VERSION "HNNBNNNYNNNNNNNNNNNNNNNNNNNNNNNNNNNNNNNNNN/4/%%%/4/'%**4NNN///"

NS_ :

BS_:

BU_: Allrad_Haldex AreaView_MQB BAP_Tester Bremse_ABS_MK100 Bremse_ESP_EPB_EBC460Vi Bremse_ESP_EPB_MK100 Bremse_ESP_MK100 Daempfer Gateway_MQB Lenkhilfe_EPS PDC PDC_PLA

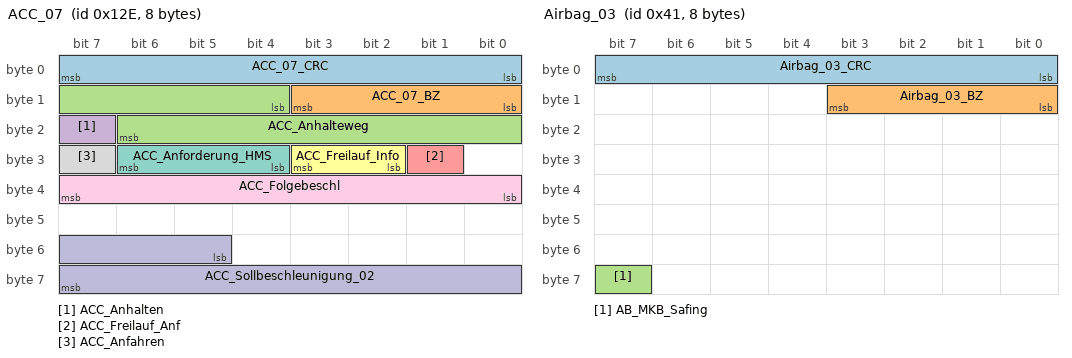
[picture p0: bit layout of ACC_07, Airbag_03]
BO_ 302 ACC_07: 8 Gateway_MQB
 SG_ ACC_07_CRC : 0|8@1+ (1,0) [0|255] ""  Bremse_ESP_EPB_EBC460Vi,Bremse_ESP_EPB_MK100,Bremse_ESP_MK100
 SG_ ACC_07_BZ : 8|4@1+ (1,0) [0|15] ""  Bremse_ESP_EPB_EBC460Vi,Bremse_ESP_EPB_MK100,Bremse_ESP_MK100
 SG_ ACC_Anhalteweg : 12|11@1+ (0.01,0) [0.00|20.45] "Unit_Meter"  Bremse_ESP_EPB_EBC460Vi,Bremse_ESP_EPB_MK100,Bremse_ESP_MK100
 SG_ ACC_Anhalten : 23|1@1+ (1.0,0.0) [0.0|1] ""  Bremse_ESP_EPB_EBC460Vi,Bremse_ESP_EPB_MK100,Bremse_ESP_MK100
 SG_ ACC_Freilauf_Anf : 25|1@1+ (1.0,0.0) [0.0|1] ""  Vector__XXX
 SG_ ACC_Freilauf_Info : 26|2@1+ (1.0,0.0) [0.0|3] ""  Vector__XXX
 SG_ ACC_Anforderung_HMS : 28|3@1+ (1.0,0.0) [0.0|7] ""  Vector__XXX
 SG_ ACC_Anfahren : 31|1@1+ (1.0,0.0) [0.0|1] ""  Bremse_ESP_EPB_EBC460Vi,Bremse_ESP_EPB_MK100,Bremse_ESP_MK100
 SG_ ACC_Folgebeschl : 32|8@1+ (0.03,-4.6) [-4.60|2.99] "Unit_MeterPerSeconSquar"  Vector__XXX
 SG_ ACC_Sollbeschleunigung_02 : 53|11@1+ (0.005,-7.22) [-7.220|3.005] "Unit_MeterPerSeconSquar"  Daempfer

BO_ 279 ACC_10: 8 Gateway_MQB
 SG_ ACC_10_CRC : 0|8@1+ (1,0) [0|255] ""  Bremse_ESP_EPB_EBC460Vi,Bremse_ESP_EPB_MK100,Bremse_ESP_MK100
 SG_ ACC_10_BZ : 8|4@1+ (1,0) [0|15] ""  Bremse_ESP_EPB_EBC460Vi,Bremse_ESP_EPB_MK100,Bremse_ESP_MK100
 SG_ AWV1_Anf_Prefill : 16|1@1+ (1.0,0.0) [0.0|1] ""  Bremse_ESP_EPB_EBC460Vi,Bremse_ESP_EPB_MK100,Bremse_ESP_MK100
 SG_ ANB_CM_Info : 17|1@1+ (1.0,0.0) [0.0|1] ""  Bremse_ESP_EPB_EBC460Vi,Bremse_ESP_EPB_MK100,Bremse_ESP_MK100
 SG_ AWV2_Freigabe : 18|1@1+ (1.0,0.0) [0.0|1] ""  Bremse_ESP_EPB_EBC460Vi,Bremse_ESP_EPB_MK100,Bremse_ESP_MK100
 SG_ AWV1_HBA_Param : 19|2@1+ (1.0,0.0) [0.0|3] ""  Bremse_ESP_EPB_EBC460Vi,Bremse_ESP_EPB_MK100,Bremse_ESP_MK100
 SG_ AWV2_Ruckprofil : 21|3@1+ (1,0) [0|7] ""  Bremse_ESP_EPB_EBC460Vi,Bremse_ESP_EPB_MK100,Bremse_ESP_MK100
 SG_ AWV2_Priowarnung : 24|1@1+ (1.0,0.0) [0.0|1] ""  Vector__XXX
 SG_ ANB_CM_Anforderung : 25|1@1+ (1.0,0.0) [0.0|1] ""  Bremse_ESP_EPB_EBC460Vi,Bremse_ESP_EPB_MK100,Bremse_ESP_MK100
 SG_ ANB_Info_Teilbremsung : 26|1@1+ (1.0,0.0) [0.0|1] ""  Bremse_ESP_EPB_MK100,Bremse_ESP_MK100
 SG_ ANB_Notfallblinken : 27|1@1+ (1.0,0.0) [0.0|1] ""  Vector__XXX
 SG_ ANB_Teilbremsung_Freigabe : 28|1@1+ (1.0,0.0) [0.0|1] ""  Bremse_ESP_EPB_EBC460Vi,Bremse_ESP_EPB_MK100,Bremse_ESP_MK100,Daempfer
 SG_ ANB_Zielbrems_Teilbrems_Verz_Anf : 29|10@1+ (0.024,-20.016) [-20.016|4.536] "Unit_MeterPerSeconSquar"  Bremse_ESP_EPB_EBC460Vi,Bremse_ESP_EPB_MK100,Bremse_ESP_MK100,Daempfer
 SG_ ANB_Zielbremsung_Freigabe : 39|1@1+ (1.0,0.0) [0.0|1] ""  Bremse_ESP_EPB_EBC460Vi,Bremse_ESP_EPB_MK100,Bremse_ESP_MK100,Daempfer
 SG_ AWV_Vorstufe : 40|1@1+ (1.0,0.0) [0.0|1] ""  Bremse_ESP_EPB_EBC460Vi,Bremse_ESP_EPB_MK100,Bremse_ESP_MK100
 SG_ AWV_Halten : 41|1@1+ (1.0,0.0) [0.0|1] ""  Bremse_ESP_EPB_EBC460Vi,Bremse_ESP_EPB_MK100,Bremse_ESP_MK100
 SG_ AWV_CityANB_Auspraegung : 42|1@1+ (1.0,0.0) [0.0|1] ""  Bremse_ESP_EPB_EBC460Vi,Bremse_ESP_EPB_MK100,Bremse_ESP_MK100
 SG_ PCF_Freigabe : 43|1@1+ (1.0,0.0) [0.0|1] ""  Vector__XXX
 SG_ AWV1_ECD_Anlauf : 44|1@1+ (1.0,0.0) [0.0|1] ""  Bremse_ESP_EPB_EBC460Vi,Bremse_ESP_EPB_MK100,Bremse_ESP_MK100
 SG_ PCF_Time_to_collision : 56|8@1+ (0.01,0) [0.00|2.50] "Unit_Secon"  Vector__XXX

BO_ 64 Airbag_01: 8 Gateway_MQB
 SG_ Airbag_01_CRC : 0|8@1+ (1,0) [0|255] ""  Bremse_ABS_MK100,Bremse_ESP_EPB_EBC460Vi,Bremse_ESP_EPB_MK100,Bremse_ESP_MK100
 SG_ Airbag_01_BZ : 8|4@1+ (1,0) [0|15] ""  Bremse_ABS_MK100,Bremse_ESP_EPB_EBC460Vi,Bremse_ESP_EPB_MK100,Bremse_ESP_MK100
 SG_ AB_RGS_Anst : 12|4@1+ (1.0,0.0) [0.0|15] ""  Vector__XXX
 SG_ AB_Front_Crash : 16|1@1+ (1.0,0.0) [0.0|1] ""  Bremse_ESP_EPB_EBC460Vi,Bremse_ESP_EPB_MK100
 SG_ AB_Heck_Crash : 17|1@1+ (1.0,0.0) [0.0|1] ""  Bremse_ESP_EPB_EBC460Vi,Bremse_ESP_EPB_MK100
 SG_ AB_SF_Crash : 18|1@1+ (1.0,0.0) [0.0|1] ""  Bremse_ESP_EPB_EBC460Vi,Bremse_ESP_EPB_MK100
 SG_ AB_SB_Crash : 19|1@1+ (1.0,0.0) [0.0|1] ""  Bremse_ESP_EPB_EBC460Vi,Bremse_ESP_EPB_MK100
 SG_ AB_Rollover_Crash : 20|1@1+ (1.0,0.0) [0.0|1] ""  Bremse_ABS_MK100,Bremse_ESP_EPB_EBC460Vi,Bremse_ESP_EPB_MK100,Bremse_ESP_MK100
 SG_ AB_Crash_Int : 21|3@1+ (1.0,0.0) [0.0|7] ""  Bremse_ABS_MK100,Bremse_ESP_EPB_EBC460Vi,Bremse_ESP_EPB_MK100,Bremse_ESP_MK100
 SG_ AB_Lampe : 24|1@1+ (1.0,0.0) [0.0|1] ""  Vector__XXX
 SG_ AB_Deaktiviert : 25|1@1+ (1.0,0.0) [0.0|1] ""  Vector__XXX
 SG_ AB_VB_deaktiviert : 26|1@1+ (1.0,0.0) [0.0|1] ""  Vector__XXX
 SG_ AB_Systemfehler : 27|1@1+ (1.0,0.0) [0.0|1] ""  Vector__XXX
 SG_ AB_Diagnose : 28|1@1+ (1.0,0.0) [0.0|1] ""  Vector__XXX
 SG_ AB_Stellgliedtest : 29|1@1+ (1.0,0.0) [0.0|1] ""  Vector__XXX
 SG_ AB_Erh_Auf_VB : 30|2@1+ (1.0,0.0) [0.0|3] ""  Vector__XXX
 SG_ AB_Gurtwarn_VF : 32|1@1+ (1.0,0.0) [0.0|1] ""  PDC,PDC_PLA
 SG_ AB_Gurtwarn_VB : 33|1@1+ (1.0,0.0) [0.0|1] ""  PDC,PDC_PLA
 SG_ AB_Anzeige_Fussg : 34|2@1+ (1.0,0.0) [0.0|3] ""  Vector__XXX
 SG_ AB_Texte_AKS : 36|2@1+ (1.0,0.0) [0.0|3] ""  Vector__XXX
 SG_ AB_PAO_Leuchte_Anf : 38|1@1+ (1.0,0.0) [0.0|1] ""  Vector__XXX
 SG_ AB_MKB_gueltig : 39|1@1+ (1.0,0.0) [0.0|1] ""  Bremse_ESP_EPB_EBC460Vi,Bremse_ESP_EPB_MK100,Bremse_ESP_MK100
 SG_ AB_MKB_Anforderung : 40|1@1+ (1.0,0.0) [0.0|1] ""  Bremse_ESP_EPB_EBC460Vi,Bremse_ESP_EPB_MK100,Bremse_ESP_MK100
 SG_ AB_Versorgungsspannung : 41|1@1+ (1.0,0.0) [0.0|1] ""  Vector__XXX
 SG_ AB_Deaktivierung_HV : 42|3@1+ (1.0,0.0) [0.0|7] ""  Vector__XXX
 SG_ AB_EDR_Trigger : 45|2@1+ (1.0,0.0) [0.0|3] ""  Vector__XXX
 SG_ SC_Masterzeit_Offset : 53|2@1+ (5.08,0) [0.00|15.24] "Unit_Secon"  Bremse_ESP_EPB_EBC460Vi,Bremse_ESP_EPB_MK100,Bremse_ESP_MK100,PDC_PLA
 SG_ SC_Masterzeit : 57|7@1+ (0.04,0) [0.00|5.04] "Unit_Secon"  Bremse_ESP_EPB_EBC460Vi,Bremse_ESP_EPB_MK100,Bremse_ESP_MK100,PDC_PLA

BO_ 1312 Airbag_02: 8 Gateway_MQB
 SG_ Airbag_02_CRC : 0|8@1+ (1,0) [0|255] ""  Vector__XXX
 SG_ Airbag_02_BZ : 8|4@1+ (1,0) [0|15] ""  Vector__XXX
 SG_ LoGeWa_Event_Kombiwarnung : 12|4@1+ (1.0,0.0) [0.0|15] ""  Vector__XXX
 SG_ AB_Anforderung_eCall : 16|1@1+ (1.0,0.0) [0.0|1] ""  Vector__XXX
 SG_ AB_Anprall_Seite_Beifahrer : 17|1@1+ (1.0,0.0) [0.0|1] ""  Vector__XXX
 SG_ AB_Anprall_Rollover : 18|1@1+ (1.0,0.0) [0.0|1] ""  Vector__XXX
 SG_ AB_Anprall_FGS : 19|1@1+ (1.0,0.0) [0.0|1] ""  Vector__XXX
 SG_ AB_Anprall_Front_Beifahrer : 20|1@1+ (1.0,0.0) [0.0|1] ""  Vector__XXX
 SG_ AB_Anprall_Front_Fahrer : 21|1@1+ (1.0,0.0) [0.0|1] ""  Vector__XXX
 SG_ AB_Anprall_Heck_Beifahrer : 22|1@1+ (1.0,0.0) [0.0|1] ""  Vector__XXX
 SG_ AB_Anprall_Heck_Fahrer : 23|1@1+ (1.0,0.0) [0.0|1] ""  Vector__XXX
 SG_ AB_Wickelklappung_Reihe2_MI : 24|2@1+ (1.0,0.0) [0.0|3] ""  Vector__XXX
 SG_ AB_Belegung_VB : 26|2@1+ (1.0,0.0) [0.0|3] ""  PDC,PDC_PLA
 SG_ AB_Abschaltanf_SIH_BF : 28|1@1+ (1.0,0.0) [0.0|1] ""  Vector__XXX
 SG_ AB_Anprall_Seite_Fahrer : 29|1@1+ (1.0,0.0) [0.0|1] ""  Vector__XXX
 SG_ SC_PAO_Schriftzug_Anf : 30|2@1+ (1.0,0.0) [0.0|3] ""  Vector__XXX
 SG_ SC_PAO_ON_Anf : 32|2@1+ (1.0,0.0) [0.0|3] ""  Vector__XXX
 SG_ SC_PAO_OFF_Anf : 34|2@1+ (1.0,0.0) [0.0|3] ""  Vector__XXX
 SG_ AB_Crashschwere : 36|3@1+ (1.0,0.0) [0.0|7] ""  Vector__XXX
 SG_ AB_Anforderung_USM : 39|1@1+ (1.0,0.0) [0.0|1] ""  Vector__XXX
 SG_ AB_Gurtschloss_FA : 40|2@1+ (1.0,0.0) [0.0|3] ""  Bremse_ABS_MK100,Bremse_ESP_EPB_EBC460Vi,Bremse_ESP_EPB_MK100,Bremse_ESP_MK100,PDC,PDC_PLA
 SG_ AB_Gurtschloss_BF : 42|2@1+ (1.0,0.0) [0.0|3] ""  PDC,PDC_PLA
 SG_ AB_Gurtschloss_Reihe2_FA : 44|2@1+ (1.0,0.0) [0.0|3] ""  PDC
 SG_ AB_Gurtschloss_Reihe2_MI : 46|2@1+ (1.0,0.0) [0.0|3] ""  PDC
 SG_ AB_Gurtschloss_Reihe2_BF : 48|2@1+ (1.0,0.0) [0.0|3] ""  PDC
 SG_ AB_Gurtschloss_Reihe3_FA : 50|2@1+ (1.0,0.0) [0.0|3] ""  PDC
 SG_ AB_Gurtschloss_Reihe3_MI : 52|2@1+ (1.0,0.0) [0.0|3] ""  PDC
 SG_ AB_Gurtschloss_Reihe3_BF : 54|2@1+ (1.0,0.0) [0.0|3] ""  PDC
 SG_ AB_Sitzpos_Sens_FA : 56|2@1+ (1.0,0.0) [0.0|3] ""  Vector__XXX
 SG_ AB_Sitzpos_Sens_BF : 58|2@1+ (1.0,0.0) [0.0|3] ""  Vector__XXX
 SG_ AB_Wickelklappung_Reihe2_BF : 60|2@1+ (1.0,0.0) [0.0|3] ""  Vector__XXX
 SG_ AB_Wickelklappung_Reihe2_FA : 62|2@1+ (1.0,0.0) [0.0|3] ""  Vector__XXX

BO_ 65 Airbag_03: 8 Gateway_MQB
 SG_ Airbag_03_CRC : 0|8@1+ (1,0) [0|255] ""  Bremse_ESP_EPB_EBC460Vi,Bremse_ESP_EPB_MK100,Bremse_ESP_MK100
 SG_ Airbag_03_BZ : 8|4@1+ (1,0) [0|15] ""  Bremse_ESP_EPB_EBC460Vi,Bremse_ESP_EPB_MK100,Bremse_ESP_MK100
 SG_ AB_MKB_Safing : 63|1@1+ (1.0,0.0) [0.0|1] ""  Bremse_ESP_EPB_EBC460Vi,Bremse_ESP_EPB_MK100,Bremse_ESP_MK100

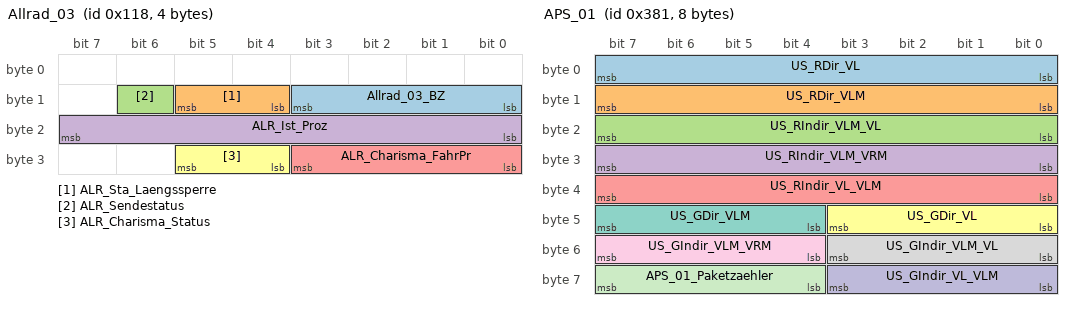
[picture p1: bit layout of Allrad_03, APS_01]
BO_ 280 Allrad_03: 4 Allrad_Haldex
 SG_ Allrad_03_BZ : 8|4@1+ (1,0) [0|15] ""  Bremse_ESP_EPB_EBC460Vi,Bremse_ESP_EPB_MK100,Bremse_ESP_MK100,Gateway_MQB
 SG_ ALR_Sta_Laengssperre : 12|2@1+ (1.0,0.0) [0.0|3] ""  Bremse_ESP_EPB_EBC460Vi,Bremse_ESP_EPB_MK100,Bremse_ESP_MK100,Gateway_MQB
 SG_ ALR_Sendestatus : 14|1@1+ (1.0,0.0) [0.0|1] ""  Gateway_MQB
 SG_ ALR_Ist_Proz : 16|8@1+ (0.4,0) [0.0|100.0] "Unit_PerCent"  Bremse_ESP_EPB_EBC460Vi,Bremse_ESP_EPB_MK100,Bremse_ESP_MK100,Gateway_MQB
 SG_ ALR_Charisma_FahrPr : 24|4@1+ (1.0,0.0) [0.0|15] ""  Gateway_MQB
 SG_ ALR_Charisma_Status : 28|2@1+ (1.0,0.0) [0.0|3] ""  Gateway_MQB

BO_ 897 APS_01: 8 PDC
 SG_ US_RDir_VL : 0|8@1+ (0.02,0) [0.00|5.10] "Unit_Meter"  Gateway_MQB
 SG_ US_RDir_VLM : 8|8@1+ (0.02,0) [0.00|5.10] "Unit_Meter"  Gateway_MQB
 SG_ US_RIndir_VLM_VL : 16|8@1+ (0.02,0) [0.00|5.10] "Unit_Meter"  Gateway_MQB
 SG_ US_RIndir_VLM_VRM : 24|8@1+ (0.02,0) [0.00|5.10] "Unit_Meter"  Gateway_MQB
 SG_ US_RIndir_VL_VLM : 32|8@1+ (0.02,0) [0.00|5.10] "Unit_Meter"  Gateway_MQB
 SG_ US_GDir_VL : 40|4@1+ (0.066,0) [0.000|0.990] ""  Gateway_MQB
 SG_ US_GDir_VLM : 44|4@1+ (0.066,0) [0.000|0.990] ""  Gateway_MQB
 SG_ US_GIndir_VLM_VL : 48|4@1+ (0.066,0) [0.000|0.990] ""  Gateway_MQB
 SG_ US_GIndir_VLM_VRM : 52|4@1+ (0.066,0) [0.000|0.990] ""  Gateway_MQB
 SG_ US_GIndir_VL_VLM : 56|4@1+ (0.066,0) [0.000|0.990] ""  Gateway_MQB
 SG_ APS_01_Paketzaehler : 60|4@1+ (1,0) [0|15] ""  Gateway_MQB

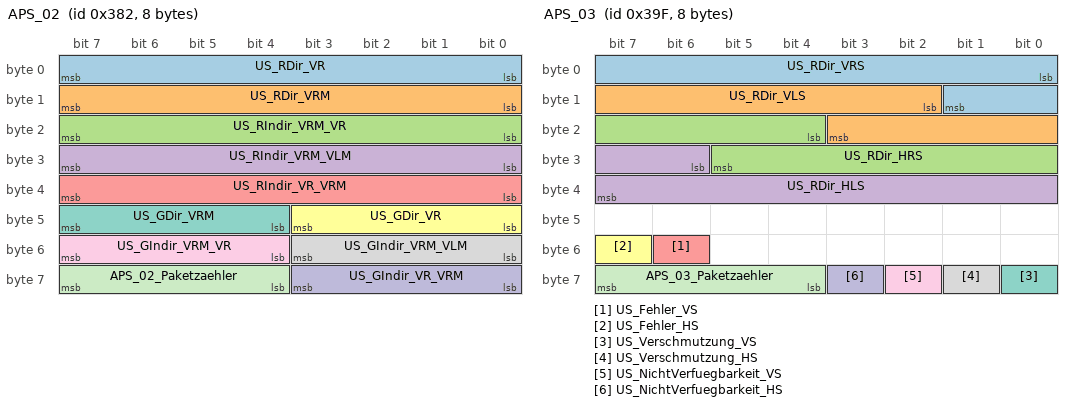
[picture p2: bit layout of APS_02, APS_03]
BO_ 898 APS_02: 8 PDC
 SG_ US_RDir_VR : 0|8@1+ (0.02,0) [0.00|5.10] "Unit_Meter"  Gateway_MQB
 SG_ US_RDir_VRM : 8|8@1+ (0.02,0) [0.00|5.10] "Unit_Meter"  Gateway_MQB
 SG_ US_RIndir_VRM_VR : 16|8@1+ (0.02,0) [0.00|5.10] "Unit_Meter"  Gateway_MQB
 SG_ US_RIndir_VRM_VLM : 24|8@1+ (0.02,0) [0.00|5.10] "Unit_Meter"  Gateway_MQB
 SG_ US_RIndir_VR_VRM : 32|8@1+ (0.02,0) [0.00|5.10] "Unit_Meter"  Gateway_MQB
 SG_ US_GDir_VR : 40|4@1+ (0.066,0) [0.000|0.990] ""  Gateway_MQB
 SG_ US_GDir_VRM : 44|4@1+ (0.066,0) [0.000|0.990] ""  Gateway_MQB
 SG_ US_GIndir_VRM_VLM : 48|4@1+ (0.066,0) [0.000|0.990] ""  Gateway_MQB
 SG_ US_GIndir_VRM_VR : 52|4@1+ (0.066,0) [0.000|0.990] ""  Gateway_MQB
 SG_ US_GIndir_VR_VRM : 56|4@1+ (0.066,0) [0.000|0.990] ""  Gateway_MQB
 SG_ APS_02_Paketzaehler : 60|4@1+ (1,0) [0|15] ""  Gateway_MQB

BO_ 927 APS_03: 8 PDC_PLA
 SG_ US_RDir_VRS : 0|10@1+ (0.015625,0) [0.000000|15.984375] "Unit_Meter"  Gateway_MQB
 SG_ US_RDir_VLS : 10|10@1+ (0.015625,0) [0.000000|15.984375] "Unit_Meter"  Gateway_MQB
 SG_ US_RDir_HRS : 20|10@1+ (0.015625,0) [0.000000|15.984375] "Unit_Meter"  Gateway_MQB
 SG_ US_RDir_HLS : 30|10@1+ (0.015625,0) [0.000000|15.984375] "Unit_Meter"  Gateway_MQB
 SG_ US_Fehler_VS : 54|1@1+ (1.0,0.0) [0.0|1] ""  Gateway_MQB
 SG_ US_Fehler_HS : 55|1@1+ (1.0,0.0) [0.0|1] ""  Gateway_MQB
 SG_ US_Verschmutzung_VS : 56|1@1+ (1.0,0.0) [0.0|1] ""  Gateway_MQB
 SG_ US_Verschmutzung_HS : 57|1@1+ (1.0,0.0) [0.0|1] ""  Gateway_MQB
 SG_ US_NichtVerfuegbarkeit_VS : 58|1@1+ (1.0,0.0) [0.0|1] ""  Gateway_MQB
 SG_ US_NichtVerfuegbarkeit_HS : 59|1@1+ (1.0,0.0) [0.0|1] ""  Gateway_MQB
 SG_ APS_03_Paketzaehler : 60|4@1+ (1,0) [0|15] ""  Gateway_MQB

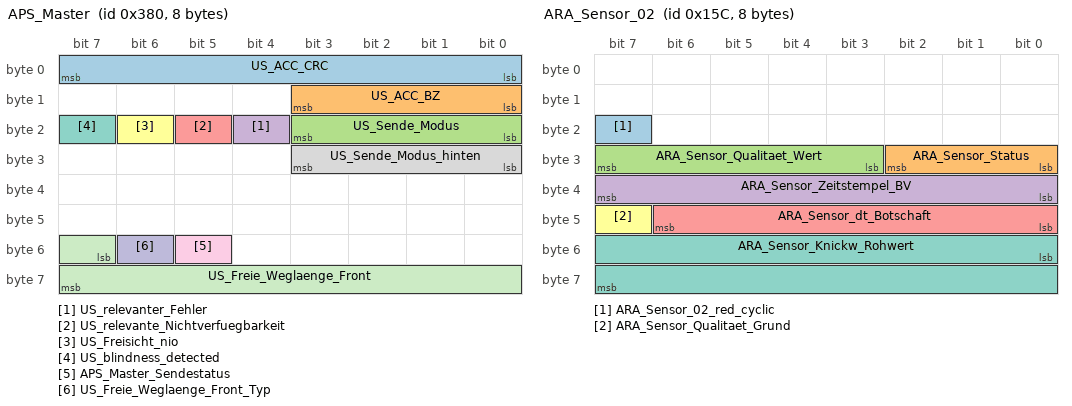
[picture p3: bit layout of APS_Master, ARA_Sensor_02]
BO_ 896 APS_Master: 8 PDC
 SG_ US_ACC_CRC : 0|8@1+ (1,0) [0|255] ""  Gateway_MQB
 SG_ US_ACC_BZ : 8|4@1+ (1,0) [0|15] ""  Gateway_MQB
 SG_ US_Sende_Modus : 16|4@1+ (1.0,0.0) [0.0|15] ""  Gateway_MQB
 SG_ US_relevanter_Fehler : 20|1@1+ (1.0,0.0) [0.0|1] ""  Gateway_MQB
 SG_ US_relevante_Nichtverfuegbarkeit : 21|1@1+ (1.0,0.0) [0.0|1] ""  Gateway_MQB
 SG_ US_Freisicht_nio : 22|1@1+ (1.0,0.0) [0.0|1] ""  Gateway_MQB
 SG_ US_blindness_detected : 23|1@1+ (1.0,0.0) [0.0|1] ""  Gateway_MQB
 SG_ US_Sende_Modus_hinten : 24|4@1+ (1.0,0.0) [0.0|15] ""  Gateway_MQB
 SG_ APS_Master_Sendestatus : 53|1@1+ (1.0,0.0) [0.0|1] ""  Gateway_MQB
 SG_ US_Freie_Weglaenge_Front_Typ : 54|1@1+ (1.0,0.0) [0.0|1] ""  Gateway_MQB
 SG_ US_Freie_Weglaenge_Front : 55|9@1+ (0.01,0) [0.00|5.00] "Unit_Meter"  Gateway_MQB

BO_ 348 ARA_Sensor_02: 8 AreaView_MQB
 SG_ ARA_Sensor_02_red_cyclic : 23|1@1+ (1.0,0.0) [0.0|1] ""  Vector__XXX
 SG_ ARA_Sensor_Status : 24|3@1+ (1.0,0.0) [0.0|7] ""  Vector__XXX
 SG_ ARA_Sensor_Qualitaet_Wert : 27|5@1+ (0.04,0) [0.00|1.24] ""  Vector__XXX
 SG_ ARA_Sensor_Zeitstempel_BV : 32|8@1+ (0.01,0) [0.00|2.55] "Unit_Secon"  Vector__XXX
 SG_ ARA_Sensor_dt_Botschaft : 40|7@1+ (0.01,0) [0.00|1.27] "Unit_Secon"  Vector__XXX
 SG_ ARA_Sensor_Qualitaet_Grund : 47|1@1+ (1.0,0.0) [0.0|1] ""  Vector__XXX
 SG_ ARA_Sensor_Knickw_Rohwert : 48|16@1+ (0.0055,-180) [-180.0000|179.9970] "Unit_DegreOfArc"  Vector__XXX

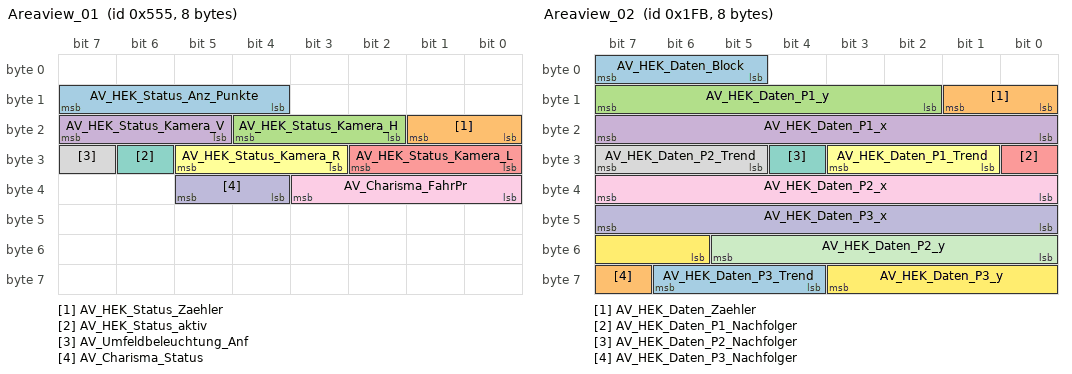
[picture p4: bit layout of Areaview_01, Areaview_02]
BO_ 1365 Areaview_01: 8 AreaView_MQB
 SG_ AV_HEK_Status_Anz_Punkte : 12|4@1+ (1,0) [0|15] ""  PDC,PDC_PLA
 SG_ AV_HEK_Status_Zaehler : 16|2@1+ (1,0) [0|3] ""  PDC,PDC_PLA
 SG_ AV_HEK_Status_Kamera_H : 18|3@1+ (1.0,0.0) [0.0|7] ""  PDC,PDC_PLA
 SG_ AV_HEK_Status_Kamera_V : 21|3@1+ (1.0,0.0) [0.0|7] ""  PDC,PDC_PLA
 SG_ AV_HEK_Status_Kamera_L : 24|3@1+ (1.0,0.0) [0.0|7] ""  PDC,PDC_PLA
 SG_ AV_HEK_Status_Kamera_R : 27|3@1+ (1.0,0.0) [0.0|7] ""  PDC,PDC_PLA
 SG_ AV_HEK_Status_aktiv : 30|1@1+ (1.0,0.0) [0.0|1] ""  PDC,PDC_PLA
 SG_ AV_Umfeldbeleuchtung_Anf : 31|1@1+ (1.0,0.0) [0.0|1] ""  Gateway_MQB
 SG_ AV_Charisma_FahrPr : 32|4@1+ (1.0,0.0) [0.0|15] ""  Gateway_MQB
 SG_ AV_Charisma_Status : 36|2@1+ (1.0,0.0) [0.0|3] ""  Gateway_MQB

BO_ 507 Areaview_02: 8 AreaView_MQB
 SG_ AV_HEK_Daten_Block : 5|3@1+ (1,0) [1|7] ""  PDC,PDC_PLA
 SG_ AV_HEK_Daten_Zaehler : 8|2@1+ (1,0) [0|3] ""  PDC,PDC_PLA
 SG_ AV_HEK_Daten_P1_y : 10|6@1+ (0.1,-3.1) [-3.1|3.1] "Unit_Meter"  PDC,PDC_PLA
 SG_ AV_HEK_Daten_P1_x : 16|8@1+ (0.1,-8.7) [-8.7|16.0] "Unit_Meter"  PDC,PDC_PLA
 SG_ AV_HEK_Daten_P1_Nachfolger : 24|1@1+ (1.0,0.0) [0.0|1] ""  PDC,PDC_PLA
 SG_ AV_HEK_Daten_P1_Trend : 25|3@1+ (1.0,0.0) [0.0|7] ""  PDC,PDC_PLA
 SG_ AV_HEK_Daten_P2_Nachfolger : 28|1@1+ (1.0,0.0) [0.0|1] ""  PDC,PDC_PLA
 SG_ AV_HEK_Daten_P2_Trend : 29|3@1+ (1.0,0.0) [0.0|7] ""  PDC,PDC_PLA
 SG_ AV_HEK_Daten_P2_x : 32|8@1+ (0.1,-8.7) [-8.7|16.0] "Unit_Meter"  PDC,PDC_PLA
 SG_ AV_HEK_Daten_P3_x : 40|8@1+ (0.1,-8.7) [-8.7|16.0] "Unit_Meter"  PDC,PDC_PLA
 SG_ AV_HEK_Daten_P2_y : 48|6@1+ (0.1,-3.1) [-3.1|3.1] "Unit_Meter"  PDC,PDC_PLA
 SG_ AV_HEK_Daten_P3_y : 54|6@1+ (0.1,-3.1) [-3.1|3.1] "Unit_Meter"  PDC,PDC_PLA
 SG_ AV_HEK_Daten_P3_Trend : 60|3@1+ (1.0,0.0) [0.0|7] ""  PDC,PDC_PLA
 SG_ AV_HEK_Daten_P3_Nachfolger : 63|1@1+ (1.0,0.0) [0.0|1] ""  PDC,PDC_PLA

BO_ 2536711680 BAP_Brake_ASG_01: 8 Gateway_MQB
 SG_ BAP_Brake_ASG_01_Header : 0|8@1+ (1.0,0.0) [0.0|255] ""  Bremse_ESP_EPB_EBC460Vi,Bremse_ESP_EPB_MK100,Bremse_ESP_MK100

BO_ 2536711696 BAP_Brake_FSG_01: 8 Bremse_ESP_EPB_EBC460Vi
 SG_ BAP_Brake_FSG_01_Header : 0|8@1+ (1.0,0.0) [0.0|255] ""  Gateway_MQB

BO_ 2536767264 BAP_Debug_Cmd: 8 BAP_Tester
 SG_ BAP_Debug_Cmd : 0|16@1+ (1.0,0.0) [0.0|65535] ""  AreaView_MQB,Bremse_ESP_EPB_EBC460Vi,Bremse_ESP_EPB_MK100,Bremse_ESP_MK100,PDC,PDC_PLA

BO_ 2536767280 BAP_Debug_Data: 8 AreaView_MQB
 SG_ BAP_Debug_Data : 0|64@1+ (1.0,0.0) [0.0|18446744073709551615] ""  BAP_Tester

BO_ 2536704512 BAP_OPS_ASG_01: 8 Gateway_MQB
 SG_ BAP_OPS_ASG_01_Header : 0|8@1+ (1.0,0.0) [0.0|255] ""  PDC,PDC_PLA

BO_ 2536704513 BAP_OPS_ASG_02: 8 AreaView_MQB
 SG_ BAP_OPS_ASG_02_Header : 0|8@1+ (1.0,0.0) [0.0|255] ""  PDC,PDC_PLA

BO_ 2536704528 BAP_OPS_FSG_01: 8 PDC
 SG_ BAP_OPS_FSG_01_Header : 0|8@1+ (1.0,0.0) [0.0|255] ""  AreaView_MQB,Gateway_MQB

BO_ 2536704529 BAP_OPS_FSG_02: 8 PDC
 SG_ BAP_OPS_FSG_02_Header : 0|8@1+ (1.0,0.0) [0.0|255] ""  AreaView_MQB,Gateway_MQB

BO_ 2536703744 BAP_RDK_ASG_01: 8 Gateway_MQB
 SG_ BAP_RDK_ASG_01_Header : 0|8@1+ (1.0,0.0) [0.0|255] ""  Bremse_ESP_EPB_EBC460Vi,Bremse_ESP_EPB_MK100,Bremse_ESP_MK100

BO_ 2536703745 BAP_RDK_ASG_02: 8 Gateway_MQB
 SG_ BAP_RDK_ASG_02_Header : 0|8@1+ (1.0,0.0) [0.0|255] ""  Bremse_ESP_EPB_EBC460Vi,Bremse_ESP_EPB_MK100,Bremse_ESP_MK100

BO_ 2536703760 BAP_RDK_FSG_01: 8 Bremse_ESP_EPB_EBC460Vi
 SG_ BAP_RDK_FSG_01_Header : 0|8@1+ (1.0,0.0) [0.0|255] ""  Gateway_MQB

BO_ 2536704768 BAP_RVC_ASG_01: 8 Gateway_MQB
 SG_ BAP_RVC_ASG_01_Header : 0|8@1+ (1.0,0.0) [0.0|255] ""  AreaView_MQB

BO_ 2536704784 BAP_RVC_FSG_01: 8 AreaView_MQB
 SG_ BAP_RVC_FSG_01_Header : 0|8@1+ (1.0,0.0) [0.0|255] ""  Gateway_MQB

BO_ 869 BEM_05: 8 Gateway_MQB
 SG_ BEM_UBDM : 0|8@1+ (0.05,5) [5.05|17.70] "Unit_Volt"  Vector__XXX
 SG_ NVEM_Ladefreigabe : 8|2@1+ (1.0,0.0) [0.0|3] ""  Vector__XXX
 SG_ NVEM_FMAus_Info : 10|2@1+ (1.0,0.0) [0.0|3] ""  Vector__XXX
 SG_ NVEM_PTC_Sollstufe : 12|2@1+ (1.0,0.0) [0.0|3] ""  Vector__XXX
 SG_ BEM_P_Generator : 16|8@1+ (50,0) [0|12700] "Unit_Watt"  Bremse_ESP_EPB_EBC460Vi,Bremse_ESP_EPB_MK100
 SG_ BEM_n_LLA : 24|2@1+ (1.0,0.0) [0.0|3] ""  Vector__XXX
 SG_ BEM_01_Abschaltstufen : 26|3@1+ (1.0,0.0) [0.0|7] ""  Vector__XXX
 SG_ BEM_Anf_KL : 29|1@1+ (1.0,0.0) [0.0|1] ""  Vector__XXX
 SG_ BEM_StartStopp_Info : 30|2@1+ (1.0,0.0) [0.0|3] ""  Vector__XXX
 SG_ BEM_DFM : 32|5@1+ (3.225,0.025) [0.025|100.000] ""  Vector__XXX
 SG_ BEM_EMLIN_ungueltig : 37|1@1+ (1.0,0.0) [0.0|1] ""  Vector__XXX
 SG_ BEM_Batt_Ab : 38|1@1+ (1.0,0.0) [0.0|1] ""  Lenkhilfe_EPS
 SG_ NVEM_FMAus_I_Verbrauch : 39|5@1+ (5,0) [0|145] "Unit_Amper"  Vector__XXX
 SG_ NVEM_Freilauf_Info : 44|2@1+ (1.0,0.0) [0.0|3] ""  Vector__XXX
 SG_ BEM_NV_NachladAnf : 46|2@1+ (1.0,0.0) [0.0|3] ""  Vector__XXX
 SG_ BEM_Segel_Info : 48|2@1+ (1.0,0.0) [0.0|3] ""  Vector__XXX
 SG_ BEM_HYB_DC_uSollLV : 50|6@1+ (0.1,10.6) [10.6|16.0] "Unit_Volt"  Vector__XXX
 SG_ BEM_HYB_DC_uMinLV : 56|8@1+ (0.1,0) [0.0|25.3] "Unit_Volt"  Vector__XXX

BO_ 870 Blinkmodi_02: 8 Gateway_MQB
 SG_ BM_ZV_auf : 12|1@1+ (1.0,0.0) [0.0|1] ""  Vector__XXX
 SG_ BM_ZV_zu : 13|1@1+ (1.0,0.0) [0.0|1] ""  Vector__XXX
 SG_ BM_DWA_ein : 14|1@1+ (1.0,0.0) [0.0|1] ""  Vector__XXX
 SG_ BM_DWA_Alarm : 15|1@1+ (1.0,0.0) [0.0|1] ""  Vector__XXX
 SG_ BM_Crash : 16|1@1+ (1.0,0.0) [0.0|1] ""  Vector__XXX
 SG_ BM_Panik : 17|1@1+ (1.0,0.0) [0.0|1] ""  Vector__XXX
 SG_ BM_Not_Bremsung : 18|1@1+ (1.0,0.0) [0.0|1] ""  Vector__XXX
 SG_ BM_GDO : 19|1@1+ (1.0,0.0) [0.0|1] ""  Vector__XXX
 SG_ BM_Warnblinken : 20|1@1+ (1.0,0.0) [0.0|1] ""  Bremse_ABS_MK100,Bremse_ESP_EPB_EBC460Vi,Bremse_ESP_EPB_MK100,Bremse_ESP_MK100
 SG_ BM_Taxi_Notalarm : 21|1@1+ (1.0,0.0) [0.0|1] ""  Vector__XXX
 SG_ BM_Telematik : 22|1@1+ (1.0,0.0) [0.0|1] ""  Vector__XXX
 SG_ BM_links : 23|1@1+ (1.0,0.0) [0.0|1] ""  Vector__XXX
 SG_ BM_rechts : 24|1@1+ (1.0,0.0) [0.0|1] ""  Vector__XXX
 SG_ Blinken_li_Fzg_Takt : 25|1@1+ (1.0,0.0) [0.0|1] ""  Vector__XXX
 SG_ Blinken_re_Fzg_Takt : 26|1@1+ (1.0,0.0) [0.0|1] ""  Vector__XXX
 SG_ Blinken_li_Kombi_Takt : 27|1@1+ (1.0,0.0) [0.0|1] ""  Vector__XXX
 SG_ Blinken_re_Kombi_Takt : 28|1@1+ (1.0,0.0) [0.0|1] ""  Vector__XXX
 SG_ BM_NBA_n_codiert_n_aktiv : 29|1@1+ (1.0,0.0) [0.0|1] ""  Vector__XXX
 SG_ BM_NBA_Status : 30|2@1+ (1.0,0.0) [0.0|3] ""  Vector__XXX
 SG_ BM_WBT_Beleuchtung : 32|1@1+ (1.0,0.0) [0.0|1] ""  Vector__XXX
 SG_ BM_HD_Oeffnung_angelernt : 33|1@1+ (1.0,0.0) [0.0|1] ""  Vector__XXX
 SG_ BM_Autobahn : 34|1@1+ (1.0,0.0) [0.0|1] ""  Vector__XXX
 SG_ BM_Rollenmodus_Blinken : 35|1@1+ (1.0,0.0) [0.0|1] ""  Vector__XXX
 SG_ BM_Recas : 36|1@1+ (1.0,0.0) [0.0|1] ""  Vector__XXX
 SG_ BM_Wischblinken : 37|1@1+ (1.0,0.0) [0.0|1] ""  Vector__XXX
 SG_ BM_Telematik_Abbruchgrund : 38|6@1+ (1.0,0.0) [0.0|63] ""  Vector__XXX
 SG_ BM_PiloPa : 44|1@1+ (1.0,0.0) [0.0|1] ""  Vector__XXX

BO_ 2281471488 CCP_Allrad_CRO_01: 8 Vector__XXX
 SG_ CCP_Allrad_CRO_01_Data : 0|64@1+ (1.0,0.0) [0.0|18446744073709551615] ""  Allrad_Haldex

BO_ 2281471489 CCP_Allrad_DTO_01: 8 Allrad_Haldex
 SG_ CCP_Allrad_DTO_01_Data : 0|64@1+ (1.0,0.0) [0.0|18446744073709551615] ""  Vector__XXX

BO_ 2281477632 CCP_Lenkhilfe_CRO_01: 8 Gateway_MQB
 SG_ CCP_Lenkhilfe_CRO_01_Data : 0|64@1+ (1.0,0.0) [0.0|18446744073709551615] ""  Lenkhilfe_EPS

BO_ 2281477634 CCP_Lenkhilfe_CRO_02: 8 Vector__XXX
 SG_ CCP_Lenkhilfe_CRO_02_Data : 0|64@1+ (1.0,0.0) [0.0|18446744073709551615] ""  Lenkhilfe_EPS

BO_ 2281477633 CCP_Lenkhilfe_DTO_01: 8 Lenkhilfe_EPS
 SG_ CCP_Lenkhilfe_DTO_01_Data : 0|64@1+ (1.0,0.0) [0.0|18446744073709551615] ""  Gateway_MQB

BO_ 2281477635 CCP_Lenkhilfe_DTO_02: 8 Lenkhilfe_EPS
 SG_ CCP_Lenkhilfe_DTO_02_Data : 0|64@1+ (1.0,0.0) [0.0|18446744073709551615] ""  Vector__XXX

BO_ 901 Charisma_01: 8 Gateway_MQB
 SG_ CHA_Ziel_FahrPr_AGA : 0|4@1+ (1.0,0.0) [0.0|15] ""  Vector__XXX
 SG_ CHA_Ziel_FahrPr_ESP : 4|4@1+ (1.0,0.0) [0.0|15] ""  Bremse_ESP_EPB_EBC460Vi,Bremse_ESP_EPB_MK100,Bremse_ESP_MK100
 SG_ CHA_Ziel_FahrPr_Freilauf : 8|4@1+ (1.0,0.0) [0.0|15] ""  Vector__XXX
 SG_ CHA_Fahrer_Umschaltung : 14|1@1+ (1.0,0.0) [0.0|1] ""  Bremse_ESP_EPB_EBC460Vi,Bremse_ESP_EPB_MK100,Bremse_ESP_MK100,Daempfer,Lenkhilfe_EPS
 SG_ CHA_Fahrer_Umschaltung_BMA : 15|1@1+ (1.0,0.0) [0.0|1] ""  Vector__XXX
 SG_ CHA_Ziel_FahrPr_MO : 16|4@1+ (1.0,0.0) [0.0|15] ""  Vector__XXX
 SG_ CHA_Ziel_FahrPr_GE : 20|4@1+ (1.0,0.0) [0.0|15] ""  Vector__XXX
 SG_ CHA_Ziel_FahrPr_ALR : 24|4@1+ (1.0,0.0) [0.0|15] ""  Allrad_Haldex
 SG_ CHA_Ziel_FahrPr_MO_BZS : 28|4@1+ (1.0,0.0) [0.0|15] ""  Vector__XXX
 SG_ CHA_Ziel_FahrPr_DR : 32|4@1+ (1.0,0.0) [0.0|15] ""  Daempfer
 SG_ CHA_Ziel_FahrPr_VAQ : 36|4@1+ (1.0,0.0) [0.0|15] ""  Vector__XXX
 SG_ CHA_Ziel_FahrPr_AFS : 40|4@1+ (1.0,0.0) [0.0|15] ""  Vector__XXX
 SG_ CHA_Ziel_FahrPr_RGS : 44|4@1+ (1.0,0.0) [0.0|15] ""  Vector__XXX
 SG_ CHA_Ziel_FahrPr_EPS : 48|4@1+ (1.0,0.0) [0.0|15] ""  Lenkhilfe_EPS
 SG_ CHA_Ziel_FahrPr_ACC : 52|4@1+ (1.0,0.0) [0.0|15] ""  Vector__XXX
 SG_ CHA_Ziel_FahrPr_SAK : 56|4@1+ (1.0,0.0) [0.0|15] ""  Vector__XXX
 SG_ CHA_Ziel_FahrPr_MO_StSt : 60|4@1+ (1.0,0.0) [0.0|15] ""  Vector__XXX

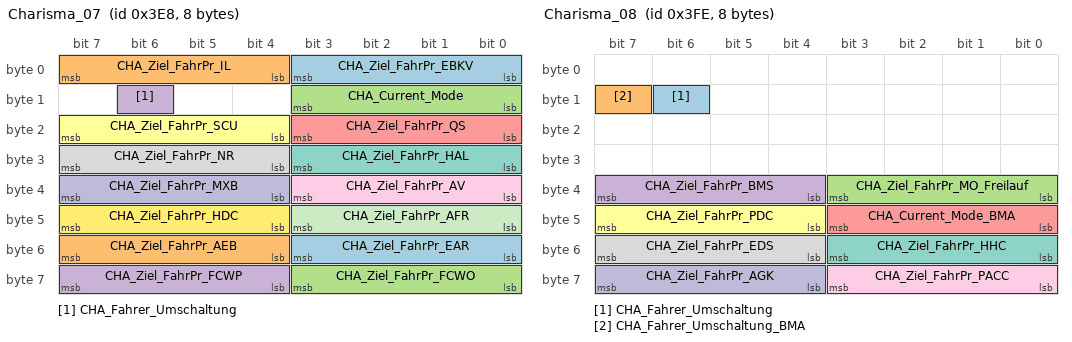
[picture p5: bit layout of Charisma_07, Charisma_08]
BO_ 1000 Charisma_07: 8 Gateway_MQB
 SG_ CHA_Ziel_FahrPr_EBKV : 0|4@1+ (1.0,0.0) [0.0|15] ""  Vector__XXX
 SG_ CHA_Ziel_FahrPr_IL : 4|4@1+ (1.0,0.0) [0.0|15] ""  Vector__XXX
 SG_ CHA_Current_Mode : 8|4@1+ (1.0,0.0) [0.0|15] ""  Vector__XXX
 SG_ CHA_Fahrer_Umschaltung : 14|1@1+ (1.0,0.0) [0.0|1] ""  Bremse_ESP_EPB_EBC460Vi,Bremse_ESP_EPB_MK100,Bremse_ESP_MK100
 SG_ CHA_Ziel_FahrPr_QS : 16|4@1+ (1.0,0.0) [0.0|15] ""  Vector__XXX
 SG_ CHA_Ziel_FahrPr_SCU : 20|4@1+ (1.0,0.0) [0.0|15] ""  Vector__XXX
 SG_ CHA_Ziel_FahrPr_HAL : 24|4@1+ (1.0,0.0) [0.0|15] ""  Vector__XXX
 SG_ CHA_Ziel_FahrPr_NR : 28|4@1+ (1.0,0.0) [0.0|15] ""  Vector__XXX
 SG_ CHA_Ziel_FahrPr_AV : 32|4@1+ (1.0,0.0) [0.0|15] ""  AreaView_MQB,PDC,PDC_PLA
 SG_ CHA_Ziel_FahrPr_MXB : 36|4@1+ (1.0,0.0) [0.0|15] ""  Vector__XXX
 SG_ CHA_Ziel_FahrPr_AFR : 40|4@1+ (1.0,0.0) [0.0|15] ""  Vector__XXX
 SG_ CHA_Ziel_FahrPr_HDC : 44|4@1+ (1.0,0.0) [0.0|15] ""  Bremse_ESP_EPB_EBC460Vi,Bremse_ESP_EPB_MK100,Bremse_ESP_MK100
 SG_ CHA_Ziel_FahrPr_EAR : 48|4@1+ (1.0,0.0) [0.0|15] ""  Vector__XXX
 SG_ CHA_Ziel_FahrPr_AEB : 52|4@1+ (1.0,0.0) [0.0|15] ""  Vector__XXX
 SG_ CHA_Ziel_FahrPr_FCWO : 56|4@1+ (1.0,0.0) [0.0|15] ""  Vector__XXX
 SG_ CHA_Ziel_FahrPr_FCWP : 60|4@1+ (1.0,0.0) [0.0|15] ""  Vector__XXX

BO_ 1022 Charisma_08: 8 Gateway_MQB
 SG_ CHA_Fahrer_Umschaltung : 14|1@1+ (1.0,0.0) [0.0|1] ""  Vector__XXX
 SG_ CHA_Fahrer_Umschaltung_BMA : 15|1@1+ (1.0,0.0) [0.0|1] ""  Vector__XXX
 SG_ CHA_Ziel_FahrPr_MO_Freilauf : 32|4@1+ (1.0,0.0) [0.0|15] ""  Vector__XXX
 SG_ CHA_Ziel_FahrPr_BMS : 36|4@1+ (1.0,0.0) [0.0|15] ""  Vector__XXX
 SG_ CHA_Current_Mode_BMA : 40|4@1+ (1.0,0.0) [0.0|15] ""  Vector__XXX
 SG_ CHA_Ziel_FahrPr_PDC : 44|4@1+ (1.0,0.0) [0.0|15] ""  PDC,PDC_PLA
 SG_ CHA_Ziel_FahrPr_HHC : 48|4@1+ (1.0,0.0) [0.0|15] ""  Bremse_ESP_EPB_MK100,Bremse_ESP_MK100
 SG_ CHA_Ziel_FahrPr_EDS : 52|4@1+ (1.0,0.0) [0.0|15] ""  Bremse_ESP_EPB_MK100,Bremse_ESP_MK100
 SG_ CHA_Ziel_FahrPr_PACC : 56|4@1+ (1.0,0.0) [0.0|15] ""  Vector__XXX
 SG_ CHA_Ziel_FahrPr_AGK : 60|4@1+ (1.0,0.0) [0.0|15] ""  Vector__XXX

BO_ 918 Daempfer_01: 8 Daempfer
 SG_ Daempfer_01_CRC : 0|8@1+ (1,0) [0|255] ""  Gateway_MQB
 SG_ Daempfer_01_BZ : 8|4@1+ (1,0) [0|15] ""  Gateway_MQB
 SG_ DR_Systemstatus : 12|3@1+ (1.0,0.0) [0.0|7] ""  Gateway_MQB
 SG_ LF_Texte : 15|2@1+ (1.0,0.0) [0.0|3] ""  Gateway_MQB
 SG_ DR_Taster : 17|1@1+ (1.0,0.0) [0.0|1] ""  Gateway_MQB
 SG_ DR_Gelbe_Warnlampe : 18|2@1+ (1.0,0.0) [0.0|3] ""  Gateway_MQB
 SG_ DR_Daempferreg_Texte : 20|4@1+ (1.0,0.0) [0.0|15] ""  Gateway_MQB
 SG_ DR_Charisma_FahrPr : 24|4@1+ (1.0,0.0) [0.0|15] ""  Gateway_MQB
 SG_ DR_Charisma_Status : 28|2@1+ (1.0,0.0) [0.0|3] ""  Gateway_MQB
 SG_ DR_Fahrzeugart : 32|4@1+ (1.0,0.0) [0.0|15] ""  Gateway_MQB
 SG_ LF_Warnung_Prio1 : 36|2@1+ (1.0,0.0) [0.0|3] ""  Gateway_MQB
 SG_ LF_Warnung_Prio2 : 38|2@1+ (1.0,0.0) [0.0|3] ""  Gateway_MQB
 SG_ DR_DynAGL_Warnlampe : 40|1@1+ (1.0,0.0) [0.0|1] ""  Gateway_MQB
 SG_ DR_Rote_Warnlampe : 41|2@1+ (1.0,0.0) [0.0|3] ""  Gateway_MQB
 SG_ NI_Status : 43|3@1+ (1.0,0.0) [0.0|7] ""  Gateway_MQB
 SG_ NR_Niveaufunktion_aktiv : 46|2@1+ (1.0,0.0) [0.0|3] ""  Gateway_MQB
 SG_ DR_DynAGL_Anf_im_Leerlauf : 48|1@1+ (1.0,0.0) [0.0|1] ""  Gateway_MQB
 SG_ DR_DynAGL_Anf_Entkopplung : 49|1@1+ (1.0,0.0) [0.0|1] ""  Gateway_MQB

BO_ 2617014784 DEV_Allrad_Resp_00: 8 Allrad_Haldex
 SG_ DEV_Allrad_Resp_00_Data : 0|64@1+ (1.0,0.0) [0.0|18446744073709551615] ""  Vector__XXX

BO_ 2617014785 DEV_Allrad_Resp_01: 8 Allrad_Haldex
 SG_ DEV_Allrad_Resp_01_Data : 0|64@1+ (1.0,0.0) [0.0|18446744073709551615] ""  Vector__XXX

BO_ 2617014786 DEV_Allrad_Resp_02: 8 Allrad_Haldex
 SG_ DEV_Allrad_Resp_02_Data : 0|64@1+ (1.0,0.0) [0.0|18446744073709551615] ""  Vector__XXX

BO_ 2617014787 DEV_Allrad_Resp_03: 8 Allrad_Haldex
 SG_ DEV_Allrad_Resp_03_Data : 0|64@1+ (1.0,0.0) [0.0|18446744073709551615] ""  Vector__XXX

BO_ 2617014788 DEV_Allrad_Resp_04: 8 Allrad_Haldex
 SG_ DEV_Allrad_Resp_04_Data : 0|64@1+ (1.0,0.0) [0.0|18446744073709551615] ""  Vector__XXX

BO_ 2617014789 DEV_Allrad_Resp_05: 8 Allrad_Haldex
 SG_ DEV_Allrad_Resp_05_Data : 0|64@1+ (1.0,0.0) [0.0|18446744073709551615] ""  Vector__XXX

BO_ 2617014790 DEV_Allrad_Resp_06: 8 Allrad_Haldex
 SG_ DEV_Allrad_Resp_06_Data : 0|64@1+ (1.0,0.0) [0.0|18446744073709551615] ""  Vector__XXX

BO_ 2617014791 DEV_Allrad_Resp_07: 8 Allrad_Haldex
 SG_ DEV_Allrad_Resp_07_Data : 0|64@1+ (1.0,0.0) [0.0|18446744073709551615] ""  Vector__XXX

BO_ 2617199107 DEV_AreaViewHEK_00: 8 AreaView_MQB
 SG_ DEV_AreaViewHEK_00_Data : 0|64@1+ (1.0,0.0) [0.0|18446744073709551615] ""  Vector__XXX

BO_ 2617199108 DEV_AreaViewHEK_01: 8 AreaView_MQB
 SG_ DEV_AreaViewHEK_01_Data : 0|64@1+ (1.0,0.0) [0.0|18446744073709551615] ""  Vector__XXX

BO_ 2617199109 DEV_AreaViewHEK_02: 8 AreaView_MQB
 SG_ DEV_AreaViewHEK_02_Data : 0|64@1+ (1.0,0.0) [0.0|18446744073709551615] ""  Vector__XXX

BO_ 2617199110 DEV_AreaViewHEK_03: 8 AreaView_MQB
 SG_ DEV_AreaViewHEK_03_Data : 0|64@1+ (1.0,0.0) [0.0|18446744073709551615] ""  Vector__XXX

BO_ 2617199111 DEV_AreaViewHEK_04: 8 AreaView_MQB
 SG_ DEV_AreaViewHEK_04_Data : 0|64@1+ (1.0,0.0) [0.0|18446744073709551615] ""  Vector__XXX

BO_ 2617199112 DEV_AreaViewHEK_05: 8 AreaView_MQB
 SG_ DEV_AreaViewHEK_05_Data : 0|64@1+ (1.0,0.0) [0.0|18446744073709551615] ""  Vector__XXX

BO_ 2617199113 DEV_AreaViewHEK_06: 8 AreaView_MQB
 SG_ DEV_AreaViewHEK_06_Data : 0|64@1+ (1.0,0.0) [0.0|18446744073709551615] ""  Vector__XXX

BO_ 2617199114 DEV_AreaViewHEK_07: 8 AreaView_MQB
 SG_ DEV_AreaViewHEK_07_Data : 0|64@1+ (1.0,0.0) [0.0|18446744073709551615] ""  Vector__XXX

BO_ 2617199115 DEV_AreaViewHEK_08: 8 AreaView_MQB
 SG_ DEV_AreaViewHEK_08_Data : 0|64@1+ (1.0,0.0) [0.0|18446744073709551615] ""  Vector__XXX

BO_ 2617199116 DEV_AreaViewHEK_09: 8 AreaView_MQB
 SG_ DEV_AreaViewHEK_09_Data : 0|64@1+ (1.0,0.0) [0.0|18446744073709551615] ""  Vector__XXX

BO_ 2617199117 DEV_AreaViewHEK_10: 8 AreaView_MQB
 SG_ DEV_AreaViewHEK_10_Data : 0|64@1+ (1.0,0.0) [0.0|18446744073709551615] ""  Vector__XXX

BO_ 2617199118 DEV_AreaViewHEK_11: 8 AreaView_MQB
 SG_ DEV_AreaViewHEK_11_Data : 0|64@1+ (1.0,0.0) [0.0|18446744073709551615] ""  Vector__XXX

BO_ 2617199119 DEV_AreaViewHEK_12: 8 AreaView_MQB
 SG_ DEV_AreaViewHEK_12_Data : 0|64@1+ (1.0,0.0) [0.0|18446744073709551615] ""  Vector__XXX

BO_ 2617199120 DEV_AreaViewHEK_13: 8 AreaView_MQB
 SG_ DEV_AreaViewHEK_13_Data : 0|64@1+ (1.0,0.0) [0.0|18446744073709551615] ""  Vector__XXX

BO_ 2617199121 DEV_AreaViewHEK_14: 8 AreaView_MQB
 SG_ DEV_AreaViewHEK_14_Data : 0|64@1+ (1.0,0.0) [0.0|18446744073709551615] ""  Vector__XXX

BO_ 2617199122 DEV_AreaViewHEK_15: 8 AreaView_MQB
 SG_ DEV_AreaViewHEK_15_Data : 0|64@1+ (1.0,0.0) [0.0|18446744073709551615] ""  Vector__XXX

BO_ 2617217541 DEV_Daempfer_Req_05: 8 Vector__XXX
 SG_ DEV_Daempfer_Req_05_Data : 0|64@1+ (1.0,0.0) [0.0|18446744073709551615] ""  Daempfer

BO_ 2617217542 DEV_Daempfer_Req_06: 8 Vector__XXX
 SG_ DEV_Daempfer_Req_06_Data : 0|64@1+ (1.0,0.0) [0.0|18446744073709551615] ""  Daempfer

BO_ 2617217536 DEV_Daempfer_Resp_00: 8 Daempfer
 SG_ DEV_Daempfer_Resp_00_Data : 0|64@1+ (1.0,0.0) [0.0|18446744073709551615] ""  Vector__XXX

BO_ 2617217537 DEV_Daempfer_Resp_01: 8 Daempfer
 SG_ DEV_Daempfer_Resp_01_Data : 0|64@1+ (1.0,0.0) [0.0|18446744073709551615] ""  Vector__XXX

BO_ 2617152000 DEV_EPB_Resp_00: 8 Bremse_ESP_EPB_EBC460Vi
 SG_ DEV_EPB_Resp_00_Data : 0|64@1+ (1.0,0.0) [0.0|18446744073709551615] ""  Vector__XXX

BO_ 2617152001 DEV_EPB_Resp_01: 8 Bremse_ESP_EPB_EBC460Vi
 SG_ DEV_EPB_Resp_01_Data : 0|64@1+ (1.0,0.0) [0.0|18446744073709551615] ""  Vector__XXX

BO_ 2617152002 DEV_EPB_Resp_02: 8 Bremse_ESP_EPB_EBC460Vi
 SG_ DEV_EPB_Resp_02_Data : 0|64@1+ (1.0,0.0) [0.0|18446744073709551615] ""  Vector__XXX

BO_ 2617152003 DEV_EPB_Resp_03: 8 Bremse_ESP_EPB_EBC460Vi
 SG_ DEV_EPB_Resp_03_Data : 0|64@1+ (1.0,0.0) [0.0|18446744073709551615] ""  Vector__XXX

BO_ 2617152004 DEV_EPB_Resp_04: 8 Bremse_ESP_EPB_EBC460Vi
 SG_ DEV_EPB_Resp_04_Data : 0|64@1+ (1.0,0.0) [0.0|18446744073709551615] ""  Vector__XXX

BO_ 2617152005 DEV_EPB_Resp_05: 8 Bremse_ESP_EPB_EBC460Vi
 SG_ DEV_EPB_Resp_05_Data : 0|64@1+ (1.0,0.0) [0.0|18446744073709551615] ""  Vector__XXX

BO_ 2617022976 DEV_ESP_Resp_00: 8 Bremse_ABS_MK100
 SG_ DEV_ESP_Resp_00_Data : 0|64@1+ (1.0,0.0) [0.0|18446744073709551615] ""  Vector__XXX

BO_ 2617022977 DEV_ESP_Resp_01: 8 Bremse_ABS_MK100
 SG_ DEV_ESP_Resp_01_Data : 0|64@1+ (1.0,0.0) [0.0|18446744073709551615] ""  Vector__XXX

BO_ 2617022978 DEV_ESP_Resp_02: 8 Bremse_ESP_EPB_EBC460Vi
 SG_ DEV_ESP_Resp_02_Data : 0|64@1+ (1.0,0.0) [0.0|18446744073709551615] ""  Vector__XXX

BO_ 2617022979 DEV_ESP_Resp_03: 8 Bremse_ESP_EPB_EBC460Vi
 SG_ DEV_ESP_Resp_03_Data : 0|64@1+ (1.0,0.0) [0.0|18446744073709551615] ""  Vector__XXX

BO_ 2617022980 DEV_ESP_Resp_04: 8 Bremse_ESP_EPB_EBC460Vi
 SG_ DEV_ESP_Resp_04_Data : 0|64@1+ (1.0,0.0) [0.0|18446744073709551615] ""  Vector__XXX

BO_ 2617022981 DEV_ESP_Resp_05: 8 Bremse_ESP_EPB_EBC460Vi
 SG_ DEV_ESP_Resp_05_Data : 0|64@1+ (1.0,0.0) [0.0|18446744073709551615] ""  Vector__XXX

BO_ 2617020965 DEV_Lenkhilfe_AZG_Req_01: 8 Vector__XXX
 SG_ DEV_Lenkhilfe_AZG_Req_01_Data : 0|64@1+ (1.0,0.0) [0.0|18446744073709551615] ""  Lenkhilfe_EPS

BO_ 2617020962 DEV_Lenkhilfe_AZG_Resp_01: 8 Lenkhilfe_EPS
 SG_ DEV_Lenkhilfe_AZG_Resp_01_Data : 0|64@1+ (1.0,0.0) [0.0|18446744073709551615] ""  Vector__XXX

BO_ 2617020963 DEV_Lenkhilfe_CANTERM_Req_01: 8 Vector__XXX
 SG_ DEV_Lenkhilfe_CANT_Req_01_Data : 0|64@1+ (1.0,0.0) [0.0|18446744073709551615] ""  Lenkhilfe_EPS

BO_ 2617020964 DEV_Lenkhilfe_CANTERM_Resp_01: 8 Lenkhilfe_EPS
 SG_ DEV_Lenkhilfe_CANT_Resp_01_Data : 0|64@1+ (1.0,0.0) [0.0|18446744073709551615] ""  Vector__XXX

BO_ 2617020928 DEV_Lenkhilfe_Resp_00: 8 Lenkhilfe_EPS
 SG_ DEV_Lenkhilfe_Resp_00_Data : 0|64@1+ (1.0,0.0) [0.0|18446744073709551615] ""  Vector__XXX

BO_ 2617020929 DEV_Lenkhilfe_Resp_01: 8 Lenkhilfe_EPS
 SG_ DEV_Lenkhilfe_Resp_01_Data : 0|64@1+ (1.0,0.0) [0.0|18446744073709551615] ""  Vector__XXX

BO_ 2617020930 DEV_Lenkhilfe_Resp_02: 8 Lenkhilfe_EPS
 SG_ DEV_Lenkhilfe_Resp_02_Data : 0|64@1+ (1.0,0.0) [0.0|18446744073709551615] ""  Vector__XXX

BO_ 2617020931 DEV_Lenkhilfe_Resp_03: 8 Lenkhilfe_EPS
 SG_ DEV_Lenkhilfe_Resp_03_Data : 0|64@1+ (1.0,0.0) [0.0|18446744073709551615] ""  Vector__XXX

BO_ 2617020932 DEV_Lenkhilfe_Resp_04: 8 Lenkhilfe_EPS
 SG_ DEV_Lenkhilfe_Resp_04_Data : 0|64@1+ (1.0,0.0) [0.0|18446744073709551615] ""  Vector__XXX

BO_ 2617020933 DEV_Lenkhilfe_Resp_05: 8 Lenkhilfe_EPS
 SG_ DEV_Lenkhilfe_Resp_05_Data : 0|64@1+ (1.0,0.0) [0.0|18446744073709551615] ""  Vector__XXX

BO_TX_BU_ 897 :PDC,PDC_PLA;
BO_TX_BU_ 898 :PDC,PDC_PLA;
BO_TX_BU_ 896 :PDC,PDC_PLA;
BO_TX_BU_ 348 :AreaView_MQB,Gateway_MQB;
BO_TX_BU_ 2536711696 :Bremse_ESP_EPB_EBC460Vi,Bremse_ESP_EPB_MK100,Bremse_ESP_MK100;
BO_TX_BU_ 2536767280 :AreaView_MQB,Bremse_ESP_EPB_EBC460Vi,Bremse_ESP_EPB_MK100,Bremse_ESP_MK100,PDC,PDC_PLA;
BO_TX_BU_ 2536704513 :AreaView_MQB,Gateway_MQB;
BO_TX_BU_ 2536704528 :PDC,PDC_PLA;
BO_TX_BU_ 2536704529 :PDC,PDC_PLA;
BO_TX_BU_ 2536703760 :Bremse_ESP_EPB_EBC460Vi,Bremse_ESP_EPB_MK100,Bremse_ESP_MK100;
BO_TX_BU_ 2617152000 :Bremse_ESP_EPB_EBC460Vi,Bremse_ESP_EPB_MK100;
BO_TX_BU_ 2617152001 :Bremse_ESP_EPB_EBC460Vi,Bremse_ESP_EPB_MK100;
BO_TX_BU_ 2617152002 :Bremse_ESP_EPB_EBC460Vi,Bremse_ESP_EPB_MK100;
BO_TX_BU_ 2617152003 :Bremse_ESP_EPB_EBC460Vi,Bremse_ESP_EPB_MK100;
BO_TX_BU_ 2617152004 :Bremse_ESP_EPB_EBC460Vi,Bremse_ESP_EPB_MK100;
BO_TX_BU_ 2617152005 :Bremse_ESP_EPB_EBC460Vi,Bremse_ESP_EPB_MK100;
BO_TX_BU_ 2617022976 :Bremse_ABS_MK100,Bremse_ESP_EPB_EBC460Vi,Bremse_ESP_EPB_MK100,Bremse_ESP_MK100;
BO_TX_BU_ 2617022977 :Bremse_ABS_MK100,Bremse_ESP_EPB_EBC460Vi,Bremse_ESP_EPB_MK100,Bremse_ESP_MK100;
BO_TX_BU_ 2617022978 :Bremse_ESP_EPB_EBC460Vi,Bremse_ESP_EPB_MK100,Bremse_ESP_MK100;
BO_TX_BU_ 2617022979 :Bremse_ESP_EPB_EBC460Vi,Bremse_ESP_EPB_MK100,Bremse_ESP_MK100;
BO_TX_BU_ 2617022980 :Bremse_ESP_EPB_EBC460Vi,Bremse_ESP_EPB_MK100,Bremse_ESP_MK100;
BO_TX_BU_ 2617022981 :Bremse_ESP_EPB_EBC460Vi,Bremse_ESP_EPB_MK100,Bremse_ESP_MK100;

CM_ "MQB_FCAN_V7.15F Generated by BUSNET NG Produktiv 9.4.2";
CM_ BU_ Allrad_Haldex "Längssperre/Allrad";
CM_ BU_ AreaView_MQB "Areaview MQB";
CM_ BU_ Bremse_ABS_MK100 "Bremse Continental MK100 (ABS)";
CM_ BU_ Bremse_ESP_EPB_EBC460Vi "Bremse TRW EBC460Vi (ESC mit integrierter EPB)";
CM_ BU_ Bremse_ESP_EPB_MK100 "Bremse Continental MK100 (ESC mit integrierter EPB)";
CM_ BU_ Bremse_ESP_MK100 "Bremse Continental MK100 (ESC) ";
CM_ BU_ Daempfer "Geregelter Dämpfer MQB A/B";
CM_ BU_ Gateway_MQB "Separates Gateway MQB A/B/E, MQB A0 Standard+/High";
CM_ BU_ Lenkhilfe_EPS "Elektromechanische Lenkhilfe MQB";
CM_ BU_ PDC "Einparkhilfe MQB/PQ26";
CM_ BU_ PDC_PLA "Einparkhilfe mit integriertem Park-Lenk-Assistenten MQB/PQ26";

CM_ BO_ 302 "ab MQB";
CM_ BO_ 279 "ab MQB";
CM_ BO_ 280 "Allrad im MQB";
CM_ BO_ 869 "ab MQB";
CM_ BO_ 870 "Nur die Kombination des statischen und toggelnden Signals ergibt den Blinktakt für die Hell & Dunkelphase";
CM_ BO_ 901 "ab MQB ohne CHK und mit geänderter Sendeart";

CM_ SG_ 302 ACC_07_CRC "Für MLB:
'Berechnung siehe Lastenheft 'Kommunikationsabsicherung für FlexRay und CAN''

Ab MQB und MLBevo:
'Berechnung siehe Lastenheft 'End-to-End Kommunikationsabsicherung''

Endwerte siehe Begleitdokument 'S-PDU Kennungsfolgen'";
CM_ SG_ 302 ACC_Anfahren "Anforderung Anfahren";
CM_ SG_ 302 ACC_Anforderung_HMS "Bremsanforderung an den Haltemanager";
CM_ SG_ 302 ACC_Anhalten "Im Falle eines gesetzten Bits wird vom ACC ein Anhalten bis in den Stand gewünscht. Das Bit wird von ACC nur unterhalb einer appl. Geschwindigkeitsschwelle gesetzt. Notwendig für die ACCplus-Funktionalität. Nicht für Audi B8 relevant, jedoch im Vorgriff a";
CM_ SG_ 302 ACC_Anhalteweg "Verbleibender Weg bis zum Stillstand";
CM_ SG_ 302 ACC_Folgebeschl "Sollbeschleunigung des ACC-Folgeregler";
CM_ SG_ 302 ACC_Freilauf_Anf "Freilauf-Anforderung durch Energo/ACC";
CM_ SG_ 302 ACC_Freilauf_Info "Freilauf-Freigabe durch Aktiven Teilnehmer Freilauf";
CM_ SG_ 302 ACC_Sollbeschleunigung_02 "Anforderung an den Triebstrangkoordinator , eine 'ACC_Sollbeschleunigung' umzusetzen.";

CM_ SG_ 279 ACC_10_CRC "Für MLB:
'Berechnung siehe Lastenheft 'Kommunikationsabsicherung für FlexRay und CAN''

Ab MQB und MLBevo:
'Berechnung siehe Lastenheft 'End-to-End Kommunikationsabsicherung''

Endwerte siehe Begleitdokument 'S-PDU Kennungsfolgen'";
CM_ SG_ 279 ANB_CM_Anforderung "ANB_CM-Anforderungsbit an das ESP";
CM_ SG_ 279 ANB_CM_Info "Information über die ANB_CM-Ausprägung";
CM_ SG_ 279 ANB_Info_Teilbremsung "Über das Signal s_ANB_Info_Teilbremsung muss das ACC-SG dem ESP-SG dauerhaft beginnend mit einer Teilbremsung-Anforderung mitteilen welche Ausprägung angefordert wird.

Signaldefinition: 
0x0 = Ausprägung 'Standard'
0x1 = Ausprägung 'Erweitert'";
CM_ SG_ 279 ANB_Notfallblinken "Info an das BCM_2 die Warnblinkanlage anzusteuern";
CM_ SG_ 279 ANB_Teilbremsung_Freigabe "Freigabe-Bit der Teilbremsung an das ESP";
CM_ SG_ 279 ANB_Zielbrems_Teilbrems_Verz_Anf "Verzögerungsanforderung der Funktionen Zielbremsung und Teibremsung an das ESP";
CM_ SG_ 279 ANB_Zielbremsung_Freigabe "Freigabe-Bit der Zielbremsung an das ESP";
CM_ SG_ 279 AWV1_Anf_Prefill "Anforderung an ESP, dass die Prefill-Funktion aktiviert werden soll.
Nur Audi B8: Umsetzung der Prefill-Anforderung im ESP nur in Verbindung mit gesetztem Bit 'AWV1_Freigabe'.";
CM_ SG_ 279 AWV1_ECD_Anlauf "Anforderung an ESC, dass die ESP-Pumpe für eine bevorstehende ECD-Regelung aktiviert werden soll.";
CM_ SG_ 279 AWV1_HBA_Param "Anforderung an ESP, welcher HBA-Parametersatz verwendet werden soll. Die Festlegung der Empfindlichkeitsschwellen der verschiedenen Parametersätze erfolgt mit der Applikation des Gesamtsystems ESP/ACC bzw. des HBA.
Nur Audi B8: Umsetzung der Anforderung ";
CM_ SG_ 279 AWV2_Freigabe "Freigabit für die Warnruck-Anforderung an das ESP";
CM_ SG_ 279 AWV2_Priowarnung "Im Falle einer AWV2-Vorwarnung (optisch/akustisch) oder eines AWV2-Bremsruckes soll im LDW eine Fahrerwarnung bzgl. Verlassen der Fahrspur unterdrückt werden. (AWV2 hat Priorität. Eine gleichzeitige LDW-Warnung könnte den Fahrer irritieren.) 
";
CM_ SG_ 279 AWV2_Ruckprofil "Anforderung an ESP, welcher Ruck aus einer Auswahl von max. 7 verschiedenen Ruckprofilen verwendet werden soll. Eine Umsetzung der Ruckanforderung im ESP erfolgt nur mit gesetztem Bit 'AWV2 Freigabe'.";
CM_ SG_ 279 AWV_CityANB_Auspraegung "Plausibilisierung der Codierung der CityANB-Ausprägung im ESP.";
CM_ SG_ 279 AWV_Halten "Anforderung an das ESP, das Fahrzeug nach erfolgter automatischer Bremsung bis in den Stillstand im Stillstand zu halten und eine Fahrer-Überwachung zu aktivieren.";
CM_ SG_ 279 AWV_Vorstufe "Info an das Restfahrzeug, dass in Kürze eine Notbremsung/schnelles Ausweichmanöver erfolgt (Info wird u.a. in Dämpferregelung zur Anpassung der Regelung verwendet)";
CM_ SG_ 279 PCF_Freigabe "Freigabe der Funktion PreCrash-Front";
CM_ SG_ 279 PCF_Time_to_collision "Prädizierter Aufprallzeipunkt des relevanten Objektes";

CM_ SG_ 64 AB_Anzeige_Fussg "Anzeige für ausgelöste Fussgängerschutz-Aktuatorik";
CM_ SG_ 64 AB_Crash_Int "Crash_Intensität_1 = fahrzeugabhängige Reaktionen im Crash
Crash_Intensität_2 = fahrzeugabhängige Reaktionen im Crash
Crash_Intensität_3 = fahrzeugabhängige Reaktionen im Crash

Die jeweiligen fahrzeugabhängigen Reaktionen im Crash sind in einem separ";
CM_ SG_ 64 AB_Deaktiviert "Airbag oder Gurtstraffer wurden per Anpassung deaktiviert: Aktualisierung erst nach Selbsttest";
CM_ SG_ 64 AB_Deaktivierung_HV "Deaktivierung des HV-Systems und der HV-Teilnehmer im Crash (u.a. Hybrid- und Elektrofahrzeuge)";
CM_ SG_ 64 AB_Diagnose "Airbag in Diagnose";
CM_ SG_ 64 AB_EDR_Trigger "Triggerbedingung zur dezentralen Aufzeichnung unfallrelevanter Daten im Event Data Recorder";
CM_ SG_ 64 AB_Erh_Auf_VB "Der Fahrer soll bei einem Statuswechsel des Beifahrerairbags (ausgelöst durch die Beifahrerinsassenerkennung oder den Schlüsselschloßschalter) aufmerksam gemacht werden durch eine Anzeige im Kombi. Nur Audi: gültig für: AB2 (4-Türer AU352), B7, C6, D3";
CM_ SG_ 64 AB_Front_Crash "Bit wird bei Überschreitung der Gurtstraffer-, US- und RdW-Schwelle gesetzt";
CM_ SG_ 64 AB_Gurtwarn_VB "Beifahrer hat Gurt nicht gesteckt, Anzeige im Kombi";
CM_ SG_ 64 AB_Gurtwarn_VF "Fahrer hat Gurt nicht gesteckt, Anzeige im Kombi";
CM_ SG_ 64 AB_Heck_Crash "Wird für alle neu anlaufenden Projekte umgesetzt: AB8.4, Audi8/VW8";
CM_ SG_ 64 AB_Lampe "Sicherheitswarnlampe im Kombi wird vom Airbag-SG angesteuert; Zustand der Lampe wird auf dem CAN-Bus ausgegeben (auch Blinkinformation).";
CM_ SG_ 64 AB_MKB_Anforderung "Anforderung Multi-Kollisions-Bremsung";
CM_ SG_ 64 AB_MKB_gueltig "Multi-Kollisions-Bremsung im Airbag freigeschaltet";
CM_ SG_ 64 AB_PAO_Leuchte_Anf "Anforderung an die Passenger-Airbag-Off Leuchte in der Dachkonsole (ein / aus), Einsatz nur bei PAG";
CM_ SG_ 64 AB_RGS_Anst "PreCrash-Ansteuerung reversibler Gurtstraffer (Aktivierung und Kraftniveau)

10xx = deaktiviert";
CM_ SG_ 64 AB_Rollover_Crash "Wird im B6/B7 Cabrio und New Beetle Cabrio bedient. ";
CM_ SG_ 64 AB_SB_Crash "Z.Zt. nur in Verbindung mit Crash-Intensität >= 100b (Kraftstoffpumpenabschaltung) verwendet.
";
CM_ SG_ 64 AB_SF_Crash "Z.Zt. nur in Verbindung mit Crash-Intensität >= 100b (Kraftstoffpumpenabschaltung) verwendet.";
CM_ SG_ 64 AB_Stellgliedtest "Information, ob Airbag im Stellgliedtest ist, um eine Notrufauflösung beim Stellgliedtest zu verhindern";
CM_ SG_ 64 AB_Systemfehler "Systemfehler Ggf. wird Warnlampe dauernd eingeschaltet.";
CM_ SG_ 64 AB_Texte_AKS "Textanzeige für pyrotechnische Auslösung der aktiven Kopfstütze (AKS)";
CM_ SG_ 64 AB_VB_deaktiviert "Als Option vorgehalten, Beifahrerairbag wurden per Schlüsselschalter oder Insassenerkennung deaktiviert";
CM_ SG_ 64 AB_Versorgungsspannung "Übertragung der Plausibilitätsinformation Kl.15-Last vs. Kl.15-CAN.
Bedienung im Fall Kl.15-Last 'EIN' und Kl.15-CAN 'AUS' mit Ausgabe Warnung/Akustik im Kombi.";
CM_ SG_ 64 Airbag_01_CRC "Für MLB:
'Berechnung siehe Lastenheft 'Kommunikationsabsicherung für FlexRay und CAN''

Ab MQB und MLBevo:
'Berechnung siehe Lastenheft 'End-to-End Kommunikationsabsicherung''

Endwerte siehe Begleitdokument 'S-PDU Kennungsfolgen'";
CM_ SG_ 64 SC_Masterzeit "Masterzeit für alle Objektlisten";
CM_ SG_ 64 SC_Masterzeit_Offset "Erweiterung des Signals SC_Masterzeit um zwei höherwertige Bits, so dass ein Zeitbereich von ~20s (statt 5s) abgedeckt werden kann. Der aus SC_Masterzeit_Offset und SC_Masterzeit zu bildende Zeitstempel wird für die Synchronisation von Ereignissen der Fun";

CM_ SG_ 1312 AB_Abschaltanf_SIH_BF "Die Insassenerkennung auf der Beifahrerseite fordert bei Übertemperatur eine Abschaltung der Sitzheizung an. Die Übertemperatur kann bei niederohmigen Nebenschlüssen der Sitzheizungsmatte als Folge von zu hohem resultierenden Strom auftreten.";
CM_ SG_ 1312 AB_Anforderung_eCall "Trigger für Car2X Steuergerät das ein eCall Ereignis erkannt wurde.";
CM_ SG_ 1312 AB_Anforderung_USM "Trigger für Gateway (OBDC) und MIB/MMI, dass ein USM-Ereignis erkannt wurde.";
CM_ SG_ 1312 AB_Anprall_FGS "Uebermittlung der Lage einer Kollision, Fussgaengerschutz-Aktorik";
CM_ SG_ 1312 AB_Anprall_Front_Beifahrer "Uebermittlung der Lage einer Kollision, Anprallzone Beifahrerseite vorne";
CM_ SG_ 1312 AB_Anprall_Front_Fahrer "Uebermittlung der Lage einer Kollision, Anprallzone Fahrerseite vorne";
CM_ SG_ 1312 AB_Anprall_Heck_Beifahrer "Uebermittlung der Lage einer Kollision, Anprallzone Beifahrerseite hinten";
CM_ SG_ 1312 AB_Anprall_Heck_Fahrer "Uebermittlung der Lage einer Kollision, Anprallzone Fahrerseite hinten";
CM_ SG_ 1312 AB_Anprall_Rollover "Uebermittlung der Lage einer Kollision, Rollover erkannt";
CM_ SG_ 1312 AB_Anprall_Seite_Beifahrer "Uebermittlung der Lage einer Kollision, Anprallzone Beifahrerseite Seite";
CM_ SG_ 1312 AB_Anprall_Seite_Fahrer "Uebermittlung der Lage einer Kollision, Anprallzone Fahrerseite Seite";
CM_ SG_ 1312 AB_Belegung_VB "Belegungserkennung vorne Beifahrer. Wird in US-Steuergeräten über Bladder-Matte bedient, optional bei RdW, falls SBE_EuroNCAP entschieden wird.";
CM_ SG_ 1312 AB_Crashschwere "Übermittlung der Crashschwere an das Gateway (OBDC)";
CM_ SG_ 1312 AB_Gurtschloss_BF "Gurtschlossstatus Beifahrerseite";
CM_ SG_ 1312 AB_Gurtschloss_FA "Gurtschlosstatatus Fahrerseite";
CM_ SG_ 1312 AB_Gurtschloss_Reihe2_BF "Gurtschlossstatus 2. Reihe Beifahrerseite,  Mehrausstattung";
CM_ SG_ 1312 AB_Gurtschloss_Reihe2_FA "Gurtschlossstatus 2. Reihe Fahrerseite, Mehrausstattung";
CM_ SG_ 1312 AB_Gurtschloss_Reihe2_MI "Gurtschlossstatus 2. Reihe Mitte,  Mehrausstattung";
CM_ SG_ 1312 AB_Gurtschloss_Reihe3_BF "Gurtschlossstatus 3. Reihe Beifahrerseite,  Mehrausstattung";
CM_ SG_ 1312 AB_Gurtschloss_Reihe3_FA "Gurtschlossstatus 3. Reihe Fahrerseite,  Mehrausstattung";
CM_ SG_ 1312 AB_Gurtschloss_Reihe3_MI "Gurtschlossstatus 3. Reihe Mitte,  Mehrausstattung";
CM_ SG_ 1312 AB_Sitzpos_Sens_BF "Ausgabe Sitzposition Beifahrer";
CM_ SG_ 1312 AB_Sitzpos_Sens_FA "Ausgabe Sitzposition Fahrer";
CM_ SG_ 1312 AB_Wickelklappung_Reihe2_BF "Status Wickelklappung 2. Reihe Beifahrerseite, Mehrausstattung";
CM_ SG_ 1312 AB_Wickelklappung_Reihe2_FA "Status Wickelklappung 2. Reihe Fahrerseite, Mehrausstattung";
CM_ SG_ 1312 AB_Wickelklappung_Reihe2_MI "Status Wickelklappung 2. Reihe Mitte, Mehrausstattung";
CM_ SG_ 1312 Airbag_02_CRC "Für MLB:
'Berechnung siehe Lastenheft 'Kommunikationsabsicherung für FlexRay und CAN''

Ab MQB und MLBevo:
'Berechnung siehe Lastenheft 'End-to-End Kommunikationsabsicherung''

Endwerte siehe Begleitdokument 'S-PDU Kennungsfolgen'";
CM_ SG_ 1312 LoGeWa_Event_Kombiwarnung "Event für Kombiwarnung";
CM_ SG_ 1312 SC_PAO_OFF_Anf "Sollwert für LED 'OFF' in Anzeige Passenger Airbag On/Off";
CM_ SG_ 1312 SC_PAO_ON_Anf "Sollwert für LED 'ON' in Anzeige Passenger Airbag On/Off";
CM_ SG_ 1312 SC_PAO_Schriftzug_Anf "Sollwert für LED 'PASSENGER AIRBAG' in Anzeige Passenger Airbag On/Off";

CM_ SG_ 65 AB_MKB_Safing "Safing für Multi-Kollisions-Bremsung";
CM_ SG_ 65 Airbag_03_CRC "Für MLB:
'Berechnung siehe Lastenheft 'Kommunikationsabsicherung für FlexRay und CAN''

Ab MQB und MLBevo:
'Berechnung siehe Lastenheft 'End-to-End Kommunikationsabsicherung''

Endwerte siehe Begleitdokument 'S-PDU Kennungsfolgen'";

CM_ SG_ 280 ALR_Charisma_FahrPr "MLB: Aktuelles Fahrprogramm des Charisma-Teilnehmers (siehe Systemlastenheft Drive Select)
MQB: Istwert der Kennlinie (siehe Systemlastenheft MQB Charisma)";
CM_ SG_ 280 ALR_Charisma_Status "Systemstatus des Charismateilnehmers

Wert 0x3 ist nur für Fahrzeuge ab MQB relevant
";
CM_ SG_ 280 ALR_Ist_Proz "Istsperrgrad der Längssperre
MQB Haldex: 100% Moment entsprechen 2000 Nm";
CM_ SG_ 280 ALR_Sendestatus "Gibt den Sendestatus der Längssperre an (notwendig für IL-Unterstützung)";
CM_ SG_ 280 ALR_Sta_Laengssperre "Gibt den Status der Längssperre für andere Systeme an";

CM_ SG_ 897 APS_01_Paketzaehler "Wird verwendet zur Verifizierung der Botschafsreihenfolge
APS_Master
APS_01
APS_02

";
CM_ SG_ 897 US_GDir_VL "Güte der direkten Messung des US-Sensors vorne links";
CM_ SG_ 897 US_GDir_VLM "Güte der direkten Messung des US-Sensors vorne links Mitte";
CM_ SG_ 897 US_GIndir_VL_VLM "Güte der indirekten Messung der US-Sensoren vorne links (Sender) und vorne links Mitte (Empfänger)";
CM_ SG_ 897 US_GIndir_VLM_VL "Güte der indirekten Messung der US-Sensoren vorne links Mitte (Sender) und vorne links (Empfänger)";
CM_ SG_ 897 US_GIndir_VLM_VRM "Güte der indirekten Messung der US-Sensoren vorne links Mitte (Sender) und vorne rechts Mitte (Empfänger)";
CM_ SG_ 897 US_RDir_VL "direkte Messung des US-Sensors vorne links";
CM_ SG_ 897 US_RDir_VLM "direkte Messung des US-Sensors vorne links Mitte";
CM_ SG_ 897 US_RIndir_VL_VLM "indirekte Messung der US-Sensoren vorne links (Sender) und vorne links Mitte (Empfänger)";
CM_ SG_ 897 US_RIndir_VLM_VL "indirekte Messung der US-Sensoren vorne links Mitte (Sender) und vorne links (Empfänger)";
CM_ SG_ 897 US_RIndir_VLM_VRM "indirekte Messung der US-Sensoren vorne links Mitte (Sender) und vorne rechts Mitte (Empfänger)";

CM_ SG_ 898 APS_02_Paketzaehler "Wird verwendet zur Verifizierung der Botschafsreihenfolge
APS_Master
APS_01
APS_02

";
CM_ SG_ 898 US_GDir_VR "Güte der direkten Messung des US-Sensors vorne rechts";
CM_ SG_ 898 US_GDir_VRM "Güte der direkten Messung des US-Sensors vorne rechts Mitte";
CM_ SG_ 898 US_GIndir_VR_VRM "Güte der indirekten Messung der US-Sensoren vorne rechts (Sender) und vorne rechts Mitte (Empfänger)";
CM_ SG_ 898 US_GIndir_VRM_VLM "Güte der indirekten Messung der US-Sensoren vorne rechts Mitte (Sender) und vorne links Mitte (Empfänger)";
CM_ SG_ 898 US_GIndir_VRM_VR "Güte der indirekten Messung der US-Sensoren vorne rechts Mitte (Sender) und vorne rechts (Empfänger)";
CM_ SG_ 898 US_RDir_VR "direkte Messung des US-Sensors vorne rechts";
CM_ SG_ 898 US_RDir_VRM "direkte Messung des US-Sensors vorne rechts Mitte";
CM_ SG_ 898 US_RIndir_VR_VRM "indirekte Messung der US-Sensoren vorne rechts (Sender) und vorne rechts Mitte (Empfänger)";
CM_ SG_ 898 US_RIndir_VRM_VLM "indirekte Messung der US-Sensoren vorne rechts Mitte (Sender) und vorne links Mitte (Empfänger)";
CM_ SG_ 898 US_RIndir_VRM_VR "indirekte Messung der US-Sensoren vorne rechts  Mitte (Sender) und vorne rechts (Empfänger)";

CM_ SG_ 927 APS_03_Paketzaehler "Wird verwendet zur Verifizierung der Botschafsreihenfolge";
CM_ SG_ 927 US_Fehler_HS "Fehler US-Sensor hinten seitlich";
CM_ SG_ 927 US_Fehler_VS "Fehler US-Sensoren vorne seitlich";
CM_ SG_ 927 US_NichtVerfuegbarkeit_HS "Nichtverfuegbarkeit US-Sensoren hinten seitlich";
CM_ SG_ 927 US_NichtVerfuegbarkeit_VS "Nichtverfuegbarkeit US-Sensoren vorne seitlich";
CM_ SG_ 927 US_RDir_HLS "direkte Messung des US-Sensors hinten links seitlich";
CM_ SG_ 927 US_RDir_HRS "direkte Messung des US-Sensors hinten rechts seitlich";
CM_ SG_ 927 US_RDir_VLS "direkte Messung des US-Sensors vorne links seitlich";
CM_ SG_ 927 US_RDir_VRS "direkte Messung des US-Sensors vorne rechts seitlich";
CM_ SG_ 927 US_Verschmutzung_HS "Verschmutzung US-Sensoren hinten seitlich";
CM_ SG_ 927 US_Verschmutzung_VS "Verschmutzung US-Sensoren vorne seitlich";

CM_ SG_ 896 APS_Master_Sendestatus "Gibt den Sendestatus der Botschaft APS_Master an (notwendig für IL-Unterstützung)";
CM_ SG_ 896 US_ACC_CRC "Ab MQB und MLBevo:
'Berechnung siehe Lastenheft 'End-to-End Kommunikationsabsicherung''

Endwerte siehe Begleitdokument 'S-PDU Kennungsfolgen'";
CM_ SG_ 896 US_blindness_detected "US erkennt selbständig eigene Blindheit durch äußere Einflüsse.";
CM_ SG_ 896 US_Freie_Weglaenge_Front "US_Freie Weglaenge vor dem Fahrzeug - lenkwinkelabhängig. Die freie Weglänge kann dabei durch Hindernisse oder den maximalen Sichtbereich beschränkt sein. Siehe Signal US_Freie_Weglaenge_Front_Typ";
CM_ SG_ 896 US_Freie_Weglaenge_Front_Typ "Beschreibt die Begrenzung der freien Weglänge vor dem Fahrzeug. Gehört somit zum Signal US_Freie_Weglaenge_Front. Die freie Weglänge kann bei einem gemessenen Objekt enden oder bei der maximalen Sensorreichweite.";
CM_ SG_ 896 US_Freisicht_nio "Blindheitserkennung
Nach KL15-Ein konnte Freisichtprüfung noch nicht erfüllt werden";
CM_ SG_ 896 US_relevante_Nichtverfuegbarkeit "US erkennt eine Nichtverfuegbarkeit, die Objektdetektion im Frontbereich betreffend, ohne FSP-Eintrag";
CM_ SG_ 896 US_relevanter_Fehler "US erkennt einen Fehler, die Objektdetektion im Frontbereich betreffend, mit FSP-Eintrag.";
CM_ SG_ 896 US_Sende_Modus "US=Ultraschall
US_SendeModus:
0x0: keine für das ACC-SG relevanten Abstandswerte werden gesendet
0x1: 4K ext. range, 10 Signalwege verfügbar ('4m')
0x2: 4K norm. range, 10 Signalwege verfügbar ('2m')
0x3: 6K ext. range, 16 Signalwege verfügbar ('4m')";
CM_ SG_ 896 US_Sende_Modus_hinten "US=Ultraschall
US_Sende_Modus_hinten:
0x0: keine für das ACC-SG relevanten Abstandswerte werden gesendet
0x1....0x4: frei
0x5: 2-K. ext. range (PLA), 2 Signalwege verfügbar ('4m')
0x6: Modeumschaltung (ext -> norm oder norm -> ext)
0x7: Blindheitspr";

CM_ SG_ 348 ARA_Sensor_02_red_cyclic "Zeigt die reduzierte Zykluszeit der CAN-Botschaft 'ARA_Sensor_02' von 100ms gegenüber 20ms an.";
CM_ SG_ 348 ARA_Sensor_dt_Botschaft "Zeitspanne zwischen dem aktuellen Bild und dem Sendezeitpunkt der Nachricht (Berechnungszeit)";
CM_ SG_ 348 ARA_Sensor_Knickw_Rohwert "Rohwert Anhängerknickwinkel am Kugelkopf";
CM_ SG_ 348 ARA_Sensor_Qualitaet_Grund "Grund für einen schlechten Qualitätswert (ARA_Sensor_Qualitaet_Wert)";
CM_ SG_ 348 ARA_Sensor_Qualitaet_Wert "relatives Qualitätsmaß für Bild- und Wikeldetektion
0 - unbrauchbar
1 - optimal ";
CM_ SG_ 348 ARA_Sensor_Status "Status des ARA-Sensors";
CM_ SG_ 348 ARA_Sensor_Zeitstempel_BV "Zeitstempel des von der BV verarbeiteten Bildes";

CM_ SG_ 1365 AV_Charisma_FahrPr "Istwert der Kennlinie (siehe Systemlastenheft MQB FPA)";
CM_ SG_ 1365 AV_Charisma_Status "Charisma Systemstatus des Charisma-Teilnehmers";
CM_ SG_ 1365 AV_HEK_Status_aktiv "Status der Funktion Hinderniserkennung durch Areaview";
CM_ SG_ 1365 AV_HEK_Status_Anz_Punkte "Anzahl der Punkte des Polygons in den folgenden Botschaften AV_HEK_02";
CM_ SG_ 1365 AV_HEK_Status_Kamera_H "Status der Heckkamera";
CM_ SG_ 1365 AV_HEK_Status_Kamera_L "Status der Spiegelkamera links";
CM_ SG_ 1365 AV_HEK_Status_Kamera_R "Status der Spiegelkamera rechts";
CM_ SG_ 1365 AV_HEK_Status_Kamera_V "Status der Frontkamera";
CM_ SG_ 1365 AV_HEK_Status_Zaehler "Zykluszähler der Botschaft AV_HEK_01";
CM_ SG_ 1365 AV_Umfeldbeleuchtung_Anf "Anforderung für die Aktivierung einer Umfeldbeleuchtung zur Unterstützung des Umfeldkamerasystems bei Dunkelheit";

CM_ SG_ 507 AV_HEK_Daten_Block "Blockzähler für Hindernis";
CM_ SG_ 507 AV_HEK_Daten_P1_Nachfolger "0, dann ist Punkt 1 der letzte Punkt des Polygons
1, dann folgt ein weiterer Punkt für das Polygon";
CM_ SG_ 507 AV_HEK_Daten_P1_Trend "Erkannter Bewegungstrend Punkt 1";
CM_ SG_ 507 AV_HEK_Daten_P1_x "X-Koordinate Punkt 1 für das Polygon des erkannten Hindernisses";
CM_ SG_ 507 AV_HEK_Daten_P1_y "Y-Koordinate Punkt 1 für das Polygon des erkannten Hindernisses";
CM_ SG_ 507 AV_HEK_Daten_P2_Nachfolger "0, dann ist Punkt 2 der letzte Punkt des Polygons
1, dann folgt ein weiterer Punkt für das Polygon";
CM_ SG_ 507 AV_HEK_Daten_P2_Trend "Erkannter Bewegungstrend Punkt 2";
CM_ SG_ 507 AV_HEK_Daten_P2_x "X-Koordinate Punkt 2 für das Polygon des erkannten Hindernisses";
CM_ SG_ 507 AV_HEK_Daten_P2_y "Y-Koordinate Punkt 2 für das Polygon des erkannten Hindernisses";
CM_ SG_ 507 AV_HEK_Daten_P3_Nachfolger "0, dann ist Punkt 3 der letzte Punkt des Polygons
1, dann folgt ein weiterer Punkt für das Polygon";
CM_ SG_ 507 AV_HEK_Daten_P3_Trend "Erkannter Bewegungstrend Punkt 3";
CM_ SG_ 507 AV_HEK_Daten_P3_x "X-Koordinate Punkt 3 für das Polygon des erkannten Hindernisses";
CM_ SG_ 507 AV_HEK_Daten_P3_y "Y-Koordinate Punkt 3 für das Polygon des erkannten Hindernisses";
CM_ SG_ 507 AV_HEK_Daten_Zaehler "Zykluszähler der Botschaft AV_HEK_02";

CM_ SG_ 869 BEM_01_Abschaltstufen "Signal inhaltlich identisch mit BEM_02_Abschaltstufen. Namentliche Umbenennung wegen Standard-SW im Gateway-BEM im MLB (Handling gleicher Signalnamen im Source-Code).
Abschaltstufen des Ruhestrommanagements 
(Initialisierungswert aus EEPROM)";
CM_ SG_ 869 BEM_Anf_KL "Es gilt: Signalspec BEM_Anf_KL v1.1
Das BEM fordert über das MSG den Kühlerlüfter-Betrieb an; hierzu wird ein minimaler Leistungswert im MSG appliziert. 
Szenario: bei erkannter abgetrennten Batterie soll durch Ansteuerung des Kühlerlüfters das Energien";
CM_ SG_ 869 BEM_Batt_Ab "Batterieverbindungskontrolle:
0x0: Batterie am Bordnetz
0x1: Batterie ab erkannt";
CM_ SG_ 869 BEM_DFM "Generatorauslastungsgrad, vom Generator über LIN an das Gateway gesandt. Das Motorsteuergerät regelt auf dieses Signal die PTC, das Energiemanagement im BSG/BCM kalkuliert die Bordnetzauslastung";
CM_ SG_ 869 BEM_EMLIN_ungueltig "Energie-Lin - Signale sind ungültig vom Slave Batteriedatenmodul oder Generator
0 = Signale gültig
1 = Signale ungültig";
CM_ SG_ 869 BEM_HYB_DC_uMinLV "Abregelgrenze: minimal erlaubte Bordnetzspannung im Hochsetzbetrieb (Hybrid)";
CM_ SG_ 869 BEM_HYB_DC_uSollLV "Sollwert für die Bordnetzspannung im Tiefsetzbetrieb vom Traktionsnetz ins Bordnetz (Hybrid)";
CM_ SG_ 869 BEM_n_LLA "Es gilt: Signalspec BEM_n_LLA v1.0

Anforderung einer Leerlaufdrehzahlanhebung in drei Stufen. Die Höhe der jeweiligen LL-Drehzahlstufe ist im Motorsteuergerät appliziert.



";
CM_ SG_ 869 BEM_NV_NachladAnf "Bei Energiedefizit auf der Niedervoltseite wird der Lademanager aufgefordert, die Niedervoltseite nachzuladen.";
CM_ SG_ 869 BEM_P_Generator "Es gilt: Signalspec BEM_P_Generator v1.0

Mechanische Generatorleistung dient dem Motorsteuergerät zur Berechnung der Motorlast; Genauigkeit ca. +/- (500W + 20% vom Messwert)";
CM_ SG_ 869 BEM_Segel_Info "0: keine Anforderung 
(Segeln ist ohne Einschänkung erlaubt)
1: Mindestdrehzahl 1 
(Segeln ist mit Einschänkung erlaubt)
2: Mindestdrehzahl 2
(Segeln ist mit Einschänkung erlaubt)
3: Segelveto
(Segeln ist nicht  erlaubt)";
CM_ SG_ 869 BEM_StartStopp_Info "Stopp-Freigabe und Start-Anforderung an den Start-Stopp-Koordinator";
CM_ SG_ 869 BEM_UBDM "Batteriespannung, gemessen vom Batteriedatenmodul";
CM_ SG_ 869 NVEM_FMAus_I_Verbrauch "Predezierter Bordneztstromverbrauch während der Freilauf Motor Aus Phase.";
CM_ SG_ 869 NVEM_FMAus_Info "Freilauf Informationssignal zum Freilaufkoordinator. 
Gilt nur für die Freilauf Phase. Verwendung im MicroHybrid.";
CM_ SG_ 869 NVEM_Freilauf_Info "Freilauf Informationssignal vom NVEM zum Freilaufkoordinator. Das NVEM kann über dieses Signal den Freilauf freigeben, verhindern bzw. explizit anfordern.";
CM_ SG_ 869 NVEM_Ladefreigabe "Freigabeemfehlung zur Ladung des FMA-Zusatzspeichers";
CM_ SG_ 869 NVEM_PTC_Sollstufe "Vorgabe des BEM an das BCM zur Aktivierung der geforderten PTC - Stufe.
Das MSG kopiert dies auf das Signal MO_PTC_Status";

CM_ SG_ 870 Blinken_li_Fzg_Takt "Fzg-Takt Blinker links

";
CM_ SG_ 870 Blinken_li_Kombi_Takt "Kombi-Takt Blinker links

";
CM_ SG_ 870 Blinken_re_Fzg_Takt "Fzg-Takt Blinker rechts

";
CM_ SG_ 870 Blinken_re_Kombi_Takt "Kombi-Takt Blinker rechts

";
CM_ SG_ 870 BM_Autobahn "Status Autobahnblinken
";
CM_ SG_ 870 BM_Crash "Status Crashblinken
";
CM_ SG_ 870 BM_DWA_Alarm "Status DWA-Alarmblinken
";
CM_ SG_ 870 BM_DWA_ein "Status Quittierungsblinken DWA";
CM_ SG_ 870 BM_GDO "Blinken bei UGDO anlernen

";
CM_ SG_ 870 BM_HD_Oeffnung_angelernt "Das HDSG fordert über das CAN Signal HDSG_01.HD_Rueckmeld_prog eine Blinkerquittierung beim BCM2 an.
Wenn die Geschwindigkeit kleiner einer vorgegebenen Schwelle (default 2km/h) ist wird das Signal BM_HD_Öffnung_angelernt versendet und die Blinkerquittie";
CM_ SG_ 870 BM_links "Richtungsblinken links

";
CM_ SG_ 870 BM_NBA_n_codiert_n_aktiv "Notbremsanzeige nicht codiert/nicht aktiv (Fehler)";
CM_ SG_ 870 BM_NBA_Status "Notbremsanzeige Status nicht aktiv / BRL Dunkelphase / BRL Hellphase";
CM_ SG_ 870 BM_Not_Bremsung "Notbremsblinken

";
CM_ SG_ 870 BM_Panik "Panikblinken
";
CM_ SG_ 870 BM_PiloPa "Quittierungsblinken bei pilotierten Parkvorgängen";
CM_ SG_ 870 BM_Recas "Blinkermodus RECAS  (RearEndCollisionAlertSignal)";
CM_ SG_ 870 BM_rechts "Richtungsblinken rechts

";
CM_ SG_ 870 BM_Rollenmodus_Blinken "Das Signal wird statisch gesetzt, wenn die Blinkerart Rollenmodus_Blinken aktiv ist.";
CM_ SG_ 870 BM_Taxi_Notalarm "Blinken bei Taxi-Not-Alarm

";
CM_ SG_ 870 BM_Telematik "Telematikblinken
";
CM_ SG_ 870 BM_Telematik_Abbruchgrund "Gibt bei erwaretem aber ausbleibendem Flankenanstieg der BM_Telematik an wieso die Ausführung verhindert wurde. Bei Flankenabfall der BM_Telematik wird angegeben wieso die Ausführung beendet wurde.

Bei nicht bereitem Sender soll 'init' gesendet werden,";
CM_ SG_ 870 BM_Warnblinken "Warnblinken

";
CM_ SG_ 870 BM_WBT_Beleuchtung "Aktivierung Warnblinktasterfunktionsbeleuchtung
Warnblinktasterfunktionsbeleuchtung soll aktiviert werden (statisch auf 1)";
CM_ SG_ 870 BM_Wischblinken "Blinkermodus Wisch_Blinken";
CM_ SG_ 870 BM_ZV_auf "Blinken bei ZV auf

";
CM_ SG_ 870 BM_ZV_zu "Blinken bei ZV zu

";

CM_ SG_ 901 CHA_Fahrer_Umschaltung "Die manuelle Umschaltung durch den Fahrer soll signalisiert werden, um zu automatischen Umschaltungen (z.B. Retries) differenzieren zu können.";
CM_ SG_ 901 CHA_Fahrer_Umschaltung_BMA "Die manuelle Umschaltung der Betriebsmodusauswahl durch den Fahrer soll signalisiert werden, um zu automatischen Umschaltungen (z.B. Retries) differenzieren zu können.";
CM_ SG_ 901 CHA_Ziel_FahrPr_ACC "MQB
Anforderung Ziel-Fahrprogramm ACC";
CM_ SG_ 901 CHA_Ziel_FahrPr_AFS "Anforderung Ziel-Fahrprogramm AFS";
CM_ SG_ 901 CHA_Ziel_FahrPr_AGA "Anforderung Ziel-Fahrprogramm AGA/SAK2 (Aussensound)";
CM_ SG_ 901 CHA_Ziel_FahrPr_ALR "Anforderung Ziel-Fahrprogramm Allrad";
CM_ SG_ 901 CHA_Ziel_FahrPr_DR "Anforderung Ziel-Fahrprogramm Dämpfer";
CM_ SG_ 901 CHA_Ziel_FahrPr_EPS "Anforderung Ziel-Fahrprogramm Elektrische Lenkhilfe";
CM_ SG_ 901 CHA_Ziel_FahrPr_ESP "Anforderung Ziel-Fahrprogramm ESP";
CM_ SG_ 901 CHA_Ziel_FahrPr_Freilauf "Anforderung Ziel-Fahrprogramm Funktion Freilauf";
CM_ SG_ 901 CHA_Ziel_FahrPr_GE "Anforderung Ziel-Fahrprogramm Getriebe";
CM_ SG_ 901 CHA_Ziel_FahrPr_MO "Anforderung Ziel-Fahrprogramm Motor";
CM_ SG_ 901 CHA_Ziel_FahrPr_MO_BZS "Anforderung Zielfahrprogramm Motor-Betriebszusände";
CM_ SG_ 901 CHA_Ziel_FahrPr_MO_StSt "Anforderung Ziel-Fahrprogramm Funktion Motor Start-Stopp";
CM_ SG_ 901 CHA_Ziel_FahrPr_RGS "Anforderung Ziel-Fahrprogramm Funktion Reversibler Gurtstraffer";
CM_ SG_ 901 CHA_Ziel_FahrPr_SAK "Anforderung Ziel-Fahrprogramm Soundaktuator";
CM_ SG_ 901 CHA_Ziel_FahrPr_VAQ "Anforderung Ziel-Fahrprogramm VAQ";

CM_ SG_ 1000 CHA_Current_Mode "Aktuell eingestelltes Charisma Fahrprogramm";
CM_ SG_ 1000 CHA_Fahrer_Umschaltung "Die manuelle Umschaltung durch den Fahrer soll signalisiert werden, um zu automatischen Umschaltungen (z.B. Retries) differenzieren zu können.";
CM_ SG_ 1000 CHA_Ziel_FahrPr_AEB "Anforderung Ziel-Fahrprogramm AEB (Autonomous Emergency Braking)";
CM_ SG_ 1000 CHA_Ziel_FahrPr_AFR "Anforderung Ziel-Fahrprogramm Aktive Fahrwerk Regelung (eAWS und eABC)";
CM_ SG_ 1000 CHA_Ziel_FahrPr_AV "Anforderung Ziel-Fahrprogramm AreaView2";
CM_ SG_ 1000 CHA_Ziel_FahrPr_EAR "Anforderung Zielfahrprogramm EAR (EFP Allrad Regelsysteme)";
CM_ SG_ 1000 CHA_Ziel_FahrPr_EBKV "Signal zur Ansteuerung des EBKV durch den Charisma-Koordinator";
CM_ SG_ 1000 CHA_Ziel_FahrPr_FCWO "Anforderung Ziel-Fahrprogramm FCWO (Objektwarnung)";
CM_ SG_ 1000 CHA_Ziel_FahrPr_FCWP "Anforderung Ziel-Fahrprogramm FCWP (Personenwarnung)";
CM_ SG_ 1000 CHA_Ziel_FahrPr_HAL "Anforderung Zielfahrprogramm Hinterachslenkung (HAL)";
CM_ SG_ 1000 CHA_Ziel_FahrPr_HDC "Anforderung Ziel-Fahrprogramm Hill Descent Control";
CM_ SG_ 1000 CHA_Ziel_FahrPr_IL "Anforderung Ziel-Fahrprogramm Integrallenkung";
CM_ SG_ 1000 CHA_Ziel_FahrPr_MXB "Anforderung Ziel-Fahrprogramm MXB";
CM_ SG_ 1000 CHA_Ziel_FahrPr_NR "Anforderung Ziel-Fahrprogramm Niveaureglierung";
CM_ SG_ 1000 CHA_Ziel_FahrPr_QS "Anforderung Ziel-Fahrprogramm geregelte Hinterachsquersperre";
CM_ SG_ 1000 CHA_Ziel_FahrPr_SCU "Anforderung Ziel-Fahrprogramm SCU";

CM_ SG_ 1022 CHA_Current_Mode_BMA "Aktuell eingestellter Charisma Betriebsmodus";
CM_ SG_ 1022 CHA_Fahrer_Umschaltung "Die manuelle Umschaltung durch den Fahrer soll signalisiert werden, um zu automatischen Umschaltungen (z.B. Retries) differenzieren zu können.";
CM_ SG_ 1022 CHA_Fahrer_Umschaltung_BMA "Die manuelle Umschaltung der Betriebsmodusauswahl durch den Fahrer soll signalisiert werden, um zu automatischen Umschaltungen (z.B. Retries) differenzieren zu können.";
CM_ SG_ 1022 CHA_Ziel_FahrPr_AGK "Signal zur Ansteuerung des Teilnehmers Abgasklappen durch den Charisma-Koordinator über das Motor-SG";
CM_ SG_ 1022 CHA_Ziel_FahrPr_BMS "Anforderung Ziel-Fahrprogramm BMS (nähere Spezifikation siehe Charisma-LH PAG)";
CM_ SG_ 1022 CHA_Ziel_FahrPr_EDS "Anforderung Ziel-Fahrprogramm Elektronische Differentialsperre";
CM_ SG_ 1022 CHA_Ziel_FahrPr_HHC "Anforderung Ziel-Fahrprogramm Hill Hold Control";
CM_ SG_ 1022 CHA_Ziel_FahrPr_MO_Freilauf "Anforderung Ziel-Fahrprogramm Funktion Freilauf Motor aus";
CM_ SG_ 1022 CHA_Ziel_FahrPr_PACC "Anforderung Ziel-Fahrprogramm InnoDrive (PACCh)";
CM_ SG_ 1022 CHA_Ziel_FahrPr_PDC "Signal zur Ansteuerung des PDC/PLA durch den Charisma-Koordinator";

CM_ SG_ 918 Daempfer_01_CRC "Für MLB:
'Berechnung siehe Lastenheft 'Kommunikationsabsicherung für FlexRay und CAN''

Ab MQB und MLBevo:
'Berechnung siehe Lastenheft 'End-to-End Kommunikationsabsicherung''

Endwerte siehe Begleitdokument 'S-PDU Kennungsfolgen'";
CM_ SG_ 918 DR_Charisma_FahrPr "MLBevo: Aktuelles Fahrprogramm des Charisma-Teilnehmers (siehe Systemlastenheft Drive Select)
MQB: Istwert der Kennlinie (siehe Systemlastenheft MQB FPA)";
CM_ SG_ 918 DR_Charisma_Status "Charisma Systemstatus des Charisma-Teilnehmers

Wert 0x3 ist nur für Fahrzeuge ab MQB relevant";
CM_ SG_ 918 DR_Daempferreg_Texte "Die Textbits werden verwendet, um im Kombi Texte oder Bilder für die Dämpferregelung darzustellen

0x4 - 0xE tbd.

";
CM_ SG_ 918 DR_DynAGL_Anf_Entkopplung "Nur PO44x
Dynamische Aggregatelagerung
Anforderung zusätzliche Entkopplung für Getriebelager";
CM_ SG_ 918 DR_DynAGL_Anf_im_Leerlauf "Nur PO44x
Anforderung zusätzliche Entkopplung des Motorlagers im Leerlauf";
CM_ SG_ 918 DR_DynAGL_Warnlampe "Warnlampe für dynamische Aggregate-Lagerung
Darf im VW526 und PAG E2 nicht verwendet werden";
CM_ SG_ 918 DR_Fahrzeugart "Für automatische Fahrzeugerkennung zur Absicherung der Einschränkungen

Wird im D4 nicht bedient
Darf im VW526 nicht verwendet werden";
CM_ SG_ 918 DR_Gelbe_Warnlampe "Bit wird gesetzt, wenn während des Betriebes ein Fehler erkannt wird.";
CM_ SG_ 918 DR_Rote_Warnlampe "Bit wird gesetzt, wenn während des Betriebes ein schwerwiegender Fehler erkannt wird.
Darf im VW526 nicht verwendet werden";
CM_ SG_ 918 DR_Systemstatus "Bei Statusänderung wird der Soll-Zustand ausgegeben. Der Status beschreibt einen Parametersatz: Temporäre Änderung der Dämpfereinstellungen werden hier nicht abgebildet. 
";
CM_ SG_ 918 DR_Taster "Ausgabe der Position des Tasters der Dämpferregelung";
CM_ SG_ 918 LF_Texte "Signal zur Ansteuerung von Fahrerhinweisen im Kombi";
CM_ SG_ 918 LF_Warnung_Prio1 "Signal zur Ansteuerung von Prio1-Warnungen im Kombi";
CM_ SG_ 918 LF_Warnung_Prio2 "Signal zur Ansteuerung von Prio2-Warnungen im Kombi";
CM_ SG_ 918 NI_Status "Status des Niveau Systems LB83x";
CM_ SG_ 918 NR_Niveaufunktion_aktiv "AU57x:
Signal meldet DriveSelect, wann die lift-Funktion aktiv ist damit das Fahrprogramm auf allroad gewechselt werden kann.

MLBevo:
Das Signal wird benötigt um eine gezielte Sonderreaktion bei Verlassen des Liftmodus einzuleiten.";

BA_DEF_  "DBName" STRING;
BA_DEF_  "GenNWMApBusSleep" STRING;
BA_DEF_  "GenNWMApCanNormal" STRING;
BA_DEF_  "GenNWMApCanOff" STRING;
BA_DEF_  "GenNWMApCanOn" STRING;
BA_DEF_  "GenNWMApCanSleep" STRING;
BA_DEF_  "GenNWMApCanWakeUp" STRING;
BA_DEF_  "GenNWMGotoMode_Awake" STRING;
BA_DEF_  "GenNWMGotoMode_BusSleep" STRING;
BA_DEF_  "GenNWMSleepTime" INT 0 1000000;
BA_DEF_  "GenNWMTalkNM" STRING;
BA_DEF_  "Manufacturer" STRING;
BA_DEF_  "NmhBaseAddress" HEX 0 536870911;
BA_DEF_  "NmhMessageCount" INT 0 256;
BA_DEF_  "NmType" STRING;
BA_DEF_  "VAGTP20_SetupMessageCount" INT 0 255;
BA_DEF_  "VAGTP20_SetupStartAddress" HEX 0 2047;
BA_DEF_  "VersionDay" INT 1 31;
BA_DEF_  "VersionMonth" INT 1 12;
BA_DEF_  "VersionWeek" INT 1 52;
BA_DEF_  "VersionYear" INT 0 99;
BA_DEF_  "VersionNumber" INT 0 65535;
BA_DEF_  "Baudrate" INT 0 1000000;
BA_DEF_  "SamplePointMin" INT 1 100;
BA_DEF_  "SamplePointMax" INT 1 100;
BA_DEF_  "SyncJumpWidthMin" INT 1 4;
BA_DEF_  "SyncJumpWidthMax" INT 1 4;
BA_DEF_  "NmhTimeoutTimer" INT 0 65535;
BA_DEF_  "NmhWaitBusSleepTimer" INT 0 65535;
BA_DEF_  "NmhPrepareBusSleepTimer" INT 0 65535;
BA_DEF_  "NmhLongTimer" INT 0 65535;
BA_DEF_  "NmhNStart" INT 0 255;
BA_DEF_ BU_  "GenNodAutoGenDsp" ENUM "No", "Yes";
BA_DEF_ BU_  "GenNodAutoGenSnd" ENUM "No", "Yes";
BA_DEF_ BU_  "GenNodSleepTime" INT 0 1000000;
BA_DEF_ BU_  "ILUsed" ENUM "No", "Yes";
BA_DEF_ BU_  "ECUVariantDefault" ENUM "No", "Yes";
BA_DEF_ BU_  "ECUVariantGroup" STRING;
BA_DEF_ BU_  "NodeLayerModules" STRING;
BA_DEF_ BU_  "NmhNode" ENUM "No", "Yes";
BA_DEF_ BU_  "NmNode" ENUM "No", "Yes";
BA_DEF_REL_ BU_SG_REL_  "GenSigTimeoutTime" INT 0 65535;
BA_DEF_ BO_  "DiagRequest" ENUM "No", "Yes";
BA_DEF_ BO_  "DiagResponse" ENUM "No", "Yes";
BA_DEF_ BO_  "DiagState" ENUM "No", "Yes";
BA_DEF_ BO_  "GenMsgChkConstant" HEX 0 4095;
BA_DEF_ BO_  "GenMsgCycleTime" INT 0 65535;
BA_DEF_ BO_  "GenMsgCycleTimeFast" INT 0 65535;
BA_DEF_ BO_  "GenMsgDelayTime" INT 0 100000;
BA_DEF_ BO_  "GenMsgILSupport" ENUM "No", "Yes";
BA_DEF_ BO_  "GenMsgNrOfRepetition" INT 0 100;
BA_DEF_ BO_  "GenMsgPDUConstants" STRING;
BA_DEF_ BO_  "GenMsgSendType" ENUM "Cyclic", "not_used", "not_used", "not_used", "not_used", "not_used", "not_used", "IfActive", "NoMsgSendType";
BA_DEF_ BO_  "GenMsgStartDelayTime" INT 0 100000;
BA_DEF_ BO_  "NmMessage" ENUM "No", "Yes";
BA_DEF_ BO_  "NmhMessage" ENUM "No", "Yes";
BA_DEF_ BO_  "MsgType" ENUM "Application", "NM ", "NMH", "TP2.0", "ISO-TP ", "BAP", "EID", "KS";
BA_DEF_ BO_  "VAGTP20_API" HEX 0 255;
BA_DEF_ BO_  "VAGTP20_DynConnection" ENUM "No", "Yes";
BA_DEF_ BO_  "VAGTP20_DynSetup" ENUM "No", "Yes";
BA_DEF_ BO_  "VAGTP20_StatConnection" ENUM "No", "Yes";
BA_DEF_ SG_  "GenSigActiveRepetitions" INT -2147483648 2147483647;
BA_DEF_ SG_  "GenSigInactiveValue" INT -2147483648 2147483647;
BA_DEF_ SG_  "GenSigSendType" ENUM "Cyclic", "OnWrite", "OnWriteWithRepetition", "OnChange", "OnChangeWithRepetition", "IfActive", "IfActiveWithRepetition", "NoSigSendType", "OnChangeAndIfActive", "OnChangeAndIfActiveWithRepetition";
BA_DEF_ SG_  "GenSigStartValue" INT -2147483648 2147483647;
BA_DEF_ SG_  "NWM-WakeupAllowed" ENUM "No", "Yes";
BA_DEF_ SG_  "GenSigFuncType" ENUM "NoFunction", "MsgCounter", "CRC-8", "XOR", "XOR-2", "DatedBit", "SW-Kl15", "CHK", "Constant", "Protocol", "CRC-8-SAE_J1850";
BA_DEF_ SG_  "GenSigSwitchedByIgnition" ENUM "No", "Yes";
BA_DEF_ SG_  "Fehlerwert" HEX 0 2147483647;
BA_DEF_ SG_  "GenSigMissingSourceValue" HEX 0 2147483647;
BA_DEF_DEF_  "DBName" "";
BA_DEF_DEF_  "GenNWMApBusSleep" "";
BA_DEF_DEF_  "GenNWMApCanNormal" "";
BA_DEF_DEF_  "GenNWMApCanOff" "";
BA_DEF_DEF_  "GenNWMApCanOn" "";
BA_DEF_DEF_  "GenNWMApCanSleep" "";
BA_DEF_DEF_  "GenNWMApCanWakeUp" "";
BA_DEF_DEF_  "GenNWMGotoMode_Awake" "";
BA_DEF_DEF_  "GenNWMGotoMode_BusSleep" "";
BA_DEF_DEF_  "GenNWMSleepTime" 0;
BA_DEF_DEF_  "GenNWMTalkNM" "";
BA_DEF_DEF_  "Manufacturer" "";
BA_DEF_DEF_  "NmhBaseAddress" 0;
BA_DEF_DEF_  "NmhMessageCount" 1;
BA_DEF_DEF_  "NmType" "None";
BA_DEF_DEF_  "VAGTP20_SetupMessageCount" 0;
BA_DEF_DEF_  "VAGTP20_SetupStartAddress" 0;
BA_DEF_DEF_  "VersionDay" 16;
BA_DEF_DEF_  "VersionMonth" 6;
BA_DEF_DEF_  "VersionWeek" 25;
BA_DEF_DEF_  "VersionYear" 15;
BA_DEF_DEF_  "VersionNumber" 0;
BA_DEF_DEF_  "Baudrate" 0;
BA_DEF_DEF_  "SamplePointMin" 1;
BA_DEF_DEF_  "SamplePointMax" 1;
BA_DEF_DEF_  "SyncJumpWidthMin" 1;
BA_DEF_DEF_  "SyncJumpWidthMax" 1;
BA_DEF_DEF_  "NmhTimeoutTimer" 0;
BA_DEF_DEF_  "NmhWaitBusSleepTimer" 0;
BA_DEF_DEF_  "NmhPrepareBusSleepTimer" 0;
BA_DEF_DEF_  "NmhLongTimer" 0;
BA_DEF_DEF_  "NmhNStart" 0;
BA_DEF_DEF_  "GenNodAutoGenDsp" "Yes";
BA_DEF_DEF_  "GenNodAutoGenSnd" "Yes";
BA_DEF_DEF_  "GenNodSleepTime" 0;
BA_DEF_DEF_  "ILUsed" "Yes";
BA_DEF_DEF_  "ECUVariantDefault" "Yes";
BA_DEF_DEF_  "ECUVariantGroup" "";
BA_DEF_DEF_  "NodeLayerModules" "";
BA_DEF_DEF_  "NmhNode" "Yes";
BA_DEF_DEF_  "NmNode" "No";
BA_DEF_DEF_REL_  "GenSigTimeoutTime" 0;
BA_DEF_DEF_  "DiagRequest" "No";
BA_DEF_DEF_  "DiagResponse" "No";
BA_DEF_DEF_  "DiagState" "No";
BA_DEF_DEF_  "GenMsgChkConstant" 0;
BA_DEF_DEF_  "GenMsgCycleTime" 0;
BA_DEF_DEF_  "GenMsgCycleTimeFast" 0;
BA_DEF_DEF_  "GenMsgDelayTime" 0;
BA_DEF_DEF_  "GenMsgILSupport" "No";
BA_DEF_DEF_  "GenMsgNrOfRepetition" 0;
BA_DEF_DEF_  "GenMsgPDUConstants" "";
BA_DEF_DEF_  "GenMsgSendType" "NoMsgSendType";
BA_DEF_DEF_  "GenMsgStartDelayTime" 0;
BA_DEF_DEF_  "NmMessage" "No";
BA_DEF_DEF_  "NmhMessage" "No";
BA_DEF_DEF_  "MsgType" "Application";
BA_DEF_DEF_  "VAGTP20_API" 0;
BA_DEF_DEF_  "VAGTP20_DynConnection" "No";
BA_DEF_DEF_  "VAGTP20_DynSetup" "No";
BA_DEF_DEF_  "VAGTP20_StatConnection" "No";
BA_DEF_DEF_  "GenSigActiveRepetitions" 0;
BA_DEF_DEF_  "GenSigInactiveValue" 0;
BA_DEF_DEF_  "GenSigSendType" "NoSigSendType";
BA_DEF_DEF_  "GenSigStartValue" 0;
BA_DEF_DEF_  "NWM-WakeupAllowed" "No";
BA_DEF_DEF_  "GenSigFuncType" "NoFunction";
BA_DEF_DEF_  "GenSigSwitchedByIgnition" "Yes";
BA_DEF_DEF_  "Fehlerwert" 0;
BA_DEF_DEF_  "GenSigMissingSourceValue" 0;
BA_  "DBName" "MQB_FCAN";
BA_  "GenNWMApBusSleep" "NMIndNetSDN()";
BA_  "GenNWMApCanNormal" "apCanNormal()";
BA_  "GenNWMApCanOff" "NMIndnetOff()";
BA_  "GenNWMApCanOn" "NMIndnetOn()";
BA_  "GenNWMApCanSleep" "apCanSleep()";
BA_  "GenNWMApCanWakeUp" "apCanWakeUp()";
BA_  "GenNWMGotoMode_Awake" "Nmh_ReqNetOn()";
BA_  "GenNWMGotoMode_BusSleep" "Nmh_ReqNetOff()";
BA_  "GenNWMSleepTime" 4000;
BA_  "GenNWMTalkNM" "Nmh_ReqNetOn()";
BA_  "Manufacturer" "VAG";
BA_  "NmhBaseAddress" 452984832;
BA_  "NmhMessageCount" 256;
BA_  "NmType" "NM-High";
BA_  "VAGTP20_SetupMessageCount" 128;
BA_  "VAGTP20_SetupStartAddress" 512;
BA_  "VersionNumber" 15;
BA_  "Baudrate" 500000;
BA_  "SamplePointMin" 80;
BA_  "SamplePointMax" 84;
BA_  "SyncJumpWidthMin" 2;
BA_  "SyncJumpWidthMax" 4;
BA_  "NmhTimeoutTimer" 1000;
BA_  "NmhWaitBusSleepTimer" 750;
BA_  "NmhPrepareBusSleepTimer" 500;
BA_  "NmhLongTimer" 200;
BA_  "NmhNStart" 20;
BA_ "GenNodSleepTime" BU_ Allrad_Haldex 4000;
BA_ "ECUVariantGroup" BU_ Allrad_Haldex "Allrad";
BA_ "NmhNode" BU_ Allrad_Haldex 0;
BA_ "GenNodSleepTime" BU_ AreaView_MQB 4000;
BA_ "ECUVariantGroup" BU_ AreaView_MQB "Rearview";
BA_ "NodeLayerModules" BU_ AreaView_MQB "NMHigh.DLL";
BA_ "GenNodSleepTime" BU_ BAP_Tester 4000;
BA_ "ECUVariantGroup" BU_ BAP_Tester "BAP";
BA_ "NmhNode" BU_ BAP_Tester 0;
BA_ "GenNodSleepTime" BU_ Bremse_ABS_MK100 4000;
BA_ "ECUVariantDefault" BU_ Bremse_ABS_MK100 0;
BA_ "ECUVariantGroup" BU_ Bremse_ABS_MK100 "Bremse";
BA_ "NodeLayerModules" BU_ Bremse_ABS_MK100 "NMHigh.DLL";
BA_ "GenNodSleepTime" BU_ Bremse_ESP_EPB_EBC460Vi 4000;
BA_ "ECUVariantDefault" BU_ Bremse_ESP_EPB_EBC460Vi 0;
BA_ "ECUVariantGroup" BU_ Bremse_ESP_EPB_EBC460Vi "Bremse";
BA_ "NodeLayerModules" BU_ Bremse_ESP_EPB_EBC460Vi "NMHigh.DLL";
BA_ "GenNodSleepTime" BU_ Bremse_ESP_EPB_MK100 4000;
BA_ "ECUVariantGroup" BU_ Bremse_ESP_EPB_MK100 "Bremse";
BA_ "NodeLayerModules" BU_ Bremse_ESP_EPB_MK100 "NMHigh.DLL";
BA_ "GenNodSleepTime" BU_ Bremse_ESP_MK100 4000;
BA_ "ECUVariantDefault" BU_ Bremse_ESP_MK100 0;
BA_ "ECUVariantGroup" BU_ Bremse_ESP_MK100 "Bremse";
BA_ "NodeLayerModules" BU_ Bremse_ESP_MK100 "NMHigh.DLL";
BA_ "GenNodSleepTime" BU_ Daempfer 4000;
BA_ "ECUVariantGroup" BU_ Daempfer "Daempfer";
BA_ "NmhNode" BU_ Daempfer 0;
BA_ "GenNodSleepTime" BU_ Gateway_MQB 4000;
BA_ "ECUVariantGroup" BU_ Gateway_MQB "Gateway";
BA_ "NodeLayerModules" BU_ Gateway_MQB "NMHigh.DLL";
BA_ "GenNodSleepTime" BU_ Lenkhilfe_EPS 4000;
BA_ "ECUVariantGroup" BU_ Lenkhilfe_EPS "Lenkhilfe";
BA_ "NodeLayerModules" BU_ Lenkhilfe_EPS "NMHigh.DLL";
BA_ "GenNodSleepTime" BU_ PDC 4000;
BA_ "ECUVariantGroup" BU_ PDC "PDCPLA";
BA_ "NmhNode" BU_ PDC 0;
BA_ "GenNodSleepTime" BU_ PDC_PLA 4000;
BA_ "ECUVariantGroup" BU_ PDC_PLA "PDCPLA";
BA_ "NmhNode" BU_ PDC_PLA 0;
BA_ "GenMsgCycleTime" BO_ 302 20;
BA_ "GenMsgILSupport" BO_ 302 1;
BA_ "GenMsgPDUConstants" BO_ 302 "0xf8,0xe5,0x97,0xc9,0xd6,0x07,0x47,0x21,0x66,0xdd,0xcf,0x6f,0xa1,0x94,0x74,0x63";
BA_ "GenMsgSendType" BO_ 302 0;
BA_ "GenMsgChkConstant" BO_ 279 22;
BA_ "GenMsgCycleTime" BO_ 279 20;
BA_ "GenMsgILSupport" BO_ 279 1;
BA_ "GenMsgPDUConstants" BO_ 279 "0x16,0x16,0x16,0x16,0x16,0x16,0x16,0x16,0x16,0x16,0x16,0x16,0x16,0x16,0x16,0x16";
BA_ "GenMsgSendType" BO_ 279 0;
BA_ "GenMsgChkConstant" BO_ 64 64;
BA_ "GenMsgCycleTime" BO_ 64 50;
BA_ "GenMsgCycleTimeFast" BO_ 64 10;
BA_ "GenMsgDelayTime" BO_ 64 10;
BA_ "GenMsgILSupport" BO_ 64 1;
BA_ "GenMsgNrOfRepetition" BO_ 64 5;
BA_ "GenMsgPDUConstants" BO_ 64 "0x40,0x40,0x40,0x40,0x40,0x40,0x40,0x40,0x40,0x40,0x40,0x40,0x40,0x40,0x40,0x40";
BA_ "GenMsgSendType" BO_ 64 0;
BA_ "GenMsgChkConstant" BO_ 1312 68;
BA_ "GenMsgCycleTime" BO_ 1312 200;
BA_ "GenMsgDelayTime" BO_ 1312 20;
BA_ "GenMsgILSupport" BO_ 1312 1;
BA_ "GenMsgPDUConstants" BO_ 1312 "0x44,0x44,0x44,0x44,0x44,0x44,0x44,0x44,0x44,0x44,0x44,0x44,0x44,0x44,0x44,0x44";
BA_ "GenMsgSendType" BO_ 1312 0;
BA_ "GenMsgCycleTime" BO_ 65 1000;
BA_ "GenMsgCycleTimeFast" BO_ 65 10;
BA_ "GenMsgDelayTime" BO_ 65 10;
BA_ "GenMsgILSupport" BO_ 65 1;
BA_ "GenMsgNrOfRepetition" BO_ 65 5;
BA_ "GenMsgPDUConstants" BO_ 65 "0x93,0xb0,0x9d,0xf1,0x09,0xe8,0x88,0x5e,0x36,0xfa,0xa8,0xa1,0x67,0x84,0xca,0x4f";
BA_ "GenMsgSendType" BO_ 65 0;
BA_ "GenMsgCycleTime" BO_ 280 100;
BA_ "GenMsgCycleTimeFast" BO_ 280 10;
BA_ "GenMsgDelayTime" BO_ 280 10;
BA_ "GenMsgILSupport" BO_ 280 1;
BA_ "GenMsgNrOfRepetition" BO_ 280 5;
BA_ "GenMsgSendType" BO_ 280 0;
BA_ "GenMsgCycleTime" BO_ 897 80;
BA_ "GenMsgILSupport" BO_ 897 1;
BA_ "GenMsgSendType" BO_ 897 0;
BA_ "GenMsgCycleTime" BO_ 898 80;
BA_ "GenMsgILSupport" BO_ 898 1;
BA_ "GenMsgSendType" BO_ 898 0;
BA_ "GenMsgCycleTime" BO_ 927 80;
BA_ "GenMsgILSupport" BO_ 927 1;
BA_ "GenMsgSendType" BO_ 927 0;
BA_ "GenMsgChkConstant" BO_ 896 19;
BA_ "GenMsgCycleTime" BO_ 896 80;
BA_ "GenMsgCycleTimeFast" BO_ 896 20;
BA_ "GenMsgILSupport" BO_ 896 1;
BA_ "GenMsgPDUConstants" BO_ 896 "0x13,0x13,0x13,0x13,0x13,0x13,0x13,0x13,0x13,0x13,0x13,0x13,0x13,0x13,0x13,0x13";
BA_ "GenMsgSendType" BO_ 896 0;
BA_ "GenMsgCycleTime" BO_ 348 100;
BA_ "GenMsgCycleTimeFast" BO_ 348 20;
BA_ "GenMsgILSupport" BO_ 348 1;
BA_ "GenMsgNrOfRepetition" BO_ 348 5;
BA_ "GenMsgSendType" BO_ 348 0;
BA_ "GenMsgCycleTime" BO_ 1365 1000;
BA_ "GenMsgCycleTimeFast" BO_ 1365 60;
BA_ "GenMsgDelayTime" BO_ 1365 60;
BA_ "GenMsgILSupport" BO_ 1365 1;
BA_ "GenMsgSendType" BO_ 1365 0;
BA_ "GenMsgCycleTimeFast" BO_ 507 10;
BA_ "GenMsgILSupport" BO_ 507 1;
BA_ "GenMsgCycleTimeFast" BO_ 2536711680 80;
BA_ "GenMsgSendType" BO_ 2536711680 7;
BA_ "MsgType" BO_ 2536711680 5;
BA_ "GenMsgCycleTime" BO_ 2536711696 1000;
BA_ "GenMsgCycleTimeFast" BO_ 2536711696 50;
BA_ "GenMsgSendType" BO_ 2536711696 7;
BA_ "MsgType" BO_ 2536711696 5;
BA_ "MsgType" BO_ 2536767264 5;
BA_ "MsgType" BO_ 2536767280 5;
BA_ "GenMsgCycleTimeFast" BO_ 2536704512 80;
BA_ "GenMsgSendType" BO_ 2536704512 7;
BA_ "MsgType" BO_ 2536704512 5;
BA_ "GenMsgCycleTimeFast" BO_ 2536704513 80;
BA_ "GenMsgSendType" BO_ 2536704513 7;
BA_ "MsgType" BO_ 2536704513 5;
BA_ "GenMsgCycleTime" BO_ 2536704528 1000;
BA_ "GenMsgCycleTimeFast" BO_ 2536704528 50;
BA_ "GenMsgSendType" BO_ 2536704528 7;
BA_ "MsgType" BO_ 2536704528 5;
BA_ "GenMsgCycleTime" BO_ 2536704529 1000;
BA_ "GenMsgCycleTimeFast" BO_ 2536704529 50;
BA_ "GenMsgSendType" BO_ 2536704529 7;
BA_ "MsgType" BO_ 2536704529 5;
BA_ "GenMsgCycleTimeFast" BO_ 2536703744 80;
BA_ "GenMsgSendType" BO_ 2536703744 7;
BA_ "MsgType" BO_ 2536703744 5;
BA_ "GenMsgCycleTimeFast" BO_ 2536703745 80;
BA_ "GenMsgSendType" BO_ 2536703745 7;
BA_ "MsgType" BO_ 2536703745 5;
BA_ "GenMsgCycleTime" BO_ 2536703760 1000;
BA_ "GenMsgCycleTimeFast" BO_ 2536703760 50;
BA_ "GenMsgSendType" BO_ 2536703760 7;
BA_ "MsgType" BO_ 2536703760 5;
BA_ "GenMsgCycleTimeFast" BO_ 2536704768 80;
BA_ "GenMsgSendType" BO_ 2536704768 7;
BA_ "MsgType" BO_ 2536704768 5;
BA_ "GenMsgCycleTime" BO_ 2536704784 1000;
BA_ "GenMsgCycleTimeFast" BO_ 2536704784 50;
BA_ "GenMsgSendType" BO_ 2536704784 7;
BA_ "MsgType" BO_ 2536704784 5;
BA_ "GenMsgCycleTime" BO_ 869 50;
BA_ "GenMsgILSupport" BO_ 869 1;
BA_ "GenMsgSendType" BO_ 869 0;
BA_ "GenMsgCycleTime" BO_ 870 1000;
BA_ "GenMsgCycleTimeFast" BO_ 870 50;
BA_ "GenMsgDelayTime" BO_ 870 10;
BA_ "GenMsgILSupport" BO_ 870 1;
BA_ "GenMsgNrOfRepetition" BO_ 870 5;
BA_ "GenMsgSendType" BO_ 870 0;
BA_ "MsgType" BO_ 2281471488 6;
BA_ "MsgType" BO_ 2281471489 6;
BA_ "MsgType" BO_ 2281477632 6;
BA_ "MsgType" BO_ 2281477634 6;
BA_ "MsgType" BO_ 2281477633 6;
BA_ "MsgType" BO_ 2281477635 6;
BA_ "GenMsgCycleTime" BO_ 901 1000;
BA_ "GenMsgDelayTime" BO_ 901 50;
BA_ "GenMsgILSupport" BO_ 901 1;
BA_ "GenMsgSendType" BO_ 901 0;
BA_ "GenMsgCycleTime" BO_ 1000 1000;
BA_ "GenMsgDelayTime" BO_ 1000 50;
BA_ "GenMsgILSupport" BO_ 1000 1;
BA_ "GenMsgSendType" BO_ 1000 0;
BA_ "GenMsgCycleTime" BO_ 1022 1000;
BA_ "GenMsgDelayTime" BO_ 1022 50;
BA_ "GenMsgILSupport" BO_ 1022 1;
BA_ "GenMsgSendType" BO_ 1022 0;
BA_ "GenMsgChkConstant" BO_ 918 149;
BA_ "GenMsgCycleTime" BO_ 918 100;
BA_ "GenMsgILSupport" BO_ 918 1;
BA_ "GenMsgPDUConstants" BO_ 918 "0x95,0x95,0x95,0x95,0x95,0x95,0x95,0x95,0x95,0x95,0x95,0x95,0x95,0x95,0x95,0x95";
BA_ "GenMsgSendType" BO_ 918 0;
BA_ "MsgType" BO_ 2617014784 6;
BA_ "MsgType" BO_ 2617014785 6;
BA_ "MsgType" BO_ 2617014786 6;
BA_ "MsgType" BO_ 2617014787 6;
BA_ "MsgType" BO_ 2617014788 6;
BA_ "MsgType" BO_ 2617014789 6;
BA_ "MsgType" BO_ 2617014790 6;
BA_ "MsgType" BO_ 2617014791 6;
BA_ "MsgType" BO_ 2617199107 6;
BA_ "MsgType" BO_ 2617199108 6;
BA_ "MsgType" BO_ 2617199109 6;
BA_ "MsgType" BO_ 2617199110 6;
BA_ "MsgType" BO_ 2617199111 6;
BA_ "MsgType" BO_ 2617199112 6;
BA_ "MsgType" BO_ 2617199113 6;
BA_ "MsgType" BO_ 2617199114 6;
BA_ "MsgType" BO_ 2617199115 6;
BA_ "MsgType" BO_ 2617199116 6;
BA_ "MsgType" BO_ 2617199117 6;
BA_ "MsgType" BO_ 2617199118 6;
BA_ "MsgType" BO_ 2617199119 6;
BA_ "MsgType" BO_ 2617199120 6;
BA_ "MsgType" BO_ 2617199121 6;
BA_ "MsgType" BO_ 2617199122 6;
BA_ "MsgType" BO_ 2617217541 6;
BA_ "MsgType" BO_ 2617217542 6;
BA_ "MsgType" BO_ 2617217536 6;
BA_ "MsgType" BO_ 2617217537 6;
BA_ "MsgType" BO_ 2617152000 6;
BA_ "MsgType" BO_ 2617152001 6;
BA_ "MsgType" BO_ 2617152002 6;
BA_ "MsgType" BO_ 2617152003 6;
BA_ "MsgType" BO_ 2617152004 6;
BA_ "MsgType" BO_ 2617152005 6;
BA_ "MsgType" BO_ 2617022976 6;
BA_ "MsgType" BO_ 2617022977 6;
BA_ "MsgType" BO_ 2617022978 6;
BA_ "MsgType" BO_ 2617022979 6;
BA_ "MsgType" BO_ 2617022980 6;
BA_ "MsgType" BO_ 2617022981 6;
BA_ "MsgType" BO_ 2617020965 6;
BA_ "MsgType" BO_ 2617020962 6;
BA_ "MsgType" BO_ 2617020963 6;
BA_ "MsgType" BO_ 2617020964 6;
BA_ "MsgType" BO_ 2617020928 6;
BA_ "MsgType" BO_ 2617020929 6;
BA_ "MsgType" BO_ 2617020930 6;
BA_ "MsgType" BO_ 2617020931 6;
BA_ "MsgType" BO_ 2617020932 6;
BA_ "MsgType" BO_ 2617020933 6;
BA_ "GenSigSendType" SG_ 302 ACC_07_BZ 0;
BA_ "GenSigFuncType" SG_ 302 ACC_07_BZ 1;
BA_ "GenSigSendType" SG_ 302 ACC_07_CRC 0;
BA_ "GenSigFuncType" SG_ 302 ACC_07_CRC 2;
BA_ "GenSigSendType" SG_ 302 ACC_Anfahren 0;
BA_ "GenSigSendType" SG_ 302 ACC_Anforderung_HMS 0;
BA_ "GenSigSendType" SG_ 302 ACC_Anhalten 0;
BA_ "GenSigSendType" SG_ 302 ACC_Anhalteweg 0;
BA_ "GenSigStartValue" SG_ 302 ACC_Anhalteweg 2046;
BA_ "Fehlerwert" SG_ 302 ACC_Anhalteweg 2047;
BA_ "GenSigSendType" SG_ 302 ACC_Folgebeschl 0;
BA_ "GenSigStartValue" SG_ 302 ACC_Folgebeschl 254;
BA_ "GenSigSendType" SG_ 302 ACC_Freilauf_Anf 0;
BA_ "GenSigSendType" SG_ 302 ACC_Freilauf_Info 0;
BA_ "GenSigSendType" SG_ 302 ACC_Sollbeschleunigung_02 0;
BA_ "GenSigStartValue" SG_ 302 ACC_Sollbeschleunigung_02 2046;
BA_ "Fehlerwert" SG_ 302 ACC_Sollbeschleunigung_02 2047;
BA_ "GenSigSendType" SG_ 279 ACC_10_BZ 0;
BA_ "GenSigFuncType" SG_ 279 ACC_10_BZ 1;
BA_ "GenSigSendType" SG_ 279 ACC_10_CRC 0;
BA_ "GenSigFuncType" SG_ 279 ACC_10_CRC 2;
BA_ "GenSigSendType" SG_ 279 ANB_CM_Anforderung 0;
BA_ "GenSigSendType" SG_ 279 ANB_CM_Info 0;
BA_ "GenSigSendType" SG_ 279 ANB_Info_Teilbremsung 0;
BA_ "GenSigSendType" SG_ 279 ANB_Notfallblinken 0;
BA_ "GenSigSendType" SG_ 279 ANB_Teilbremsung_Freigabe 0;
BA_ "GenSigSendType" SG_ 279 ANB_Zielbrems_Teilbrems_Verz_Anf 0;
BA_ "GenSigStartValue" SG_ 279 ANB_Zielbrems_Teilbrems_Verz_Anf 834;
BA_ "GenSigSendType" SG_ 279 ANB_Zielbremsung_Freigabe 0;
BA_ "GenSigSendType" SG_ 279 AWV1_Anf_Prefill 0;
BA_ "GenSigSendType" SG_ 279 AWV1_ECD_Anlauf 0;
BA_ "GenSigSendType" SG_ 279 AWV1_HBA_Param 0;
BA_ "GenSigSendType" SG_ 279 AWV2_Freigabe 0;
BA_ "GenSigSendType" SG_ 279 AWV2_Priowarnung 0;
BA_ "GenSigSendType" SG_ 279 AWV2_Ruckprofil 0;
BA_ "GenSigSendType" SG_ 279 AWV_CityANB_Auspraegung 0;
BA_ "GenSigFuncType" SG_ 279 AWV_CityANB_Auspraegung 8;
BA_ "GenSigSendType" SG_ 279 AWV_Halten 0;
BA_ "GenSigSendType" SG_ 279 AWV_Vorstufe 0;
BA_ "GenSigSendType" SG_ 279 PCF_Freigabe 0;
BA_ "GenSigSendType" SG_ 279 PCF_Time_to_collision 0;
BA_ "GenSigStartValue" SG_ 279 PCF_Time_to_collision 255;
BA_ "GenSigSendType" SG_ 64 AB_Anzeige_Fussg 0;
BA_ "GenSigSendType" SG_ 64 AB_Crash_Int 4;
BA_ "GenSigSendType" SG_ 64 AB_Deaktiviert 0;
BA_ "GenSigSendType" SG_ 64 AB_Deaktivierung_HV 4;
BA_ "Fehlerwert" SG_ 64 AB_Deaktivierung_HV 7;
BA_ "GenSigSendType" SG_ 64 AB_Diagnose 0;
BA_ "GenSigSendType" SG_ 64 AB_EDR_Trigger 3;
BA_ "GenSigSendType" SG_ 64 AB_Erh_Auf_VB 0;
BA_ "GenSigSendType" SG_ 64 AB_Front_Crash 4;
BA_ "GenSigSendType" SG_ 64 AB_Gurtwarn_VB 0;
BA_ "GenSigSendType" SG_ 64 AB_Gurtwarn_VF 0;
BA_ "GenSigSendType" SG_ 64 AB_Heck_Crash 4;
BA_ "GenSigSendType" SG_ 64 AB_Lampe 0;
BA_ "GenSigStartValue" SG_ 64 AB_Lampe 1;
BA_ "GenSigSendType" SG_ 64 AB_MKB_Anforderung 4;
BA_ "GenSigSendType" SG_ 64 AB_MKB_gueltig 0;
BA_ "GenSigFuncType" SG_ 64 AB_MKB_gueltig 8;
BA_ "GenSigSendType" SG_ 64 AB_PAO_Leuchte_Anf 0;
BA_ "GenSigStartValue" SG_ 64 AB_PAO_Leuchte_Anf 1;
BA_ "GenSigSendType" SG_ 64 AB_RGS_Anst 3;
BA_ "GenSigStartValue" SG_ 64 AB_RGS_Anst 8;
BA_ "GenSigSendType" SG_ 64 AB_Rollover_Crash 4;
BA_ "GenSigSendType" SG_ 64 AB_SB_Crash 4;
BA_ "GenSigSendType" SG_ 64 AB_SF_Crash 4;
BA_ "GenSigSendType" SG_ 64 AB_Stellgliedtest 0;
BA_ "GenSigSendType" SG_ 64 AB_Systemfehler 0;
BA_ "GenSigSendType" SG_ 64 AB_Texte_AKS 0;
BA_ "GenSigSendType" SG_ 64 AB_VB_deaktiviert 0;
BA_ "GenSigStartValue" SG_ 64 AB_VB_deaktiviert 1;
BA_ "GenSigSendType" SG_ 64 AB_Versorgungsspannung 0;
BA_ "GenSigSendType" SG_ 64 Airbag_01_BZ 0;
BA_ "GenSigFuncType" SG_ 64 Airbag_01_BZ 1;
BA_ "GenSigSendType" SG_ 64 Airbag_01_CRC 0;
BA_ "GenSigFuncType" SG_ 64 Airbag_01_CRC 2;
BA_ "GenSigSendType" SG_ 64 SC_Masterzeit 0;
BA_ "GenSigStartValue" SG_ 64 SC_Masterzeit 127;
BA_ "GenSigSendType" SG_ 64 SC_Masterzeit_Offset 0;
BA_ "GenSigSendType" SG_ 1312 AB_Abschaltanf_SIH_BF 3;
BA_ "GenSigSendType" SG_ 1312 AB_Anforderung_eCall 0;
BA_ "GenSigSendType" SG_ 1312 AB_Anforderung_USM 0;
BA_ "GenSigSendType" SG_ 1312 AB_Anprall_FGS 3;
BA_ "GenSigSendType" SG_ 1312 AB_Anprall_Front_Beifahrer 3;
BA_ "GenSigSendType" SG_ 1312 AB_Anprall_Front_Fahrer 3;
BA_ "GenSigSendType" SG_ 1312 AB_Anprall_Heck_Beifahrer 3;
BA_ "GenSigSendType" SG_ 1312 AB_Anprall_Heck_Fahrer 3;
BA_ "GenSigSendType" SG_ 1312 AB_Anprall_Rollover 3;
BA_ "GenSigSendType" SG_ 1312 AB_Anprall_Seite_Beifahrer 3;
BA_ "GenSigSendType" SG_ 1312 AB_Anprall_Seite_Fahrer 3;
BA_ "GenSigSendType" SG_ 1312 AB_Belegung_VB 0;
BA_ "Fehlerwert" SG_ 1312 AB_Belegung_VB 1;
BA_ "GenSigSendType" SG_ 1312 AB_Crashschwere 3;
BA_ "Fehlerwert" SG_ 1312 AB_Crashschwere 7;
BA_ "GenSigSendType" SG_ 1312 AB_Gurtschloss_BF 3;
BA_ "GenSigStartValue" SG_ 1312 AB_Gurtschloss_BF 1;
BA_ "GenSigSendType" SG_ 1312 AB_Gurtschloss_FA 3;
BA_ "GenSigStartValue" SG_ 1312 AB_Gurtschloss_FA 1;
BA_ "GenSigSendType" SG_ 1312 AB_Gurtschloss_Reihe2_BF 3;
BA_ "GenSigStartValue" SG_ 1312 AB_Gurtschloss_Reihe2_BF 1;
BA_ "GenSigSendType" SG_ 1312 AB_Gurtschloss_Reihe2_FA 3;
BA_ "GenSigStartValue" SG_ 1312 AB_Gurtschloss_Reihe2_FA 1;
BA_ "GenSigSendType" SG_ 1312 AB_Gurtschloss_Reihe2_MI 3;
BA_ "GenSigStartValue" SG_ 1312 AB_Gurtschloss_Reihe2_MI 1;
BA_ "GenSigSendType" SG_ 1312 AB_Gurtschloss_Reihe3_BF 3;
BA_ "GenSigStartValue" SG_ 1312 AB_Gurtschloss_Reihe3_BF 1;
BA_ "GenSigSendType" SG_ 1312 AB_Gurtschloss_Reihe3_FA 3;
BA_ "GenSigStartValue" SG_ 1312 AB_Gurtschloss_Reihe3_FA 1;
BA_ "GenSigSendType" SG_ 1312 AB_Gurtschloss_Reihe3_MI 3;
BA_ "GenSigStartValue" SG_ 1312 AB_Gurtschloss_Reihe3_MI 1;
BA_ "GenSigSendType" SG_ 1312 AB_Sitzpos_Sens_BF 0;
BA_ "Fehlerwert" SG_ 1312 AB_Sitzpos_Sens_BF 1;
BA_ "GenSigSendType" SG_ 1312 AB_Sitzpos_Sens_FA 0;
BA_ "Fehlerwert" SG_ 1312 AB_Sitzpos_Sens_FA 1;
BA_ "GenSigSendType" SG_ 1312 AB_Wickelklappung_Reihe2_BF 3;
BA_ "GenSigStartValue" SG_ 1312 AB_Wickelklappung_Reihe2_BF 1;
BA_ "GenSigSendType" SG_ 1312 AB_Wickelklappung_Reihe2_FA 3;
BA_ "GenSigStartValue" SG_ 1312 AB_Wickelklappung_Reihe2_FA 1;
BA_ "GenSigSendType" SG_ 1312 AB_Wickelklappung_Reihe2_MI 3;
BA_ "GenSigStartValue" SG_ 1312 AB_Wickelklappung_Reihe2_MI 1;
BA_ "GenSigSendType" SG_ 1312 Airbag_02_BZ 0;
BA_ "GenSigFuncType" SG_ 1312 Airbag_02_BZ 1;
BA_ "GenSigSendType" SG_ 1312 Airbag_02_CRC 0;
BA_ "GenSigFuncType" SG_ 1312 Airbag_02_CRC 2;
BA_ "GenSigSendType" SG_ 1312 LoGeWa_Event_Kombiwarnung 3;
BA_ "GenSigSendType" SG_ 1312 SC_PAO_OFF_Anf 0;
BA_ "GenSigSendType" SG_ 1312 SC_PAO_ON_Anf 0;
BA_ "GenSigSendType" SG_ 1312 SC_PAO_Schriftzug_Anf 0;
BA_ "GenSigSendType" SG_ 65 AB_MKB_Safing 4;
BA_ "GenSigSendType" SG_ 65 Airbag_03_BZ 0;
BA_ "GenSigFuncType" SG_ 65 Airbag_03_BZ 1;
BA_ "GenSigSendType" SG_ 65 Airbag_03_CRC 0;
BA_ "GenSigFuncType" SG_ 65 Airbag_03_CRC 2;
BA_ "GenSigSendType" SG_ 280 Allrad_03_BZ 0;
BA_ "GenSigFuncType" SG_ 280 Allrad_03_BZ 1;
BA_ "GenSigSendType" SG_ 280 ALR_Charisma_FahrPr 0;
BA_ "GenSigSendType" SG_ 280 ALR_Charisma_Status 0;
BA_ "GenSigSendType" SG_ 280 ALR_Ist_Proz 0;
BA_ "GenSigStartValue" SG_ 280 ALR_Ist_Proz 254;
BA_ "Fehlerwert" SG_ 280 ALR_Ist_Proz 255;
BA_ "GenSigSendType" SG_ 280 ALR_Sendestatus 6;
BA_ "GenSigSendType" SG_ 280 ALR_Sta_Laengssperre 0;
BA_ "GenSigSendType" SG_ 897 APS_01_Paketzaehler 0;
BA_ "GenSigSendType" SG_ 897 US_GDir_VL 0;
BA_ "GenSigStartValue" SG_ 897 US_GDir_VL 15;
BA_ "GenSigSendType" SG_ 897 US_GDir_VLM 0;
BA_ "GenSigStartValue" SG_ 897 US_GDir_VLM 15;
BA_ "GenSigSendType" SG_ 897 US_GIndir_VL_VLM 0;
BA_ "GenSigStartValue" SG_ 897 US_GIndir_VL_VLM 15;
BA_ "GenSigSendType" SG_ 897 US_GIndir_VLM_VL 0;
BA_ "GenSigStartValue" SG_ 897 US_GIndir_VLM_VL 15;
BA_ "GenSigSendType" SG_ 897 US_GIndir_VLM_VRM 0;
BA_ "GenSigStartValue" SG_ 897 US_GIndir_VLM_VRM 15;
BA_ "GenSigSendType" SG_ 897 US_RDir_VL 0;
BA_ "GenSigStartValue" SG_ 897 US_RDir_VL 255;
BA_ "GenSigSendType" SG_ 897 US_RDir_VLM 0;
BA_ "GenSigStartValue" SG_ 897 US_RDir_VLM 255;
BA_ "GenSigSendType" SG_ 897 US_RIndir_VL_VLM 0;
BA_ "GenSigStartValue" SG_ 897 US_RIndir_VL_VLM 255;
BA_ "GenSigSendType" SG_ 897 US_RIndir_VLM_VL 0;
BA_ "GenSigStartValue" SG_ 897 US_RIndir_VLM_VL 255;
BA_ "GenSigSendType" SG_ 897 US_RIndir_VLM_VRM 0;
BA_ "GenSigStartValue" SG_ 897 US_RIndir_VLM_VRM 255;
BA_ "GenSigSendType" SG_ 898 APS_02_Paketzaehler 0;
BA_ "GenSigSendType" SG_ 898 US_GDir_VR 0;
BA_ "GenSigStartValue" SG_ 898 US_GDir_VR 15;
BA_ "GenSigSendType" SG_ 898 US_GDir_VRM 0;
BA_ "GenSigStartValue" SG_ 898 US_GDir_VRM 15;
BA_ "GenSigSendType" SG_ 898 US_GIndir_VR_VRM 0;
BA_ "GenSigStartValue" SG_ 898 US_GIndir_VR_VRM 15;
BA_ "GenSigSendType" SG_ 898 US_GIndir_VRM_VLM 0;
BA_ "GenSigStartValue" SG_ 898 US_GIndir_VRM_VLM 15;
BA_ "GenSigSendType" SG_ 898 US_GIndir_VRM_VR 0;
BA_ "GenSigStartValue" SG_ 898 US_GIndir_VRM_VR 15;
BA_ "GenSigSendType" SG_ 898 US_RDir_VR 0;
BA_ "GenSigStartValue" SG_ 898 US_RDir_VR 255;
BA_ "GenSigSendType" SG_ 898 US_RDir_VRM 0;
BA_ "GenSigStartValue" SG_ 898 US_RDir_VRM 255;
BA_ "GenSigSendType" SG_ 898 US_RIndir_VR_VRM 0;
BA_ "GenSigStartValue" SG_ 898 US_RIndir_VR_VRM 255;
BA_ "GenSigSendType" SG_ 898 US_RIndir_VRM_VLM 0;
BA_ "GenSigStartValue" SG_ 898 US_RIndir_VRM_VLM 255;
BA_ "GenSigSendType" SG_ 898 US_RIndir_VRM_VR 0;
BA_ "GenSigStartValue" SG_ 898 US_RIndir_VRM_VR 255;
BA_ "GenSigSendType" SG_ 927 APS_03_Paketzaehler 0;
BA_ "GenSigSendType" SG_ 927 US_Fehler_HS 0;
BA_ "Fehlerwert" SG_ 927 US_Fehler_HS 1;
BA_ "GenSigSendType" SG_ 927 US_Fehler_VS 0;
BA_ "Fehlerwert" SG_ 927 US_Fehler_VS 1;
BA_ "GenSigSendType" SG_ 927 US_NichtVerfuegbarkeit_HS 0;
BA_ "GenSigSendType" SG_ 927 US_NichtVerfuegbarkeit_VS 0;
BA_ "GenSigSendType" SG_ 927 US_RDir_HLS 0;
BA_ "GenSigStartValue" SG_ 927 US_RDir_HLS 1023;
BA_ "GenSigSendType" SG_ 927 US_RDir_HRS 0;
BA_ "GenSigStartValue" SG_ 927 US_RDir_HRS 1023;
BA_ "GenSigSendType" SG_ 927 US_RDir_VLS 0;
BA_ "GenSigStartValue" SG_ 927 US_RDir_VLS 1023;
BA_ "GenSigSendType" SG_ 927 US_RDir_VRS 0;
BA_ "GenSigStartValue" SG_ 927 US_RDir_VRS 1023;
BA_ "GenSigSendType" SG_ 927 US_Verschmutzung_HS 0;
BA_ "GenSigSendType" SG_ 927 US_Verschmutzung_VS 0;
BA_ "GenSigSendType" SG_ 896 APS_Master_Sendestatus 5;
BA_ "GenSigSendType" SG_ 896 US_ACC_BZ 0;
BA_ "GenSigFuncType" SG_ 896 US_ACC_BZ 1;
BA_ "GenSigSendType" SG_ 896 US_ACC_CRC 0;
BA_ "GenSigFuncType" SG_ 896 US_ACC_CRC 2;
BA_ "GenSigSendType" SG_ 896 US_blindness_detected 0;
BA_ "GenSigSendType" SG_ 896 US_Freie_Weglaenge_Front 0;
BA_ "GenSigStartValue" SG_ 896 US_Freie_Weglaenge_Front 510;
BA_ "Fehlerwert" SG_ 896 US_Freie_Weglaenge_Front 511;
BA_ "GenSigSendType" SG_ 896 US_Freie_Weglaenge_Front_Typ 0;
BA_ "GenSigSendType" SG_ 896 US_Freisicht_nio 0;
BA_ "GenSigSendType" SG_ 896 US_relevante_Nichtverfuegbarkeit 0;
BA_ "GenSigSendType" SG_ 896 US_relevanter_Fehler 0;
BA_ "GenSigSendType" SG_ 896 US_Sende_Modus 0;
BA_ "Fehlerwert" SG_ 896 US_Sende_Modus 15;
BA_ "GenSigSendType" SG_ 896 US_Sende_Modus_hinten 0;
BA_ "Fehlerwert" SG_ 896 US_Sende_Modus_hinten 15;
BA_ "GenSigSendType" SG_ 348 ARA_Sensor_02_red_cyclic 6;
BA_ "GenSigSendType" SG_ 348 ARA_Sensor_dt_Botschaft 0;
BA_ "GenSigSendType" SG_ 348 ARA_Sensor_Knickw_Rohwert 0;
BA_ "GenSigStartValue" SG_ 348 ARA_Sensor_Knickw_Rohwert 65534;
BA_ "Fehlerwert" SG_ 348 ARA_Sensor_Knickw_Rohwert 65535;
BA_ "GenSigSendType" SG_ 348 ARA_Sensor_Qualitaet_Grund 0;
BA_ "GenSigSendType" SG_ 348 ARA_Sensor_Qualitaet_Wert 0;
BA_ "GenSigSendType" SG_ 348 ARA_Sensor_Status 0;
BA_ "GenSigSendType" SG_ 348 ARA_Sensor_Zeitstempel_BV 0;
BA_ "GenSigSendType" SG_ 1365 AV_Charisma_FahrPr 3;
BA_ "GenSigSwitchedByIgnition" SG_ 1365 AV_Charisma_FahrPr 0;
BA_ "GenSigSendType" SG_ 1365 AV_Charisma_Status 3;
BA_ "GenSigSwitchedByIgnition" SG_ 1365 AV_Charisma_Status 0;
BA_ "GenSigSendType" SG_ 1365 AV_HEK_Status_aktiv 5;
BA_ "GenSigSwitchedByIgnition" SG_ 1365 AV_HEK_Status_aktiv 0;
BA_ "GenSigSendType" SG_ 1365 AV_HEK_Status_Anz_Punkte 0;
BA_ "GenSigSwitchedByIgnition" SG_ 1365 AV_HEK_Status_Anz_Punkte 0;
BA_ "GenSigSendType" SG_ 1365 AV_HEK_Status_Kamera_H 0;
BA_ "GenSigStartValue" SG_ 1365 AV_HEK_Status_Kamera_H 1;
BA_ "GenSigSwitchedByIgnition" SG_ 1365 AV_HEK_Status_Kamera_H 0;
BA_ "Fehlerwert" SG_ 1365 AV_HEK_Status_Kamera_H 7;
BA_ "GenSigSendType" SG_ 1365 AV_HEK_Status_Kamera_L 0;
BA_ "GenSigStartValue" SG_ 1365 AV_HEK_Status_Kamera_L 1;
BA_ "GenSigSwitchedByIgnition" SG_ 1365 AV_HEK_Status_Kamera_L 0;
BA_ "Fehlerwert" SG_ 1365 AV_HEK_Status_Kamera_L 7;
BA_ "GenSigSendType" SG_ 1365 AV_HEK_Status_Kamera_R 0;
BA_ "GenSigStartValue" SG_ 1365 AV_HEK_Status_Kamera_R 1;
BA_ "GenSigSwitchedByIgnition" SG_ 1365 AV_HEK_Status_Kamera_R 0;
BA_ "Fehlerwert" SG_ 1365 AV_HEK_Status_Kamera_R 7;
BA_ "GenSigSendType" SG_ 1365 AV_HEK_Status_Kamera_V 0;
BA_ "GenSigStartValue" SG_ 1365 AV_HEK_Status_Kamera_V 1;
BA_ "GenSigSwitchedByIgnition" SG_ 1365 AV_HEK_Status_Kamera_V 0;
BA_ "Fehlerwert" SG_ 1365 AV_HEK_Status_Kamera_V 7;
BA_ "GenSigSendType" SG_ 1365 AV_HEK_Status_Zaehler 0;
BA_ "GenSigSwitchedByIgnition" SG_ 1365 AV_HEK_Status_Zaehler 0;
BA_ "GenSigSendType" SG_ 1365 AV_Umfeldbeleuchtung_Anf 0;
BA_ "GenSigSwitchedByIgnition" SG_ 1365 AV_Umfeldbeleuchtung_Anf 0;
BA_ "GenSigSendType" SG_ 507 AV_HEK_Daten_Block 5;
BA_ "GenSigSwitchedByIgnition" SG_ 507 AV_HEK_Daten_Block 0;
BA_ "GenSigSwitchedByIgnition" SG_ 507 AV_HEK_Daten_P1_Nachfolger 0;
BA_ "GenSigSwitchedByIgnition" SG_ 507 AV_HEK_Daten_P1_Trend 0;
BA_ "GenSigStartValue" SG_ 507 AV_HEK_Daten_P1_x 255;
BA_ "GenSigSwitchedByIgnition" SG_ 507 AV_HEK_Daten_P1_x 0;
BA_ "GenSigStartValue" SG_ 507 AV_HEK_Daten_P1_y 63;
BA_ "GenSigSwitchedByIgnition" SG_ 507 AV_HEK_Daten_P1_y 0;
BA_ "GenSigSwitchedByIgnition" SG_ 507 AV_HEK_Daten_P2_Nachfolger 0;
BA_ "GenSigSwitchedByIgnition" SG_ 507 AV_HEK_Daten_P2_Trend 0;
BA_ "GenSigStartValue" SG_ 507 AV_HEK_Daten_P2_x 255;
BA_ "GenSigSwitchedByIgnition" SG_ 507 AV_HEK_Daten_P2_x 0;
BA_ "GenSigStartValue" SG_ 507 AV_HEK_Daten_P2_y 63;
BA_ "GenSigSwitchedByIgnition" SG_ 507 AV_HEK_Daten_P2_y 0;
BA_ "GenSigSwitchedByIgnition" SG_ 507 AV_HEK_Daten_P3_Nachfolger 0;
BA_ "GenSigSwitchedByIgnition" SG_ 507 AV_HEK_Daten_P3_Trend 0;
BA_ "GenSigStartValue" SG_ 507 AV_HEK_Daten_P3_x 255;
BA_ "GenSigSwitchedByIgnition" SG_ 507 AV_HEK_Daten_P3_x 0;
BA_ "GenSigStartValue" SG_ 507 AV_HEK_Daten_P3_y 63;
BA_ "GenSigSwitchedByIgnition" SG_ 507 AV_HEK_Daten_P3_y 0;
BA_ "GenSigSwitchedByIgnition" SG_ 507 AV_HEK_Daten_Zaehler 0;
BA_ "GenSigSendType" SG_ 2536711680 BAP_Brake_ASG_01_Header 3;
BA_ "GenSigSwitchedByIgnition" SG_ 2536711680 BAP_Brake_ASG_01_Header 0;
BA_ "GenSigSendType" SG_ 2536711696 BAP_Brake_FSG_01_Header 3;
BA_ "GenSigSwitchedByIgnition" SG_ 2536711696 BAP_Brake_FSG_01_Header 0;
BA_ "GenSigSendType" SG_ 2536767264 BAP_Debug_Cmd 3;
BA_ "GenSigSwitchedByIgnition" SG_ 2536767264 BAP_Debug_Cmd 0;
BA_ "GenSigSendType" SG_ 2536767280 BAP_Debug_Data 3;
BA_ "GenSigSendType" SG_ 2536704512 BAP_OPS_ASG_01_Header 3;
BA_ "GenSigSwitchedByIgnition" SG_ 2536704512 BAP_OPS_ASG_01_Header 0;
BA_ "GenSigSendType" SG_ 2536704513 BAP_OPS_ASG_02_Header 3;
BA_ "GenSigSwitchedByIgnition" SG_ 2536704513 BAP_OPS_ASG_02_Header 0;
BA_ "GenSigSendType" SG_ 2536704528 BAP_OPS_FSG_01_Header 3;
BA_ "GenSigSendType" SG_ 2536704529 BAP_OPS_FSG_02_Header 3;
BA_ "GenSigSendType" SG_ 2536703744 BAP_RDK_ASG_01_Header 3;
BA_ "GenSigSwitchedByIgnition" SG_ 2536703744 BAP_RDK_ASG_01_Header 0;
BA_ "GenSigSendType" SG_ 2536703745 BAP_RDK_ASG_02_Header 3;
BA_ "GenSigSwitchedByIgnition" SG_ 2536703745 BAP_RDK_ASG_02_Header 0;
BA_ "GenSigSendType" SG_ 2536703760 BAP_RDK_FSG_01_Header 3;
BA_ "GenSigSwitchedByIgnition" SG_ 2536703760 BAP_RDK_FSG_01_Header 0;
BA_ "GenSigSendType" SG_ 2536704768 BAP_RVC_ASG_01_Header 3;
BA_ "GenSigSwitchedByIgnition" SG_ 2536704768 BAP_RVC_ASG_01_Header 0;
BA_ "GenSigSendType" SG_ 2536704784 BAP_RVC_FSG_01_Header 3;
BA_ "GenSigSwitchedByIgnition" SG_ 2536704784 BAP_RVC_FSG_01_Header 0;
BA_ "GenSigSendType" SG_ 869 BEM_01_Abschaltstufen 0;
BA_ "GenSigSwitchedByIgnition" SG_ 869 BEM_01_Abschaltstufen 0;
BA_ "GenSigSendType" SG_ 869 BEM_Anf_KL 0;
BA_ "GenSigSwitchedByIgnition" SG_ 869 BEM_Anf_KL 0;
BA_ "GenSigSendType" SG_ 869 BEM_Batt_Ab 0;
BA_ "GenSigSwitchedByIgnition" SG_ 869 BEM_Batt_Ab 0;
BA_ "GenSigSendType" SG_ 869 BEM_DFM 0;
BA_ "GenSigSwitchedByIgnition" SG_ 869 BEM_DFM 0;
BA_ "GenSigSendType" SG_ 869 BEM_EMLIN_ungueltig 0;
BA_ "GenSigSwitchedByIgnition" SG_ 869 BEM_EMLIN_ungueltig 0;
BA_ "GenSigSendType" SG_ 869 BEM_HYB_DC_uMinLV 0;
BA_ "GenSigStartValue" SG_ 869 BEM_HYB_DC_uMinLV 254;
BA_ "GenSigSwitchedByIgnition" SG_ 869 BEM_HYB_DC_uMinLV 0;
BA_ "Fehlerwert" SG_ 869 BEM_HYB_DC_uMinLV 255;
BA_ "GenSigSendType" SG_ 869 BEM_HYB_DC_uSollLV 0;
BA_ "GenSigStartValue" SG_ 869 BEM_HYB_DC_uSollLV 37;
BA_ "GenSigSwitchedByIgnition" SG_ 869 BEM_HYB_DC_uSollLV 0;
BA_ "GenSigSendType" SG_ 869 BEM_n_LLA 0;
BA_ "GenSigSwitchedByIgnition" SG_ 869 BEM_n_LLA 0;
BA_ "GenSigSendType" SG_ 869 BEM_NV_NachladAnf 0;
BA_ "GenSigSwitchedByIgnition" SG_ 869 BEM_NV_NachladAnf 0;
BA_ "Fehlerwert" SG_ 869 BEM_NV_NachladAnf 3;
BA_ "GenSigSendType" SG_ 869 BEM_P_Generator 0;
BA_ "GenSigSwitchedByIgnition" SG_ 869 BEM_P_Generator 0;
BA_ "Fehlerwert" SG_ 869 BEM_P_Generator 255;
BA_ "GenSigSendType" SG_ 869 BEM_Segel_Info 0;
BA_ "GenSigSwitchedByIgnition" SG_ 869 BEM_Segel_Info 0;
BA_ "GenSigSendType" SG_ 869 BEM_StartStopp_Info 0;
BA_ "GenSigSwitchedByIgnition" SG_ 869 BEM_StartStopp_Info 0;
BA_ "GenSigSendType" SG_ 869 BEM_UBDM 0;
BA_ "GenSigSwitchedByIgnition" SG_ 869 BEM_UBDM 0;
BA_ "Fehlerwert" SG_ 869 BEM_UBDM 255;
BA_ "GenSigSendType" SG_ 869 NVEM_FMAus_I_Verbrauch 0;
BA_ "GenSigStartValue" SG_ 869 NVEM_FMAus_I_Verbrauch 30;
BA_ "GenSigSwitchedByIgnition" SG_ 869 NVEM_FMAus_I_Verbrauch 0;
BA_ "Fehlerwert" SG_ 869 NVEM_FMAus_I_Verbrauch 31;
BA_ "GenSigSendType" SG_ 869 NVEM_FMAus_Info 0;
BA_ "GenSigStartValue" SG_ 869 NVEM_FMAus_Info 1;
BA_ "GenSigSwitchedByIgnition" SG_ 869 NVEM_FMAus_Info 0;
BA_ "GenSigSendType" SG_ 869 NVEM_Freilauf_Info 0;
BA_ "GenSigSwitchedByIgnition" SG_ 869 NVEM_Freilauf_Info 0;
BA_ "GenSigSendType" SG_ 869 NVEM_Ladefreigabe 0;
BA_ "GenSigSwitchedByIgnition" SG_ 869 NVEM_Ladefreigabe 0;
BA_ "GenSigSendType" SG_ 869 NVEM_PTC_Sollstufe 0;
BA_ "GenSigSwitchedByIgnition" SG_ 869 NVEM_PTC_Sollstufe 0;
BA_ "GenSigSendType" SG_ 870 Blinken_li_Fzg_Takt 4;
BA_ "GenSigSwitchedByIgnition" SG_ 870 Blinken_li_Fzg_Takt 0;
BA_ "GenSigSendType" SG_ 870 Blinken_li_Kombi_Takt 4;
BA_ "GenSigSwitchedByIgnition" SG_ 870 Blinken_li_Kombi_Takt 0;
BA_ "GenSigSendType" SG_ 870 Blinken_re_Fzg_Takt 4;
BA_ "GenSigSwitchedByIgnition" SG_ 870 Blinken_re_Fzg_Takt 0;
BA_ "GenSigSendType" SG_ 870 Blinken_re_Kombi_Takt 4;
BA_ "GenSigSwitchedByIgnition" SG_ 870 Blinken_re_Kombi_Takt 0;
BA_ "GenSigSendType" SG_ 870 BM_Autobahn 4;
BA_ "GenSigSwitchedByIgnition" SG_ 870 BM_Autobahn 0;
BA_ "GenSigSendType" SG_ 870 BM_Crash 4;
BA_ "GenSigSwitchedByIgnition" SG_ 870 BM_Crash 0;
BA_ "GenSigSendType" SG_ 870 BM_DWA_Alarm 4;
BA_ "GenSigSwitchedByIgnition" SG_ 870 BM_DWA_Alarm 0;
BA_ "GenSigSendType" SG_ 870 BM_DWA_ein 4;
BA_ "GenSigSwitchedByIgnition" SG_ 870 BM_DWA_ein 0;
BA_ "GenSigSendType" SG_ 870 BM_GDO 4;
BA_ "GenSigSwitchedByIgnition" SG_ 870 BM_GDO 0;
BA_ "GenSigSendType" SG_ 870 BM_HD_Oeffnung_angelernt 3;
BA_ "GenSigSwitchedByIgnition" SG_ 870 BM_HD_Oeffnung_angelernt 0;
BA_ "GenSigSendType" SG_ 870 BM_links 4;
BA_ "GenSigSwitchedByIgnition" SG_ 870 BM_links 0;
BA_ "GenSigSendType" SG_ 870 BM_NBA_n_codiert_n_aktiv 3;
BA_ "GenSigStartValue" SG_ 870 BM_NBA_n_codiert_n_aktiv 1;
BA_ "GenSigSwitchedByIgnition" SG_ 870 BM_NBA_n_codiert_n_aktiv 0;
BA_ "GenSigSendType" SG_ 870 BM_NBA_Status 4;
BA_ "GenSigSwitchedByIgnition" SG_ 870 BM_NBA_Status 0;
BA_ "GenSigSendType" SG_ 870 BM_Not_Bremsung 4;
BA_ "GenSigSwitchedByIgnition" SG_ 870 BM_Not_Bremsung 0;
BA_ "GenSigSendType" SG_ 870 BM_Panik 4;
BA_ "GenSigSwitchedByIgnition" SG_ 870 BM_Panik 0;
BA_ "GenSigSendType" SG_ 870 BM_PiloPa 4;
BA_ "GenSigSwitchedByIgnition" SG_ 870 BM_PiloPa 0;
BA_ "GenSigSendType" SG_ 870 BM_Recas 5;
BA_ "GenSigSwitchedByIgnition" SG_ 870 BM_Recas 0;
BA_ "GenSigSendType" SG_ 870 BM_rechts 4;
BA_ "GenSigSwitchedByIgnition" SG_ 870 BM_rechts 0;
BA_ "GenSigSendType" SG_ 870 BM_Rollenmodus_Blinken 5;
BA_ "GenSigSwitchedByIgnition" SG_ 870 BM_Rollenmodus_Blinken 0;
BA_ "GenSigSendType" SG_ 870 BM_Taxi_Notalarm 4;
BA_ "GenSigSwitchedByIgnition" SG_ 870 BM_Taxi_Notalarm 0;
BA_ "GenSigSendType" SG_ 870 BM_Telematik 4;
BA_ "GenSigSwitchedByIgnition" SG_ 870 BM_Telematik 0;
BA_ "GenSigSendType" SG_ 870 BM_Telematik_Abbruchgrund 4;
BA_ "GenSigSwitchedByIgnition" SG_ 870 BM_Telematik_Abbruchgrund 0;
BA_ "GenSigSendType" SG_ 870 BM_Warnblinken 4;
BA_ "GenSigSwitchedByIgnition" SG_ 870 BM_Warnblinken 0;
BA_ "GenSigSendType" SG_ 870 BM_WBT_Beleuchtung 3;
BA_ "GenSigSwitchedByIgnition" SG_ 870 BM_WBT_Beleuchtung 0;
BA_ "GenSigSendType" SG_ 870 BM_Wischblinken 4;
BA_ "GenSigSwitchedByIgnition" SG_ 870 BM_Wischblinken 0;
BA_ "GenSigSendType" SG_ 870 BM_ZV_auf 4;
BA_ "GenSigSwitchedByIgnition" SG_ 870 BM_ZV_auf 0;
BA_ "GenSigSendType" SG_ 870 BM_ZV_zu 4;
BA_ "GenSigSwitchedByIgnition" SG_ 870 BM_ZV_zu 0;
BA_ "GenSigFuncType" SG_ 2281471488 CCP_Allrad_CRO_01_Data 9;
BA_ "GenSigSwitchedByIgnition" SG_ 2281471488 CCP_Allrad_CRO_01_Data 0;
BA_ "GenSigFuncType" SG_ 2281471489 CCP_Allrad_DTO_01_Data 9;
BA_ "GenSigFuncType" SG_ 2281477632 CCP_Lenkhilfe_CRO_01_Data 9;
BA_ "GenSigSwitchedByIgnition" SG_ 2281477632 CCP_Lenkhilfe_CRO_01_Data 0;
BA_ "GenSigFuncType" SG_ 2281477634 CCP_Lenkhilfe_CRO_02_Data 9;
BA_ "GenSigSwitchedByIgnition" SG_ 2281477634 CCP_Lenkhilfe_CRO_02_Data 0;
BA_ "GenSigFuncType" SG_ 2281477633 CCP_Lenkhilfe_DTO_01_Data 9;
BA_ "GenSigSwitchedByIgnition" SG_ 2281477633 CCP_Lenkhilfe_DTO_01_Data 0;
BA_ "GenSigFuncType" SG_ 2281477635 CCP_Lenkhilfe_DTO_02_Data 9;
BA_ "GenSigSwitchedByIgnition" SG_ 2281477635 CCP_Lenkhilfe_DTO_02_Data 0;
BA_ "GenSigSendType" SG_ 901 CHA_Fahrer_Umschaltung 3;
BA_ "GenSigSwitchedByIgnition" SG_ 901 CHA_Fahrer_Umschaltung 0;
BA_ "GenSigSendType" SG_ 901 CHA_Fahrer_Umschaltung_BMA 3;
BA_ "GenSigSwitchedByIgnition" SG_ 901 CHA_Fahrer_Umschaltung_BMA 0;
BA_ "GenSigSendType" SG_ 901 CHA_Ziel_FahrPr_ACC 3;
BA_ "GenSigSwitchedByIgnition" SG_ 901 CHA_Ziel_FahrPr_ACC 0;
BA_ "GenSigSendType" SG_ 901 CHA_Ziel_FahrPr_AFS 3;
BA_ "GenSigSwitchedByIgnition" SG_ 901 CHA_Ziel_FahrPr_AFS 0;
BA_ "GenSigSendType" SG_ 901 CHA_Ziel_FahrPr_AGA 3;
BA_ "GenSigSwitchedByIgnition" SG_ 901 CHA_Ziel_FahrPr_AGA 0;
BA_ "GenSigSendType" SG_ 901 CHA_Ziel_FahrPr_ALR 3;
BA_ "GenSigSwitchedByIgnition" SG_ 901 CHA_Ziel_FahrPr_ALR 0;
BA_ "GenSigSendType" SG_ 901 CHA_Ziel_FahrPr_DR 3;
BA_ "GenSigSwitchedByIgnition" SG_ 901 CHA_Ziel_FahrPr_DR 0;
BA_ "GenSigSendType" SG_ 901 CHA_Ziel_FahrPr_EPS 3;
BA_ "GenSigSwitchedByIgnition" SG_ 901 CHA_Ziel_FahrPr_EPS 0;
BA_ "GenSigSendType" SG_ 901 CHA_Ziel_FahrPr_ESP 3;
BA_ "GenSigSwitchedByIgnition" SG_ 901 CHA_Ziel_FahrPr_ESP 0;
BA_ "GenSigSendType" SG_ 901 CHA_Ziel_FahrPr_Freilauf 3;
BA_ "GenSigSwitchedByIgnition" SG_ 901 CHA_Ziel_FahrPr_Freilauf 0;
BA_ "GenSigSendType" SG_ 901 CHA_Ziel_FahrPr_GE 3;
BA_ "GenSigSwitchedByIgnition" SG_ 901 CHA_Ziel_FahrPr_GE 0;
BA_ "GenSigSendType" SG_ 901 CHA_Ziel_FahrPr_MO 3;
BA_ "GenSigSwitchedByIgnition" SG_ 901 CHA_Ziel_FahrPr_MO 0;
BA_ "GenSigSendType" SG_ 901 CHA_Ziel_FahrPr_MO_BZS 3;
BA_ "GenSigSwitchedByIgnition" SG_ 901 CHA_Ziel_FahrPr_MO_BZS 0;
BA_ "GenSigSendType" SG_ 901 CHA_Ziel_FahrPr_MO_StSt 3;
BA_ "GenSigSwitchedByIgnition" SG_ 901 CHA_Ziel_FahrPr_MO_StSt 0;
BA_ "GenSigSendType" SG_ 901 CHA_Ziel_FahrPr_RGS 3;
BA_ "GenSigSwitchedByIgnition" SG_ 901 CHA_Ziel_FahrPr_RGS 0;
BA_ "GenSigSendType" SG_ 901 CHA_Ziel_FahrPr_SAK 3;
BA_ "GenSigSwitchedByIgnition" SG_ 901 CHA_Ziel_FahrPr_SAK 0;
BA_ "GenSigSendType" SG_ 901 CHA_Ziel_FahrPr_VAQ 3;
BA_ "GenSigSwitchedByIgnition" SG_ 901 CHA_Ziel_FahrPr_VAQ 0;
BA_ "GenSigSendType" SG_ 1000 CHA_Current_Mode 3;
BA_ "GenSigSwitchedByIgnition" SG_ 1000 CHA_Current_Mode 0;
BA_ "GenSigSendType" SG_ 1000 CHA_Fahrer_Umschaltung 3;
BA_ "GenSigSwitchedByIgnition" SG_ 1000 CHA_Fahrer_Umschaltung 0;
BA_ "GenSigSendType" SG_ 1000 CHA_Ziel_FahrPr_AEB 3;
BA_ "GenSigSwitchedByIgnition" SG_ 1000 CHA_Ziel_FahrPr_AEB 0;
BA_ "GenSigSendType" SG_ 1000 CHA_Ziel_FahrPr_AFR 3;
BA_ "GenSigSwitchedByIgnition" SG_ 1000 CHA_Ziel_FahrPr_AFR 0;
BA_ "GenSigSendType" SG_ 1000 CHA_Ziel_FahrPr_AV 3;
BA_ "GenSigSwitchedByIgnition" SG_ 1000 CHA_Ziel_FahrPr_AV 0;
BA_ "GenSigSendType" SG_ 1000 CHA_Ziel_FahrPr_EAR 3;
BA_ "GenSigSwitchedByIgnition" SG_ 1000 CHA_Ziel_FahrPr_EAR 0;
BA_ "GenSigSendType" SG_ 1000 CHA_Ziel_FahrPr_EBKV 3;
BA_ "GenSigSwitchedByIgnition" SG_ 1000 CHA_Ziel_FahrPr_EBKV 0;
BA_ "GenSigSendType" SG_ 1000 CHA_Ziel_FahrPr_FCWO 3;
BA_ "GenSigSwitchedByIgnition" SG_ 1000 CHA_Ziel_FahrPr_FCWO 0;
BA_ "GenSigSendType" SG_ 1000 CHA_Ziel_FahrPr_FCWP 3;
BA_ "GenSigSwitchedByIgnition" SG_ 1000 CHA_Ziel_FahrPr_FCWP 0;
BA_ "GenSigSendType" SG_ 1000 CHA_Ziel_FahrPr_HAL 3;
BA_ "GenSigSwitchedByIgnition" SG_ 1000 CHA_Ziel_FahrPr_HAL 0;
BA_ "GenSigSendType" SG_ 1000 CHA_Ziel_FahrPr_HDC 3;
BA_ "GenSigSwitchedByIgnition" SG_ 1000 CHA_Ziel_FahrPr_HDC 0;
BA_ "GenSigSendType" SG_ 1000 CHA_Ziel_FahrPr_IL 3;
BA_ "GenSigSwitchedByIgnition" SG_ 1000 CHA_Ziel_FahrPr_IL 0;
BA_ "GenSigSendType" SG_ 1000 CHA_Ziel_FahrPr_MXB 3;
BA_ "GenSigSwitchedByIgnition" SG_ 1000 CHA_Ziel_FahrPr_MXB 0;
BA_ "GenSigSendType" SG_ 1000 CHA_Ziel_FahrPr_NR 3;
BA_ "GenSigSwitchedByIgnition" SG_ 1000 CHA_Ziel_FahrPr_NR 0;
BA_ "GenSigSendType" SG_ 1000 CHA_Ziel_FahrPr_QS 3;
BA_ "GenSigSwitchedByIgnition" SG_ 1000 CHA_Ziel_FahrPr_QS 0;
BA_ "GenSigSendType" SG_ 1000 CHA_Ziel_FahrPr_SCU 3;
BA_ "GenSigSwitchedByIgnition" SG_ 1000 CHA_Ziel_FahrPr_SCU 0;
BA_ "GenSigSendType" SG_ 1022 CHA_Current_Mode_BMA 3;
BA_ "GenSigSwitchedByIgnition" SG_ 1022 CHA_Current_Mode_BMA 0;
BA_ "GenSigSendType" SG_ 1022 CHA_Fahrer_Umschaltung 3;
BA_ "GenSigSwitchedByIgnition" SG_ 1022 CHA_Fahrer_Umschaltung 0;
BA_ "GenSigSendType" SG_ 1022 CHA_Fahrer_Umschaltung_BMA 3;
BA_ "GenSigSwitchedByIgnition" SG_ 1022 CHA_Fahrer_Umschaltung_BMA 0;
BA_ "GenSigSendType" SG_ 1022 CHA_Ziel_FahrPr_AGK 3;
BA_ "GenSigSwitchedByIgnition" SG_ 1022 CHA_Ziel_FahrPr_AGK 0;
BA_ "GenSigSendType" SG_ 1022 CHA_Ziel_FahrPr_BMS 3;
BA_ "GenSigSwitchedByIgnition" SG_ 1022 CHA_Ziel_FahrPr_BMS 0;
BA_ "GenSigSendType" SG_ 1022 CHA_Ziel_FahrPr_EDS 3;
BA_ "GenSigSwitchedByIgnition" SG_ 1022 CHA_Ziel_FahrPr_EDS 0;
BA_ "GenSigSendType" SG_ 1022 CHA_Ziel_FahrPr_HHC 3;
BA_ "GenSigSwitchedByIgnition" SG_ 1022 CHA_Ziel_FahrPr_HHC 0;
BA_ "GenSigSendType" SG_ 1022 CHA_Ziel_FahrPr_MO_Freilauf 3;
BA_ "GenSigSwitchedByIgnition" SG_ 1022 CHA_Ziel_FahrPr_MO_Freilauf 0;
BA_ "GenSigSendType" SG_ 1022 CHA_Ziel_FahrPr_PACC 3;
BA_ "GenSigSwitchedByIgnition" SG_ 1022 CHA_Ziel_FahrPr_PACC 0;
BA_ "GenSigSendType" SG_ 1022 CHA_Ziel_FahrPr_PDC 3;
BA_ "GenSigSwitchedByIgnition" SG_ 1022 CHA_Ziel_FahrPr_PDC 0;
BA_ "GenSigSendType" SG_ 918 Daempfer_01_BZ 0;
BA_ "GenSigFuncType" SG_ 918 Daempfer_01_BZ 1;
BA_ "GenSigSendType" SG_ 918 Daempfer_01_CRC 0;
BA_ "GenSigFuncType" SG_ 918 Daempfer_01_CRC 2;
BA_ "GenSigSendType" SG_ 918 DR_Charisma_FahrPr 0;
BA_ "GenSigSendType" SG_ 918 DR_Charisma_Status 0;
BA_ "GenSigSendType" SG_ 918 DR_Daempferreg_Texte 0;
BA_ "GenSigSendType" SG_ 918 DR_DynAGL_Anf_Entkopplung 0;
BA_ "GenSigSendType" SG_ 918 DR_DynAGL_Anf_im_Leerlauf 0;
BA_ "GenSigSendType" SG_ 918 DR_DynAGL_Warnlampe 0;
BA_ "GenSigSendType" SG_ 918 DR_Fahrzeugart 0;
BA_ "GenSigFuncType" SG_ 918 DR_Fahrzeugart 8;
BA_ "GenSigSendType" SG_ 918 DR_Gelbe_Warnlampe 0;
BA_ "GenSigSendType" SG_ 918 DR_Rote_Warnlampe 0;
BA_ "GenSigSendType" SG_ 918 DR_Systemstatus 0;
BA_ "GenSigSendType" SG_ 918 DR_Taster 0;
BA_ "GenSigSendType" SG_ 918 LF_Texte 0;
BA_ "GenSigSendType" SG_ 918 LF_Warnung_Prio1 0;
BA_ "GenSigSendType" SG_ 918 LF_Warnung_Prio2 0;
BA_ "GenSigSendType" SG_ 918 NI_Status 0;
BA_ "Fehlerwert" SG_ 918 NI_Status 7;
BA_ "GenSigSendType" SG_ 918 NR_Niveaufunktion_aktiv 0;
BA_ "GenSigSwitchedByIgnition" SG_ 2617199107 DEV_AreaViewHEK_00_Data 0;
BA_ "GenSigSwitchedByIgnition" SG_ 2617199108 DEV_AreaViewHEK_01_Data 0;
BA_ "GenSigSwitchedByIgnition" SG_ 2617199109 DEV_AreaViewHEK_02_Data 0;
BA_ "GenSigSwitchedByIgnition" SG_ 2617199110 DEV_AreaViewHEK_03_Data 0;
BA_ "GenSigSwitchedByIgnition" SG_ 2617199111 DEV_AreaViewHEK_04_Data 0;
BA_ "GenSigSwitchedByIgnition" SG_ 2617199112 DEV_AreaViewHEK_05_Data 0;
BA_ "GenSigSwitchedByIgnition" SG_ 2617199113 DEV_AreaViewHEK_06_Data 0;
BA_ "GenSigSwitchedByIgnition" SG_ 2617199114 DEV_AreaViewHEK_07_Data 0;
BA_ "GenSigSwitchedByIgnition" SG_ 2617199115 DEV_AreaViewHEK_08_Data 0;
BA_ "GenSigSwitchedByIgnition" SG_ 2617199116 DEV_AreaViewHEK_09_Data 0;
BA_ "GenSigSwitchedByIgnition" SG_ 2617199117 DEV_AreaViewHEK_10_Data 0;
BA_ "GenSigSwitchedByIgnition" SG_ 2617199118 DEV_AreaViewHEK_11_Data 0;
BA_ "GenSigSwitchedByIgnition" SG_ 2617199119 DEV_AreaViewHEK_12_Data 0;
BA_ "GenSigSwitchedByIgnition" SG_ 2617199120 DEV_AreaViewHEK_13_Data 0;
BA_ "GenSigSwitchedByIgnition" SG_ 2617199121 DEV_AreaViewHEK_14_Data 0;
BA_ "GenSigSwitchedByIgnition" SG_ 2617199122 DEV_AreaViewHEK_15_Data 0;
BA_ "GenSigSwitchedByIgnition" SG_ 2617217541 DEV_Daempfer_Req_05_Data 0;
BA_ "GenSigSwitchedByIgnition" SG_ 2617217542 DEV_Daempfer_Req_06_Data 0;
BA_ "GenSigSwitchedByIgnition" SG_ 2617152000 DEV_EPB_Resp_00_Data 0;
BA_ "GenSigSwitchedByIgnition" SG_ 2617152001 DEV_EPB_Resp_01_Data 0;
BA_ "GenSigSwitchedByIgnition" SG_ 2617152002 DEV_EPB_Resp_02_Data 0;
BA_ "GenSigSwitchedByIgnition" SG_ 2617152003 DEV_EPB_Resp_03_Data 0;
BA_ "GenSigSwitchedByIgnition" SG_ 2617152004 DEV_EPB_Resp_04_Data 0;
BA_ "GenSigSwitchedByIgnition" SG_ 2617152005 DEV_EPB_Resp_05_Data 0;
BA_ "GenSigSwitchedByIgnition" SG_ 2617022976 DEV_ESP_Resp_00_Data 0;
BA_ "GenSigSwitchedByIgnition" SG_ 2617022977 DEV_ESP_Resp_01_Data 0;
BA_ "GenSigSwitchedByIgnition" SG_ 2617022978 DEV_ESP_Resp_02_Data 0;
BA_ "GenSigSwitchedByIgnition" SG_ 2617022979 DEV_ESP_Resp_03_Data 0;
BA_ "GenSigSwitchedByIgnition" SG_ 2617022980 DEV_ESP_Resp_04_Data 0;
BA_ "GenSigSwitchedByIgnition" SG_ 2617022981 DEV_ESP_Resp_05_Data 0;
BA_ "GenSigSwitchedByIgnition" SG_ 2617020965 DEV_Lenkhilfe_AZG_Req_01_Data 0;
BA_ "GenSigSwitchedByIgnition" SG_ 2617020962 DEV_Lenkhilfe_AZG_Resp_01_Data 0;
BA_ "GenSigSwitchedByIgnition" SG_ 2617020963 DEV_Lenkhilfe_CANT_Req_01_Data 0;
BA_ "GenSigSwitchedByIgnition" SG_ 2617020964 DEV_Lenkhilfe_CANT_Resp_01_Data 0;
BA_ "GenSigSwitchedByIgnition" SG_ 2617020928 DEV_Lenkhilfe_Resp_00_Data 0;
BA_ "GenSigSwitchedByIgnition" SG_ 2617020929 DEV_Lenkhilfe_Resp_01_Data 0;
BA_ "GenSigSwitchedByIgnition" SG_ 2617020930 DEV_Lenkhilfe_Resp_02_Data 0;
BA_ "GenSigSwitchedByIgnition" SG_ 2617020931 DEV_Lenkhilfe_Resp_03_Data 0;
BA_ "GenSigSwitchedByIgnition" SG_ 2617020932 DEV_Lenkhilfe_Resp_04_Data 0;
BA_ "GenSigSwitchedByIgnition" SG_ 2617020933 DEV_Lenkhilfe_Resp_05_Data 0;
BA_REL_ "GenSigTimeoutTime" BU_SG_REL_ Allrad_Haldex SG_ 901 CHA_Ziel_FahrPr_ALR 5000;
BA_REL_ "GenSigTimeoutTime" BU_SG_REL_ AreaView_MQB SG_ 2536704528 BAP_OPS_FSG_01_Header 5000;
BA_REL_ "GenSigTimeoutTime" BU_SG_REL_ AreaView_MQB SG_ 2536704529 BAP_OPS_FSG_02_Header 5000;
BA_REL_ "GenSigTimeoutTime" BU_SG_REL_ AreaView_MQB SG_ 2536704768 BAP_RVC_ASG_01_Header 800;
BA_REL_ "GenSigTimeoutTime" BU_SG_REL_ AreaView_MQB SG_ 1000 CHA_Ziel_FahrPr_AV 5000;
BA_REL_ "GenSigTimeoutTime" BU_SG_REL_ Bremse_ABS_MK100 SG_ 64 Airbag_01_CRC 500;
BA_REL_ "GenSigTimeoutTime" BU_SG_REL_ Bremse_ABS_MK100 SG_ 64 Airbag_01_BZ 500;
BA_REL_ "GenSigTimeoutTime" BU_SG_REL_ Bremse_ABS_MK100 SG_ 64 AB_Rollover_Crash 500;
BA_REL_ "GenSigTimeoutTime" BU_SG_REL_ Bremse_ABS_MK100 SG_ 64 AB_Crash_Int 500;
BA_REL_ "GenSigTimeoutTime" BU_SG_REL_ Bremse_ABS_MK100 SG_ 1312 AB_Gurtschloss_FA 2000;
BA_REL_ "GenSigTimeoutTime" BU_SG_REL_ Bremse_ABS_MK100 SG_ 870 BM_Warnblinken 5000;
BA_REL_ "GenSigTimeoutTime" BU_SG_REL_ Bremse_ESP_EPB_EBC460Vi SG_ 302 ACC_07_CRC 500;
BA_REL_ "GenSigTimeoutTime" BU_SG_REL_ Bremse_ESP_EPB_EBC460Vi SG_ 302 ACC_07_BZ 500;
BA_REL_ "GenSigTimeoutTime" BU_SG_REL_ Bremse_ESP_EPB_EBC460Vi SG_ 302 ACC_Anhalteweg 500;
BA_REL_ "GenSigTimeoutTime" BU_SG_REL_ Bremse_ESP_EPB_EBC460Vi SG_ 302 ACC_Anhalten 500;
BA_REL_ "GenSigTimeoutTime" BU_SG_REL_ Bremse_ESP_EPB_EBC460Vi SG_ 302 ACC_Anfahren 500;
BA_REL_ "GenSigTimeoutTime" BU_SG_REL_ Bremse_ESP_EPB_EBC460Vi SG_ 279 ACC_10_CRC 500;
BA_REL_ "GenSigTimeoutTime" BU_SG_REL_ Bremse_ESP_EPB_EBC460Vi SG_ 279 ACC_10_BZ 500;
BA_REL_ "GenSigTimeoutTime" BU_SG_REL_ Bremse_ESP_EPB_EBC460Vi SG_ 279 AWV1_Anf_Prefill 500;
BA_REL_ "GenSigTimeoutTime" BU_SG_REL_ Bremse_ESP_EPB_EBC460Vi SG_ 279 ANB_CM_Info 500;
BA_REL_ "GenSigTimeoutTime" BU_SG_REL_ Bremse_ESP_EPB_EBC460Vi SG_ 279 AWV2_Freigabe 500;
BA_REL_ "GenSigTimeoutTime" BU_SG_REL_ Bremse_ESP_EPB_EBC460Vi SG_ 279 AWV1_HBA_Param 500;
BA_REL_ "GenSigTimeoutTime" BU_SG_REL_ Bremse_ESP_EPB_EBC460Vi SG_ 279 AWV2_Ruckprofil 500;
BA_REL_ "GenSigTimeoutTime" BU_SG_REL_ Bremse_ESP_EPB_EBC460Vi SG_ 279 ANB_CM_Anforderung 500;
BA_REL_ "GenSigTimeoutTime" BU_SG_REL_ Bremse_ESP_EPB_EBC460Vi SG_ 279 ANB_Teilbremsung_Freigabe 500;
BA_REL_ "GenSigTimeoutTime" BU_SG_REL_ Bremse_ESP_EPB_EBC460Vi SG_ 279 ANB_Zielbrems_Teilbrems_Verz_Anf 500;
BA_REL_ "GenSigTimeoutTime" BU_SG_REL_ Bremse_ESP_EPB_EBC460Vi SG_ 279 ANB_Zielbremsung_Freigabe 500;
BA_REL_ "GenSigTimeoutTime" BU_SG_REL_ Bremse_ESP_EPB_EBC460Vi SG_ 279 AWV_Vorstufe 500;
BA_REL_ "GenSigTimeoutTime" BU_SG_REL_ Bremse_ESP_EPB_EBC460Vi SG_ 279 AWV_Halten 500;
BA_REL_ "GenSigTimeoutTime" BU_SG_REL_ Bremse_ESP_EPB_EBC460Vi SG_ 279 AWV_CityANB_Auspraegung 500;
BA_REL_ "GenSigTimeoutTime" BU_SG_REL_ Bremse_ESP_EPB_EBC460Vi SG_ 279 AWV1_ECD_Anlauf 500;
BA_REL_ "GenSigTimeoutTime" BU_SG_REL_ Bremse_ESP_EPB_EBC460Vi SG_ 64 Airbag_01_CRC 500;
BA_REL_ "GenSigTimeoutTime" BU_SG_REL_ Bremse_ESP_EPB_EBC460Vi SG_ 64 Airbag_01_BZ 500;
BA_REL_ "GenSigTimeoutTime" BU_SG_REL_ Bremse_ESP_EPB_EBC460Vi SG_ 64 AB_Front_Crash 500;
BA_REL_ "GenSigTimeoutTime" BU_SG_REL_ Bremse_ESP_EPB_EBC460Vi SG_ 64 AB_Heck_Crash 500;
BA_REL_ "GenSigTimeoutTime" BU_SG_REL_ Bremse_ESP_EPB_EBC460Vi SG_ 64 AB_SF_Crash 500;
BA_REL_ "GenSigTimeoutTime" BU_SG_REL_ Bremse_ESP_EPB_EBC460Vi SG_ 64 AB_SB_Crash 500;
BA_REL_ "GenSigTimeoutTime" BU_SG_REL_ Bremse_ESP_EPB_EBC460Vi SG_ 64 AB_Rollover_Crash 500;
BA_REL_ "GenSigTimeoutTime" BU_SG_REL_ Bremse_ESP_EPB_EBC460Vi SG_ 64 AB_Crash_Int 500;
BA_REL_ "GenSigTimeoutTime" BU_SG_REL_ Bremse_ESP_EPB_EBC460Vi SG_ 64 AB_MKB_gueltig 500;
BA_REL_ "GenSigTimeoutTime" BU_SG_REL_ Bremse_ESP_EPB_EBC460Vi SG_ 64 AB_MKB_Anforderung 500;
BA_REL_ "GenSigTimeoutTime" BU_SG_REL_ Bremse_ESP_EPB_EBC460Vi SG_ 64 SC_Masterzeit_Offset 500;
BA_REL_ "GenSigTimeoutTime" BU_SG_REL_ Bremse_ESP_EPB_EBC460Vi SG_ 64 SC_Masterzeit 500;
BA_REL_ "GenSigTimeoutTime" BU_SG_REL_ Bremse_ESP_EPB_EBC460Vi SG_ 1312 AB_Gurtschloss_FA 2000;
BA_REL_ "GenSigTimeoutTime" BU_SG_REL_ Bremse_ESP_EPB_EBC460Vi SG_ 65 Airbag_03_CRC 5000;
BA_REL_ "GenSigTimeoutTime" BU_SG_REL_ Bremse_ESP_EPB_EBC460Vi SG_ 65 Airbag_03_BZ 5000;
BA_REL_ "GenSigTimeoutTime" BU_SG_REL_ Bremse_ESP_EPB_EBC460Vi SG_ 65 AB_MKB_Safing 5000;
BA_REL_ "GenSigTimeoutTime" BU_SG_REL_ Bremse_ESP_EPB_EBC460Vi SG_ 280 Allrad_03_BZ 1000;
BA_REL_ "GenSigTimeoutTime" BU_SG_REL_ Bremse_ESP_EPB_EBC460Vi SG_ 280 ALR_Sta_Laengssperre 1000;
BA_REL_ "GenSigTimeoutTime" BU_SG_REL_ Bremse_ESP_EPB_EBC460Vi SG_ 280 ALR_Ist_Proz 1000;
BA_REL_ "GenSigTimeoutTime" BU_SG_REL_ Bremse_ESP_EPB_EBC460Vi SG_ 2536711680 BAP_Brake_ASG_01_Header 800;
BA_REL_ "GenSigTimeoutTime" BU_SG_REL_ Bremse_ESP_EPB_EBC460Vi SG_ 2536703744 BAP_RDK_ASG_01_Header 800;
BA_REL_ "GenSigTimeoutTime" BU_SG_REL_ Bremse_ESP_EPB_EBC460Vi SG_ 2536703745 BAP_RDK_ASG_02_Header 800;
BA_REL_ "GenSigTimeoutTime" BU_SG_REL_ Bremse_ESP_EPB_EBC460Vi SG_ 869 BEM_P_Generator 500;
BA_REL_ "GenSigTimeoutTime" BU_SG_REL_ Bremse_ESP_EPB_EBC460Vi SG_ 870 BM_Warnblinken 5000;
BA_REL_ "GenSigTimeoutTime" BU_SG_REL_ Bremse_ESP_EPB_EBC460Vi SG_ 901 CHA_Ziel_FahrPr_ESP 5000;
BA_REL_ "GenSigTimeoutTime" BU_SG_REL_ Bremse_ESP_EPB_EBC460Vi SG_ 901 CHA_Fahrer_Umschaltung 5000;
BA_REL_ "GenSigTimeoutTime" BU_SG_REL_ Bremse_ESP_EPB_EBC460Vi SG_ 1000 CHA_Fahrer_Umschaltung 5000;
BA_REL_ "GenSigTimeoutTime" BU_SG_REL_ Bremse_ESP_EPB_EBC460Vi SG_ 1000 CHA_Ziel_FahrPr_HDC 5000;
BA_REL_ "GenSigTimeoutTime" BU_SG_REL_ Bremse_ESP_EPB_MK100 SG_ 302 ACC_07_CRC 500;
BA_REL_ "GenSigTimeoutTime" BU_SG_REL_ Bremse_ESP_EPB_MK100 SG_ 302 ACC_07_BZ 500;
BA_REL_ "GenSigTimeoutTime" BU_SG_REL_ Bremse_ESP_EPB_MK100 SG_ 302 ACC_Anhalteweg 500;
BA_REL_ "GenSigTimeoutTime" BU_SG_REL_ Bremse_ESP_EPB_MK100 SG_ 302 ACC_Anhalten 500;
BA_REL_ "GenSigTimeoutTime" BU_SG_REL_ Bremse_ESP_EPB_MK100 SG_ 302 ACC_Anfahren 500;
BA_REL_ "GenSigTimeoutTime" BU_SG_REL_ Bremse_ESP_EPB_MK100 SG_ 279 ACC_10_CRC 500;
BA_REL_ "GenSigTimeoutTime" BU_SG_REL_ Bremse_ESP_EPB_MK100 SG_ 279 ACC_10_BZ 500;
BA_REL_ "GenSigTimeoutTime" BU_SG_REL_ Bremse_ESP_EPB_MK100 SG_ 279 AWV1_Anf_Prefill 500;
BA_REL_ "GenSigTimeoutTime" BU_SG_REL_ Bremse_ESP_EPB_MK100 SG_ 279 ANB_CM_Info 500;
BA_REL_ "GenSigTimeoutTime" BU_SG_REL_ Bremse_ESP_EPB_MK100 SG_ 279 AWV2_Freigabe 500;
BA_REL_ "GenSigTimeoutTime" BU_SG_REL_ Bremse_ESP_EPB_MK100 SG_ 279 AWV1_HBA_Param 500;
BA_REL_ "GenSigTimeoutTime" BU_SG_REL_ Bremse_ESP_EPB_MK100 SG_ 279 AWV2_Ruckprofil 500;
BA_REL_ "GenSigTimeoutTime" BU_SG_REL_ Bremse_ESP_EPB_MK100 SG_ 279 ANB_CM_Anforderung 500;
BA_REL_ "GenSigTimeoutTime" BU_SG_REL_ Bremse_ESP_EPB_MK100 SG_ 279 ANB_Info_Teilbremsung 500;
BA_REL_ "GenSigTimeoutTime" BU_SG_REL_ Bremse_ESP_EPB_MK100 SG_ 279 ANB_Teilbremsung_Freigabe 500;
BA_REL_ "GenSigTimeoutTime" BU_SG_REL_ Bremse_ESP_EPB_MK100 SG_ 279 ANB_Zielbrems_Teilbrems_Verz_Anf 500;
BA_REL_ "GenSigTimeoutTime" BU_SG_REL_ Bremse_ESP_EPB_MK100 SG_ 279 ANB_Zielbremsung_Freigabe 500;
BA_REL_ "GenSigTimeoutTime" BU_SG_REL_ Bremse_ESP_EPB_MK100 SG_ 279 AWV_Vorstufe 500;
BA_REL_ "GenSigTimeoutTime" BU_SG_REL_ Bremse_ESP_EPB_MK100 SG_ 279 AWV_Halten 500;
BA_REL_ "GenSigTimeoutTime" BU_SG_REL_ Bremse_ESP_EPB_MK100 SG_ 279 AWV_CityANB_Auspraegung 500;
BA_REL_ "GenSigTimeoutTime" BU_SG_REL_ Bremse_ESP_EPB_MK100 SG_ 279 AWV1_ECD_Anlauf 500;
BA_REL_ "GenSigTimeoutTime" BU_SG_REL_ Bremse_ESP_EPB_MK100 SG_ 64 Airbag_01_CRC 500;
BA_REL_ "GenSigTimeoutTime" BU_SG_REL_ Bremse_ESP_EPB_MK100 SG_ 64 Airbag_01_BZ 500;
BA_REL_ "GenSigTimeoutTime" BU_SG_REL_ Bremse_ESP_EPB_MK100 SG_ 64 AB_Front_Crash 500;
BA_REL_ "GenSigTimeoutTime" BU_SG_REL_ Bremse_ESP_EPB_MK100 SG_ 64 AB_Heck_Crash 500;
BA_REL_ "GenSigTimeoutTime" BU_SG_REL_ Bremse_ESP_EPB_MK100 SG_ 64 AB_SF_Crash 500;
BA_REL_ "GenSigTimeoutTime" BU_SG_REL_ Bremse_ESP_EPB_MK100 SG_ 64 AB_SB_Crash 500;
BA_REL_ "GenSigTimeoutTime" BU_SG_REL_ Bremse_ESP_EPB_MK100 SG_ 64 AB_Rollover_Crash 500;
BA_REL_ "GenSigTimeoutTime" BU_SG_REL_ Bremse_ESP_EPB_MK100 SG_ 64 AB_Crash_Int 500;
BA_REL_ "GenSigTimeoutTime" BU_SG_REL_ Bremse_ESP_EPB_MK100 SG_ 64 AB_MKB_gueltig 500;
BA_REL_ "GenSigTimeoutTime" BU_SG_REL_ Bremse_ESP_EPB_MK100 SG_ 64 AB_MKB_Anforderung 500;
BA_REL_ "GenSigTimeoutTime" BU_SG_REL_ Bremse_ESP_EPB_MK100 SG_ 64 SC_Masterzeit_Offset 500;
BA_REL_ "GenSigTimeoutTime" BU_SG_REL_ Bremse_ESP_EPB_MK100 SG_ 64 SC_Masterzeit 500;
BA_REL_ "GenSigTimeoutTime" BU_SG_REL_ Bremse_ESP_EPB_MK100 SG_ 1312 AB_Gurtschloss_FA 2000;
BA_REL_ "GenSigTimeoutTime" BU_SG_REL_ Bremse_ESP_EPB_MK100 SG_ 65 Airbag_03_CRC 5000;
BA_REL_ "GenSigTimeoutTime" BU_SG_REL_ Bremse_ESP_EPB_MK100 SG_ 65 Airbag_03_BZ 5000;
BA_REL_ "GenSigTimeoutTime" BU_SG_REL_ Bremse_ESP_EPB_MK100 SG_ 65 AB_MKB_Safing 5000;
BA_REL_ "GenSigTimeoutTime" BU_SG_REL_ Bremse_ESP_EPB_MK100 SG_ 280 Allrad_03_BZ 1000;
BA_REL_ "GenSigTimeoutTime" BU_SG_REL_ Bremse_ESP_EPB_MK100 SG_ 280 ALR_Sta_Laengssperre 1000;
BA_REL_ "GenSigTimeoutTime" BU_SG_REL_ Bremse_ESP_EPB_MK100 SG_ 280 ALR_Ist_Proz 1000;
BA_REL_ "GenSigTimeoutTime" BU_SG_REL_ Bremse_ESP_EPB_MK100 SG_ 2536711680 BAP_Brake_ASG_01_Header 800;
BA_REL_ "GenSigTimeoutTime" BU_SG_REL_ Bremse_ESP_EPB_MK100 SG_ 2536703744 BAP_RDK_ASG_01_Header 800;
BA_REL_ "GenSigTimeoutTime" BU_SG_REL_ Bremse_ESP_EPB_MK100 SG_ 2536703745 BAP_RDK_ASG_02_Header 800;
BA_REL_ "GenSigTimeoutTime" BU_SG_REL_ Bremse_ESP_EPB_MK100 SG_ 869 BEM_P_Generator 500;
BA_REL_ "GenSigTimeoutTime" BU_SG_REL_ Bremse_ESP_EPB_MK100 SG_ 870 BM_Warnblinken 5000;
BA_REL_ "GenSigTimeoutTime" BU_SG_REL_ Bremse_ESP_EPB_MK100 SG_ 901 CHA_Ziel_FahrPr_ESP 5000;
BA_REL_ "GenSigTimeoutTime" BU_SG_REL_ Bremse_ESP_EPB_MK100 SG_ 901 CHA_Fahrer_Umschaltung 5000;
BA_REL_ "GenSigTimeoutTime" BU_SG_REL_ Bremse_ESP_EPB_MK100 SG_ 1000 CHA_Fahrer_Umschaltung 5000;
BA_REL_ "GenSigTimeoutTime" BU_SG_REL_ Bremse_ESP_EPB_MK100 SG_ 1000 CHA_Ziel_FahrPr_HDC 5000;
BA_REL_ "GenSigTimeoutTime" BU_SG_REL_ Bremse_ESP_EPB_MK100 SG_ 1022 CHA_Ziel_FahrPr_HHC 5000;
BA_REL_ "GenSigTimeoutTime" BU_SG_REL_ Bremse_ESP_EPB_MK100 SG_ 1022 CHA_Ziel_FahrPr_EDS 5000;
BA_REL_ "GenSigTimeoutTime" BU_SG_REL_ Bremse_ESP_MK100 SG_ 302 ACC_07_CRC 500;
BA_REL_ "GenSigTimeoutTime" BU_SG_REL_ Bremse_ESP_MK100 SG_ 302 ACC_07_BZ 500;
BA_REL_ "GenSigTimeoutTime" BU_SG_REL_ Bremse_ESP_MK100 SG_ 302 ACC_Anhalteweg 500;
BA_REL_ "GenSigTimeoutTime" BU_SG_REL_ Bremse_ESP_MK100 SG_ 302 ACC_Anhalten 500;
BA_REL_ "GenSigTimeoutTime" BU_SG_REL_ Bremse_ESP_MK100 SG_ 302 ACC_Anfahren 500;
BA_REL_ "GenSigTimeoutTime" BU_SG_REL_ Bremse_ESP_MK100 SG_ 279 ACC_10_CRC 500;
BA_REL_ "GenSigTimeoutTime" BU_SG_REL_ Bremse_ESP_MK100 SG_ 279 ACC_10_BZ 500;
BA_REL_ "GenSigTimeoutTime" BU_SG_REL_ Bremse_ESP_MK100 SG_ 279 AWV1_Anf_Prefill 500;
BA_REL_ "GenSigTimeoutTime" BU_SG_REL_ Bremse_ESP_MK100 SG_ 279 ANB_CM_Info 500;
BA_REL_ "GenSigTimeoutTime" BU_SG_REL_ Bremse_ESP_MK100 SG_ 279 AWV2_Freigabe 500;
BA_REL_ "GenSigTimeoutTime" BU_SG_REL_ Bremse_ESP_MK100 SG_ 279 AWV1_HBA_Param 500;
BA_REL_ "GenSigTimeoutTime" BU_SG_REL_ Bremse_ESP_MK100 SG_ 279 AWV2_Ruckprofil 500;
BA_REL_ "GenSigTimeoutTime" BU_SG_REL_ Bremse_ESP_MK100 SG_ 279 ANB_CM_Anforderung 500;
BA_REL_ "GenSigTimeoutTime" BU_SG_REL_ Bremse_ESP_MK100 SG_ 279 ANB_Info_Teilbremsung 500;
BA_REL_ "GenSigTimeoutTime" BU_SG_REL_ Bremse_ESP_MK100 SG_ 279 ANB_Teilbremsung_Freigabe 500;
BA_REL_ "GenSigTimeoutTime" BU_SG_REL_ Bremse_ESP_MK100 SG_ 279 ANB_Zielbrems_Teilbrems_Verz_Anf 500;
BA_REL_ "GenSigTimeoutTime" BU_SG_REL_ Bremse_ESP_MK100 SG_ 279 ANB_Zielbremsung_Freigabe 500;
BA_REL_ "GenSigTimeoutTime" BU_SG_REL_ Bremse_ESP_MK100 SG_ 279 AWV_Vorstufe 500;
BA_REL_ "GenSigTimeoutTime" BU_SG_REL_ Bremse_ESP_MK100 SG_ 279 AWV_Halten 500;
BA_REL_ "GenSigTimeoutTime" BU_SG_REL_ Bremse_ESP_MK100 SG_ 279 AWV_CityANB_Auspraegung 500;
BA_REL_ "GenSigTimeoutTime" BU_SG_REL_ Bremse_ESP_MK100 SG_ 279 AWV1_ECD_Anlauf 500;
BA_REL_ "GenSigTimeoutTime" BU_SG_REL_ Bremse_ESP_MK100 SG_ 64 Airbag_01_CRC 500;
BA_REL_ "GenSigTimeoutTime" BU_SG_REL_ Bremse_ESP_MK100 SG_ 64 Airbag_01_BZ 500;
BA_REL_ "GenSigTimeoutTime" BU_SG_REL_ Bremse_ESP_MK100 SG_ 64 AB_Rollover_Crash 500;
BA_REL_ "GenSigTimeoutTime" BU_SG_REL_ Bremse_ESP_MK100 SG_ 64 AB_Crash_Int 500;
BA_REL_ "GenSigTimeoutTime" BU_SG_REL_ Bremse_ESP_MK100 SG_ 64 AB_MKB_gueltig 500;
BA_REL_ "GenSigTimeoutTime" BU_SG_REL_ Bremse_ESP_MK100 SG_ 64 AB_MKB_Anforderung 500;
BA_REL_ "GenSigTimeoutTime" BU_SG_REL_ Bremse_ESP_MK100 SG_ 64 SC_Masterzeit_Offset 500;
BA_REL_ "GenSigTimeoutTime" BU_SG_REL_ Bremse_ESP_MK100 SG_ 64 SC_Masterzeit 500;
BA_REL_ "GenSigTimeoutTime" BU_SG_REL_ Bremse_ESP_MK100 SG_ 1312 AB_Gurtschloss_FA 2000;
BA_REL_ "GenSigTimeoutTime" BU_SG_REL_ Bremse_ESP_MK100 SG_ 65 Airbag_03_CRC 5000;
BA_REL_ "GenSigTimeoutTime" BU_SG_REL_ Bremse_ESP_MK100 SG_ 65 Airbag_03_BZ 5000;
BA_REL_ "GenSigTimeoutTime" BU_SG_REL_ Bremse_ESP_MK100 SG_ 65 AB_MKB_Safing 5000;
BA_REL_ "GenSigTimeoutTime" BU_SG_REL_ Bremse_ESP_MK100 SG_ 280 Allrad_03_BZ 1000;
BA_REL_ "GenSigTimeoutTime" BU_SG_REL_ Bremse_ESP_MK100 SG_ 280 ALR_Sta_Laengssperre 1000;
BA_REL_ "GenSigTimeoutTime" BU_SG_REL_ Bremse_ESP_MK100 SG_ 280 ALR_Ist_Proz 1000;
BA_REL_ "GenSigTimeoutTime" BU_SG_REL_ Bremse_ESP_MK100 SG_ 2536711680 BAP_Brake_ASG_01_Header 800;
BA_REL_ "GenSigTimeoutTime" BU_SG_REL_ Bremse_ESP_MK100 SG_ 2536703744 BAP_RDK_ASG_01_Header 800;
BA_REL_ "GenSigTimeoutTime" BU_SG_REL_ Bremse_ESP_MK100 SG_ 2536703745 BAP_RDK_ASG_02_Header 800;
BA_REL_ "GenSigTimeoutTime" BU_SG_REL_ Bremse_ESP_MK100 SG_ 870 BM_Warnblinken 5000;
BA_REL_ "GenSigTimeoutTime" BU_SG_REL_ Bremse_ESP_MK100 SG_ 901 CHA_Ziel_FahrPr_ESP 5000;
BA_REL_ "GenSigTimeoutTime" BU_SG_REL_ Bremse_ESP_MK100 SG_ 901 CHA_Fahrer_Umschaltung 5000;
BA_REL_ "GenSigTimeoutTime" BU_SG_REL_ Bremse_ESP_MK100 SG_ 1000 CHA_Fahrer_Umschaltung 5000;
BA_REL_ "GenSigTimeoutTime" BU_SG_REL_ Bremse_ESP_MK100 SG_ 1000 CHA_Ziel_FahrPr_HDC 5000;
BA_REL_ "GenSigTimeoutTime" BU_SG_REL_ Bremse_ESP_MK100 SG_ 1022 CHA_Ziel_FahrPr_HHC 5000;
BA_REL_ "GenSigTimeoutTime" BU_SG_REL_ Bremse_ESP_MK100 SG_ 1022 CHA_Ziel_FahrPr_EDS 5000;
BA_REL_ "GenSigTimeoutTime" BU_SG_REL_ Daempfer SG_ 302 ACC_Sollbeschleunigung_02 500;
BA_REL_ "GenSigTimeoutTime" BU_SG_REL_ Daempfer SG_ 279 ANB_Teilbremsung_Freigabe 500;
BA_REL_ "GenSigTimeoutTime" BU_SG_REL_ Daempfer SG_ 279 ANB_Zielbrems_Teilbrems_Verz_Anf 500;
BA_REL_ "GenSigTimeoutTime" BU_SG_REL_ Daempfer SG_ 279 ANB_Zielbremsung_Freigabe 500;
BA_REL_ "GenSigTimeoutTime" BU_SG_REL_ Daempfer SG_ 901 CHA_Fahrer_Umschaltung 5000;
BA_REL_ "GenSigTimeoutTime" BU_SG_REL_ Daempfer SG_ 901 CHA_Ziel_FahrPr_DR 5000;
BA_REL_ "GenSigTimeoutTime" BU_SG_REL_ Gateway_MQB SG_ 280 ALR_Charisma_FahrPr 1000;
BA_REL_ "GenSigTimeoutTime" BU_SG_REL_ Gateway_MQB SG_ 280 ALR_Charisma_Status 1000;
BA_REL_ "GenSigTimeoutTime" BU_SG_REL_ Gateway_MQB SG_ 1365 AV_Charisma_FahrPr 5000;
BA_REL_ "GenSigTimeoutTime" BU_SG_REL_ Gateway_MQB SG_ 1365 AV_Charisma_Status 5000;
BA_REL_ "GenSigTimeoutTime" BU_SG_REL_ Gateway_MQB SG_ 918 DR_Charisma_FahrPr 1000;
BA_REL_ "GenSigTimeoutTime" BU_SG_REL_ Gateway_MQB SG_ 918 DR_Charisma_Status 1000;
BA_REL_ "GenSigTimeoutTime" BU_SG_REL_ Lenkhilfe_EPS SG_ 869 BEM_Batt_Ab 500;
BA_REL_ "GenSigTimeoutTime" BU_SG_REL_ Lenkhilfe_EPS SG_ 901 CHA_Fahrer_Umschaltung 5000;
BA_REL_ "GenSigTimeoutTime" BU_SG_REL_ Lenkhilfe_EPS SG_ 901 CHA_Ziel_FahrPr_EPS 5000;
BA_REL_ "GenSigTimeoutTime" BU_SG_REL_ PDC SG_ 64 AB_Gurtwarn_VF 500;
BA_REL_ "GenSigTimeoutTime" BU_SG_REL_ PDC SG_ 64 AB_Gurtwarn_VB 500;
BA_REL_ "GenSigTimeoutTime" BU_SG_REL_ PDC SG_ 1312 AB_Belegung_VB 2000;
BA_REL_ "GenSigTimeoutTime" BU_SG_REL_ PDC SG_ 1312 AB_Gurtschloss_FA 2000;
BA_REL_ "GenSigTimeoutTime" BU_SG_REL_ PDC SG_ 1312 AB_Gurtschloss_BF 2000;
BA_REL_ "GenSigTimeoutTime" BU_SG_REL_ PDC SG_ 1312 AB_Gurtschloss_Reihe2_FA 2000;
BA_REL_ "GenSigTimeoutTime" BU_SG_REL_ PDC SG_ 1312 AB_Gurtschloss_Reihe2_MI 2000;
BA_REL_ "GenSigTimeoutTime" BU_SG_REL_ PDC SG_ 1312 AB_Gurtschloss_Reihe2_BF 2000;
BA_REL_ "GenSigTimeoutTime" BU_SG_REL_ PDC SG_ 1312 AB_Gurtschloss_Reihe3_FA 2000;
BA_REL_ "GenSigTimeoutTime" BU_SG_REL_ PDC SG_ 1312 AB_Gurtschloss_Reihe3_MI 2000;
BA_REL_ "GenSigTimeoutTime" BU_SG_REL_ PDC SG_ 1312 AB_Gurtschloss_Reihe3_BF 2000;
BA_REL_ "GenSigTimeoutTime" BU_SG_REL_ PDC SG_ 1365 AV_HEK_Status_Anz_Punkte 5000;
BA_REL_ "GenSigTimeoutTime" BU_SG_REL_ PDC SG_ 1365 AV_HEK_Status_Zaehler 5000;
BA_REL_ "GenSigTimeoutTime" BU_SG_REL_ PDC SG_ 1365 AV_HEK_Status_Kamera_H 5000;
BA_REL_ "GenSigTimeoutTime" BU_SG_REL_ PDC SG_ 1365 AV_HEK_Status_Kamera_V 5000;
BA_REL_ "GenSigTimeoutTime" BU_SG_REL_ PDC SG_ 1365 AV_HEK_Status_Kamera_L 5000;
BA_REL_ "GenSigTimeoutTime" BU_SG_REL_ PDC SG_ 1365 AV_HEK_Status_Kamera_R 5000;
BA_REL_ "GenSigTimeoutTime" BU_SG_REL_ PDC SG_ 1365 AV_HEK_Status_aktiv 5000;
BA_REL_ "GenSigTimeoutTime" BU_SG_REL_ PDC SG_ 507 AV_HEK_Daten_Block 500;
BA_REL_ "GenSigTimeoutTime" BU_SG_REL_ PDC SG_ 507 AV_HEK_Daten_Zaehler 500;
BA_REL_ "GenSigTimeoutTime" BU_SG_REL_ PDC SG_ 507 AV_HEK_Daten_P1_y 500;
BA_REL_ "GenSigTimeoutTime" BU_SG_REL_ PDC SG_ 507 AV_HEK_Daten_P1_x 500;
BA_REL_ "GenSigTimeoutTime" BU_SG_REL_ PDC SG_ 507 AV_HEK_Daten_P1_Nachfolger 500;
BA_REL_ "GenSigTimeoutTime" BU_SG_REL_ PDC SG_ 507 AV_HEK_Daten_P1_Trend 500;
BA_REL_ "GenSigTimeoutTime" BU_SG_REL_ PDC SG_ 507 AV_HEK_Daten_P2_Nachfolger 500;
BA_REL_ "GenSigTimeoutTime" BU_SG_REL_ PDC SG_ 507 AV_HEK_Daten_P2_Trend 500;
BA_REL_ "GenSigTimeoutTime" BU_SG_REL_ PDC SG_ 507 AV_HEK_Daten_P2_x 500;
BA_REL_ "GenSigTimeoutTime" BU_SG_REL_ PDC SG_ 507 AV_HEK_Daten_P3_x 500;
BA_REL_ "GenSigTimeoutTime" BU_SG_REL_ PDC SG_ 507 AV_HEK_Daten_P2_y 500;
BA_REL_ "GenSigTimeoutTime" BU_SG_REL_ PDC SG_ 507 AV_HEK_Daten_P3_y 500;
BA_REL_ "GenSigTimeoutTime" BU_SG_REL_ PDC SG_ 507 AV_HEK_Daten_P3_Trend 500;
BA_REL_ "GenSigTimeoutTime" BU_SG_REL_ PDC SG_ 507 AV_HEK_Daten_P3_Nachfolger 500;
BA_REL_ "GenSigTimeoutTime" BU_SG_REL_ PDC SG_ 2536704512 BAP_OPS_ASG_01_Header 800;
BA_REL_ "GenSigTimeoutTime" BU_SG_REL_ PDC SG_ 2536704513 BAP_OPS_ASG_02_Header 800;
BA_REL_ "GenSigTimeoutTime" BU_SG_REL_ PDC SG_ 1000 CHA_Ziel_FahrPr_AV 5000;
BA_REL_ "GenSigTimeoutTime" BU_SG_REL_ PDC SG_ 1022 CHA_Ziel_FahrPr_PDC 5000;
BA_REL_ "GenSigTimeoutTime" BU_SG_REL_ PDC_PLA SG_ 64 AB_Gurtwarn_VF 500;
BA_REL_ "GenSigTimeoutTime" BU_SG_REL_ PDC_PLA SG_ 64 AB_Gurtwarn_VB 500;
BA_REL_ "GenSigTimeoutTime" BU_SG_REL_ PDC_PLA SG_ 64 SC_Masterzeit_Offset 500;
BA_REL_ "GenSigTimeoutTime" BU_SG_REL_ PDC_PLA SG_ 64 SC_Masterzeit 500;
BA_REL_ "GenSigTimeoutTime" BU_SG_REL_ PDC_PLA SG_ 1312 AB_Belegung_VB 2000;
BA_REL_ "GenSigTimeoutTime" BU_SG_REL_ PDC_PLA SG_ 1312 AB_Gurtschloss_FA 2000;
BA_REL_ "GenSigTimeoutTime" BU_SG_REL_ PDC_PLA SG_ 1312 AB_Gurtschloss_BF 2000;
BA_REL_ "GenSigTimeoutTime" BU_SG_REL_ PDC_PLA SG_ 1365 AV_HEK_Status_Anz_Punkte 5000;
BA_REL_ "GenSigTimeoutTime" BU_SG_REL_ PDC_PLA SG_ 1365 AV_HEK_Status_Zaehler 5000;
BA_REL_ "GenSigTimeoutTime" BU_SG_REL_ PDC_PLA SG_ 1365 AV_HEK_Status_Kamera_H 5000;
BA_REL_ "GenSigTimeoutTime" BU_SG_REL_ PDC_PLA SG_ 1365 AV_HEK_Status_Kamera_V 5000;
BA_REL_ "GenSigTimeoutTime" BU_SG_REL_ PDC_PLA SG_ 1365 AV_HEK_Status_Kamera_L 5000;
BA_REL_ "GenSigTimeoutTime" BU_SG_REL_ PDC_PLA SG_ 1365 AV_HEK_Status_Kamera_R 5000;
BA_REL_ "GenSigTimeoutTime" BU_SG_REL_ PDC_PLA SG_ 1365 AV_HEK_Status_aktiv 5000;
BA_REL_ "GenSigTimeoutTime" BU_SG_REL_ PDC_PLA SG_ 507 AV_HEK_Daten_Block 500;
BA_REL_ "GenSigTimeoutTime" BU_SG_REL_ PDC_PLA SG_ 507 AV_HEK_Daten_Zaehler 500;
BA_REL_ "GenSigTimeoutTime" BU_SG_REL_ PDC_PLA SG_ 507 AV_HEK_Daten_P1_y 500;
BA_REL_ "GenSigTimeoutTime" BU_SG_REL_ PDC_PLA SG_ 507 AV_HEK_Daten_P1_x 500;
BA_REL_ "GenSigTimeoutTime" BU_SG_REL_ PDC_PLA SG_ 507 AV_HEK_Daten_P1_Nachfolger 500;
BA_REL_ "GenSigTimeoutTime" BU_SG_REL_ PDC_PLA SG_ 507 AV_HEK_Daten_P1_Trend 500;
BA_REL_ "GenSigTimeoutTime" BU_SG_REL_ PDC_PLA SG_ 507 AV_HEK_Daten_P2_Nachfolger 500;
BA_REL_ "GenSigTimeoutTime" BU_SG_REL_ PDC_PLA SG_ 507 AV_HEK_Daten_P2_Trend 500;
BA_REL_ "GenSigTimeoutTime" BU_SG_REL_ PDC_PLA SG_ 507 AV_HEK_Daten_P2_x 500;
BA_REL_ "GenSigTimeoutTime" BU_SG_REL_ PDC_PLA SG_ 507 AV_HEK_Daten_P3_x 500;
BA_REL_ "GenSigTimeoutTime" BU_SG_REL_ PDC_PLA SG_ 507 AV_HEK_Daten_P2_y 500;
BA_REL_ "GenSigTimeoutTime" BU_SG_REL_ PDC_PLA SG_ 507 AV_HEK_Daten_P3_y 500;
BA_REL_ "GenSigTimeoutTime" BU_SG_REL_ PDC_PLA SG_ 507 AV_HEK_Daten_P3_Trend 500;
BA_REL_ "GenSigTimeoutTime" BU_SG_REL_ PDC_PLA SG_ 507 AV_HEK_Daten_P3_Nachfolger 500;
BA_REL_ "GenSigTimeoutTime" BU_SG_REL_ PDC_PLA SG_ 2536704512 BAP_OPS_ASG_01_Header 800;
BA_REL_ "GenSigTimeoutTime" BU_SG_REL_ PDC_PLA SG_ 2536704513 BAP_OPS_ASG_02_Header 800;
BA_REL_ "GenSigTimeoutTime" BU_SG_REL_ PDC_PLA SG_ 1000 CHA_Ziel_FahrPr_AV 5000;
BA_REL_ "GenSigTimeoutTime" BU_SG_REL_ PDC_PLA SG_ 1022 CHA_Ziel_FahrPr_PDC 5000;
VAL_ 302 ACC_Anhalteweg 2046 "Neutralwert" 2047 "Fehler" ;
VAL_ 302 ACC_Anhalten 0 "kein_Anhalten_gewuenscht" 1 "Anhalten_gewuenscht" ;
VAL_ 302 ACC_Freilauf_Anf 0 "keine Freilauf-Anforderung" 1 "Freilauf-Anforderung" ;
VAL_ 302 ACC_Freilauf_Info 0 "Freilauf_freigegeben" 1 "kein_Uebergang_in_Freilauf_zulaessig" 2 "Freilauf_nicht_freigegeben" 3 "Freilauf_Anforderung" ;
VAL_ 302 ACC_Anforderung_HMS 0 "keine_Anforderung" 1 "halten" 2 "parken" 3 "halten_Standby" 4 "anfahren" 5 "Loesen_ueber_Rampe" ;
VAL_ 302 ACC_Anfahren 0 "keine_Anforderung_Anfahren" 1 "Anforderung_Anfahren" ;
VAL_ 302 ACC_Folgebeschl 254 "Neutralwert" ;
VAL_ 302 ACC_Sollbeschleunigung_02 2046 "Neutralwert" 2047 "Fehler" ;
VAL_ 279 AWV1_Anf_Prefill 0 "Prefill_nicht_aktivieren" 1 "Prefill_aktivieren" ;
VAL_ 279 ANB_CM_Info 0 "Standard" 1 "Erweitert" ;
VAL_ 279 AWV2_Freigabe 0 "keine_Freigabe" 1 "Freigabe" ;
VAL_ 279 AWV1_HBA_Param 0 "Defaultparametersatz" 1 "Parametersatz_mit_leicht_erhoehter_Empfindlichkeit" 2 "Parametersatz_mit_erhoehter_Empfindlichkeit" 3 "Parametersatz_mit_hoechster_Empfindlichkeit" ;
VAL_ 279 AWV2_Priowarnung 0 "Anzeige_Verlassen_der_Fahrspur_wird_nicht_unterdrueckt" 1 "Anzeige_Verlassen_der_Fahrspur_wird_unterdrueckt" ;
VAL_ 279 ANB_CM_Anforderung 0 "keine_Anforderung" 1 "Anforderung_aktiv" ;
VAL_ 279 ANB_Info_Teilbremsung 0 "Auspraegung_Standard" 1 "Auspraegung_Erweitert" ;
VAL_ 279 ANB_Notfallblinken 0 "kein_ANB_Notfallblinken" 1 "Notfallblinken_ANB_angefordert" ;
VAL_ 279 ANB_Teilbremsung_Freigabe 0 "Teilbremsung_nicht_freigegeben" 1 "Teilbremsung_freigegeben" ;
VAL_ 279 ANB_Zielbremsung_Freigabe 0 "Zielbremsung_nicht_freigegeben" 1 "Zielbremsung_freigegeben" ;
VAL_ 279 AWV_Vorstufe 0 "keine_Notbremsung_erwartet" 1 "Notbremsung_in_Kuerze" ;
VAL_ 279 AWV_Halten 0 "keine_Anforderung" 1 "Anforderung_das_Fzg_im_Stillstand_zu_halten" ;
VAL_ 279 AWV_CityANB_Auspraegung 0 "autom_Bremsung_im_ges_vBereich" 1 "autom_Bremsung_im_def_vBereich" ;
VAL_ 279 PCF_Freigabe 0 "keine_Freigabe_PreCrashFront" 1 "Freigabe_PreCrashFront" ;
VAL_ 279 AWV1_ECD_Anlauf 0 "ECD_Anlauf_nicht_aktivieren" 1 "ECD_Anlauf_aktivieren" ;
VAL_ 279 PCF_Time_to_collision 255 "Objektstatus=0x0__oder_berechneter_TTC_Wert_groesser_als_Maximalwert" ;
VAL_ 64 AB_RGS_Anst 4 "aktiv_Niveau_1" 5 "aktiv_Niveau_2" 6 "aktiv_Niveau_3" 7 "aktiv_Niveau_4" 8 "deaktiviert" ;
VAL_ 64 AB_Front_Crash 0 "kein_Front_Crash" 1 "Front_Crash" ;
VAL_ 64 AB_Heck_Crash 0 "kein_Heck_Crash" 1 "Heck_Crash" ;
VAL_ 64 AB_SF_Crash 0 "kein_Seiten_Crash_Fahrer" 1 "Seiten_Crash_Fahrer" ;
VAL_ 64 AB_SB_Crash 0 "kein_Seiten_Crash_Beifahrer" 1 "Seiten_Crash_Beifahrer" ;
VAL_ 64 AB_Rollover_Crash 0 "kein_Rollover" 1 "Rollover" ;
VAL_ 64 AB_Crash_Int 0 "kein_Crash" 1 "Crash_Intensitaet_1" 2 "Crash_Intensitaet_2_(nur_Stellgliedtest_MLB_B8)" 3 "Crash_Intensitaet_2_(nur_D4_C7_Colorado_NF_PAG__Crash_im_MLB_B8)" 4 "Crash_Intensitaet_3_(alt_VW/AUDI__Stellgliedtest_MLB_B8)" 5 "Crash_Intensitaet_3_(alt_PAG)" 7 "Crash_Intensitaet_3" ;
VAL_ 64 AB_Lampe 0 "Aus" 1 "Ein" ;
VAL_ 64 AB_Deaktiviert 0 "aktiv" 1 "deaktiviert" ;
VAL_ 64 AB_VB_deaktiviert 0 "Beifahrerairbag_aktiv" 1 "Beifahrerairbag_deaktiviert" ;
VAL_ 64 AB_Systemfehler 0 "kein_Fehler" 1 "Airbag_Systemfehler" ;
VAL_ 64 AB_Diagnose 0 "nicht_in_Diagnose" 1 "in_Diagnose" ;
VAL_ 64 AB_Stellgliedtest 0 "nicht_im_Stellgliedtest" 1 "Airbag_im_Stellgliedtest" ;
VAL_ 64 AB_Erh_Auf_VB 0 "keine_Anzeige" 1 "Beifahrerairbag_deaktiviert" 2 "Beifahrerairbag_aktiviert" 3 "nicht_definiert" ;
VAL_ 64 AB_Gurtwarn_VF 0 "keine_Warnung" 1 "Gurtwarnung_ausloesen" ;
VAL_ 64 AB_Gurtwarn_VB 0 "keine_Warnung" 1 "Gurtwarnung_ausloesen" ;
VAL_ 64 AB_Anzeige_Fussg 0 "keine_FSG_Aktion_ausgeloest" 1 "Motorhaube_offen" 2 "Systemfehler" ;
VAL_ 64 AB_Texte_AKS 0 "keine_AKS_Ausloesung" 1 "AKS_ausgeloest" 2 "AKS_Systemfehler" ;
VAL_ 64 AB_PAO_Leuchte_Anf 0 "Leuchte_ausschalten" 1 "Leuchte_einschalten" ;
VAL_ 64 AB_MKB_gueltig 0 "Multikollisionsbremsung_nicht_freigeschaltet" 1 "Multikollisionsbremsung_freigeschaltet" ;
VAL_ 64 AB_MKB_Anforderung 0 "Multikollisionsbremsung_nicht_angefordert" 1 "Multikollisionsbremsung_angefordert" ;
VAL_ 64 AB_Versorgungsspannung 0 "plausibel" 1 "unplausibel" ;
VAL_ 64 AB_Deaktivierung_HV 0 "keine_Deaktivierung" 1 "Deaktivierung_1" 2 "Deaktivierung_2" 3 "Deaktivierung_3" 4 "Deaktivierung_4" 5 "Deaktivierung_5" 6 "Deaktivierung_6" 7 "Fehler" ;
VAL_ 64 AB_EDR_Trigger 0 "No_Event" 1 "Start_Event" 2 "NonDeployment_Event" 3 "Deployment_Event" ;
VAL_ 64 SC_Masterzeit 127 "Init" ;
VAL_ 1312 LoGeWa_Event_Kombiwarnung 0 "Init" 1 "Unfall" 2 "Traktionsverlust" 3 "Panne" 4 "Sichtbehinderung" 5 "Stauende" 6 "Aktiver_Eingriff_PreSense" 7 "Aktiver_Eingriff_ANB" 8 "Aktiver_Eingriff_Emergency_Brake" ;
VAL_ 1312 AB_Anforderung_eCall 0 "keine_Anforderung" 1 "Anforderung" ;
VAL_ 1312 AB_Anprall_Seite_Beifahrer 0 "kein_Anprall" 1 "Anprall_erkannt" ;
VAL_ 1312 AB_Anprall_Rollover 0 "kein_Anprall" 1 "Anprall_erkannt" ;
VAL_ 1312 AB_Anprall_FGS 0 "kein_Anprall" 1 "Anprall_erkannt" ;
VAL_ 1312 AB_Anprall_Front_Beifahrer 0 "kein_Anprall" 1 "Anprall_erkannt" ;
VAL_ 1312 AB_Anprall_Front_Fahrer 0 "kein_Anprall" 1 "Anprall_erkannt" ;
VAL_ 1312 AB_Anprall_Heck_Beifahrer 0 "kein_Anprall" 1 "Anprall_erkannt" ;
VAL_ 1312 AB_Anprall_Heck_Fahrer 0 "kein_Anprall" 1 "Anprall_erkannt" ;
VAL_ 1312 AB_Wickelklappung_Reihe2_MI 0 "nicht_verbaut" 1 "nicht_verfuegbar__Fehler_oder_Init" 2 "nicht_verriegelt" 3 "verriegelt" ;
VAL_ 1312 AB_Belegung_VB 0 "nicht_verfuegbar" 1 "Fehler" 2 "nicht_belegt" 3 "belegt" ;
VAL_ 1312 AB_Abschaltanf_SIH_BF 0 "Normalbetrieb" 1 "Abschaltung_angefordert" ;
VAL_ 1312 AB_Anprall_Seite_Fahrer 0 "kein_Anprall" 1 "Anprall_erkannt" ;
VAL_ 1312 SC_PAO_Schriftzug_Anf 0 "LED aus" 1 "LED an" 2 "LED blinken" 3 "reserviert" ;
VAL_ 1312 SC_PAO_ON_Anf 0 "LED aus" 1 "LED an" 2 "LED blinken" 3 "reserviert" ;
VAL_ 1312 SC_PAO_OFF_Anf 0 "LED aus" 1 "LED an" 2 "LED blinken" 3 "reserviert" ;
VAL_ 1312 AB_Crashschwere 0 "kein_Ereignis" 1 "Crashschwere_1" 2 "Crashschwere_2" 3 "Crashschwere_3" 4 "Crashschwere_4" 5 "Crashschwere_5" 6 "nicht_belegt" 7 "Fehler" ;
VAL_ 1312 AB_Anforderung_USM 0 "keine_Anforderung" 1 "Anforderung" ;
VAL_ 1312 AB_Gurtschloss_FA 0 "nicht_verbaut" 1 "nicht_verfügbar (Fehler oder Init)" 2 "nicht_gesteckt" 3 "gesteckt" ;
VAL_ 1312 AB_Gurtschloss_BF 0 "nicht_verbaut" 1 "nicht_verfügbar (Fehler oder Init)" 2 "nicht_gesteckt" 3 "gesteckt" ;
VAL_ 1312 AB_Gurtschloss_Reihe2_FA 0 "nicht_verbaut" 1 "nicht_verfügbar (Fehler oder Init)" 2 "nicht_gesteckt" 3 "gesteckt" ;
VAL_ 1312 AB_Gurtschloss_Reihe2_MI 0 "nicht_verbaut" 1 "nicht_verfügbar (Fehler oder Init)" 2 "nicht_gesteckt" 3 "gesteckt" ;
VAL_ 1312 AB_Gurtschloss_Reihe2_BF 0 "nicht_verbaut" 1 "nicht_verfügbar (Fehler oder Init)" 2 "nicht_gesteckt" 3 "gesteckt" ;
VAL_ 1312 AB_Gurtschloss_Reihe3_FA 0 "nicht_verbaut" 1 "nicht_verfügbar (Fehler oder Init)" 2 "nicht_gesteckt" 3 "gesteckt" ;
VAL_ 1312 AB_Gurtschloss_Reihe3_MI 0 "nicht_verbaut" 1 "nicht_verfügbar (Fehler oder Init)" 2 "nicht_gesteckt" 3 "gesteckt" ;
VAL_ 1312 AB_Gurtschloss_Reihe3_BF 0 "nicht_verbaut" 1 "nicht_verfügbar (Fehler oder Init)" 2 "nicht_gesteckt" 3 "gesteckt" ;
VAL_ 1312 AB_Sitzpos_Sens_FA 0 "nicht verfügbar" 1 "Fehler" 2 "Sitz nicht vorne" 3 "Sitz vorne" ;
VAL_ 1312 AB_Sitzpos_Sens_BF 0 "nicht verfügbar" 1 "Fehler" 2 "Sitz nicht vorne" 3 "Sitz vorne" ;
VAL_ 1312 AB_Wickelklappung_Reihe2_BF 0 "nicht_verbaut" 1 "nicht_verfuegbar__Fehler_oder_Init" 2 "nicht_verriegelt" 3 "verriegelt" ;
VAL_ 1312 AB_Wickelklappung_Reihe2_FA 0 "nicht_verbaut" 1 "nicht_verfuegbar__Fehler_oder_Init" 2 "nicht_verriegelt" 3 "verriegelt" ;
VAL_ 65 AB_MKB_Safing 0 "Multikollisionsbremsung_nicht_bestaetigt" 1 "Multikollisionsbremsung_bestaetigt" ;
VAL_ 280 ALR_Sta_Laengssperre 0 "Sperre_im_Regelmodus" 1 "Sperre_vom_Fahrer_aktiviert" 2 "Fehler_Sperre_offen" 3 "Fehler_Sperre_zu" ;
VAL_ 280 ALR_Sendestatus 0 "Allrad_sendet_mit_100ms" 1 "Allrad_sendet_mit_10ms" ;
VAL_ 280 ALR_Ist_Proz 253 "Fehler_und_Kupplung_geschlossen" 254 "Init" 255 "Fehler" ;
VAL_ 280 ALR_Charisma_FahrPr 0 "keine_Funktion" 1 "Programm_1" 2 "Programm_2" 3 "Programm_3" 4 "Programm_4" 5 "Programm_5" 6 "Programm_6" 7 "Programm_7" 8 "Programm_8" 9 "Programm_9" 10 "Programm_10" 11 "Programm_11" 12 "Programm_12" 13 "Programm_13" 14 "Programm_14" 15 "Programm_15" ;
VAL_ 280 ALR_Charisma_Status 0 "Init" 1 "verfuegbar" 2 "nicht_verfuegbar" 3 "asynchron_durch_Fahrerwunsch" ;
VAL_ 927 US_Fehler_VS 0 "kein_Fehler" 1 "Fehler" ;
VAL_ 927 US_Fehler_HS 0 "kein_Fehler" 1 "Fehler" ;
VAL_ 927 US_Verschmutzung_VS 0 "keine_Blindheit" 1 "Blindheit_erkannt" ;
VAL_ 927 US_Verschmutzung_HS 0 "keine_Blindheit" 1 "Blindheit_erkannt" ;
VAL_ 927 US_NichtVerfuegbarkeit_VS 0 "Abstandswert_verfuegbar" 1 "Abstandswert_nicht_verfuegbar" ;
VAL_ 927 US_NichtVerfuegbarkeit_HS 0 "Abstandswert_verfuegbar" 1 "Abstandswert_nicht_verfuegbar" ;
VAL_ 896 US_Sende_Modus 0 "keine_fuer_das_ACC_SG_relevanten_Abstandswerte_werden_gesendet" 1 "4K_ext_range__10_Signalwege_verfuegbar__4m" 2 "4K_norm_range__10_Signalwege_verfuegbar__2m" 3 "6K_ext_range__16_Signalwege_verfuegbar__4m" 4 "6K_norm_range__16_Signalwege_verfuegbar__2m" 5 "2K_ext_range__2_Signalwege_verfuegbar__4m" 6 "Modeumschaltung__ext_>_norm__oder__norm_>_ext" 7 "Blindheitspruefung" 8 "4K_ext_range__12_Signalwege_verfuegbar_4m" 9 "4K_norm_range__12_Signalwege_verfuegbar_2m" 10 "6K_ext_range__18_Signalwege_verfuegbar_4m" 11 "6K_norm_range__18_Signalwege_verfuegbar_2m" 15 "Fehler" ;
VAL_ 896 US_relevanter_Fehler 0 "kein_relevanter_Fehler" 1 "relevanter_Fehler" ;
VAL_ 896 US_relevante_Nichtverfuegbarkeit 0 "verfuegbar" 1 "nicht_verfuegbar" ;
VAL_ 896 US_Freisicht_nio 0 "Freisicht_iO" 1 "Freisicht_niO" ;
VAL_ 896 US_blindness_detected 0 "blindness_nicht_detektiert" 1 "blindness_detektiert" ;
VAL_ 896 US_Sende_Modus_hinten 0 "keine_fuer_das_ACC_SG_relevanten_Abstandswerte_werden_gesendet" 5 "2K_ext_range__2_Signalwege_verfuegbar__4m" 6 "Modeumschaltung__ext_>_norm__oder__norm_>_ext" 7 "Blindheitspruefung" 15 "Fehler" ;
VAL_ 896 APS_Master_Sendestatus 0 "Langsame_Zykluszeit_aktiv" 1 "Schnelle_Zykluszeit_aktiv" ;
VAL_ 896 US_Freie_Weglaenge_Front_Typ 0 "Maximaler_Messbereich" 1 "Hindernis_detektiert" ;
VAL_ 896 US_Freie_Weglaenge_Front 509 "freie_Weglaenge_groesser_5m" 510 "Init" 511 "Fehler" ;
VAL_ 348 ARA_Sensor_02_red_cyclic 0 "Langsame_Zykluszeit_aktiv" 1 "Schnelle_Zykluszeit_aktiv" ;
VAL_ 348 ARA_Sensor_Status 0 "Initialisierung" 1 "i.O." 2 "Gütemaß ungenügend" 3 "interne Korrektur des Absolutwinkels" 4 "keine auswertbaren Bilddaten" 5 "sonstiger Fehler" 6 "Kamera_ueberhitzt" ;
VAL_ 348 ARA_Sensor_Qualitaet_Grund 0 "Umweltbedingung" 1 "Verschmutzung der Kamera" ;
VAL_ 348 ARA_Sensor_Knickw_Rohwert 65534 "Init" 65535 "Fehler" ;
VAL_ 1365 AV_HEK_Status_Kamera_H 0 "betriebsbereit" 1 "passiv" 2 "verschmutzt" 7 "Fehler" ;
VAL_ 1365 AV_HEK_Status_Kamera_V 0 "betriebsbereit" 1 "passiv" 2 "verschmutzt" 7 "Fehler" ;
VAL_ 1365 AV_HEK_Status_Kamera_L 0 "betriebsbereit" 1 "passiv" 2 "verschmutzt" 7 "Fehler" ;
VAL_ 1365 AV_HEK_Status_Kamera_R 0 "betriebsbereit" 1 "passiv" 2 "verschmutzt" 7 "Fehler" ;
VAL_ 1365 AV_HEK_Status_aktiv 0 "inaktiv" 1 "aktiv" ;
VAL_ 1365 AV_Umfeldbeleuchtung_Anf 0 "nicht_angefordert" 1 "angefordert" ;
VAL_ 1365 AV_Charisma_FahrPr 0 "keine_Funktion" 1 "Programm_1" 2 "Programm_2" 3 "Programm_3" 4 "Programm_4" 5 "Programm_5" 6 "Programm_6" 7 "Programm_7" 8 "Programm_8" 9 "Programm_9" 10 "Programm_10" 11 "Programm_11" 12 "Programm_12" 13 "Programm_13" 14 "Programm_14" 15 "Programm_15" ;
VAL_ 1365 AV_Charisma_Status 0 "Init" 1 "verfuegbar" 2 "nicht_verfuegbar" 3 "asynchron_durch_Fahrerwunsch" ;
VAL_ 507 AV_HEK_Daten_Block 0 "inaktiv" ;
VAL_ 507 AV_HEK_Daten_P1_y 63 "ungueltig" ;
VAL_ 507 AV_HEK_Daten_P1_x 255 "ungueltig" ;
VAL_ 507 AV_HEK_Daten_P1_Nachfolger 0 "kein_Nachfolger" 1 "Nachfolger" ;
VAL_ 507 AV_HEK_Daten_P1_Trend 0 "Init" 1 "annaehernd" 2 "gleichbleibend_entfernend" 3 "gleichbleibend_annaehernd" 4 "entfernend" ;
VAL_ 507 AV_HEK_Daten_P2_Nachfolger 0 "kein_Nachfolger" 1 "Nachfolger" ;
VAL_ 507 AV_HEK_Daten_P2_Trend 0 "Init" 1 "annaehernd" 2 "gleichbleibend_entfernend" 3 "gleichbleibend_annaehernd" 4 "entfernend" ;
VAL_ 507 AV_HEK_Daten_P2_x 255 "ungueltig" ;
VAL_ 507 AV_HEK_Daten_P3_x 255 "ungueltig" ;
VAL_ 507 AV_HEK_Daten_P2_y 63 "ungueltig" ;
VAL_ 507 AV_HEK_Daten_P3_y 63 "ungueltig" ;
VAL_ 507 AV_HEK_Daten_P3_Trend 0 "Init" 1 "annaehrend" 2 "gleichbleibend_entfernend" 3 "gleichbleibend_annaehrend" 4 "entfernend" ;
VAL_ 507 AV_HEK_Daten_P3_Nachfolger 0 "kein_Nachfolger" 1 "Nachfolger" ;
VAL_ 869 BEM_UBDM 0 "Init" 255 "Fehler" ;
VAL_ 869 NVEM_Ladefreigabe 0 "kein_Freigabe" 1 "Freigabe_Stufe_1" 2 "Freigabe_Stufe_2" 3 "Uneingeschraenkte_Freigabe" ;
VAL_ 869 NVEM_FMAus_Info 0 "Motorlauf_langfristig_nicht_notwendig_FMAus_Freigabe" 1 "Motoranlauf_nicht_zwingend_notwendig_Stoppverbot_keine_Startanforderung" 2 "Motoranlauf_zwingend_notwendig_Startanforderung" 3 "Systemfehler" ;
VAL_ 869 NVEM_PTC_Sollstufe 0 "Aus" 1 "Stufe_1" 2 "Stufe_2" 3 "Stufe_3" ;
VAL_ 869 BEM_P_Generator 255 "Fehler" ;
VAL_ 869 BEM_n_LLA 0 "keine_Erhoehung" 1 "Stufe_1" 2 "Stufe_2" 3 "Stufe_3" ;
VAL_ 869 BEM_01_Abschaltstufen 0 "Stufe_0_keine_Einschraenkung" 1 "Stufe_1" 2 "Stufe_2" 3 "Stufe_3" 4 "Transportmodus" 7 "Ruhestrommessmodus" ;
VAL_ 869 BEM_Anf_KL 0 "keine Anforderung" 1 "Anforderung Kühlerlüfter Ansteuerung" ;
VAL_ 869 BEM_StartStopp_Info 0 "Motorlauf_nicht_notwendig_(Stoppfreigabe)" 1 "Motoranlauf_nicht_zwingend_notwendig_(Stoppverbot,keine_Startanforderung)" 2 "Motoranlauf_zwingend_notwendig_(Startanforderung)" 3 "Systemfehler" ;
VAL_ 869 BEM_EMLIN_ungueltig 0 "Signale_gueltig" 1 "Signale_ungueltig" ;
VAL_ 869 BEM_Batt_Ab 0 "verbunden" 1 "nicht_verbunden" ;
VAL_ 869 NVEM_FMAus_I_Verbrauch 30 "Init" 31 "Fehler" ;
VAL_ 869 NVEM_Freilauf_Info 0 "Freilauf_freigegeben" 1 "Uebergang_in_Freilauf_unzulaessig" 2 "Freilauf_nicht_freigegeben_Abbruch" 3 "Freilauf_Anforderung" ;
VAL_ 869 BEM_NV_NachladAnf 0 "keine_Anforderung" 1 "Anforderung_NV_Nachladung" 2 "Wunsch_NV_Nachladung" 3 "Fehler" ;
VAL_ 869 BEM_Segel_Info 0 "keine_Anforderung" 1 "Mindestdrehzahl_1" 2 "Mindestdrehzahl_2" 3 "Segelveto" ;
VAL_ 869 BEM_HYB_DC_uMinLV 254 "Init" 255 "Fehler" ;
VAL_ 870 BM_ZV_auf 0 "inaktiv" 1 "aktiv" ;
VAL_ 870 BM_ZV_zu 0 "inaktiv" 1 "aktiv" ;
VAL_ 870 BM_DWA_ein 0 "inaktiv" 1 "aktiv" ;
VAL_ 870 BM_DWA_Alarm 0 "inaktiv" 1 "aktiv" ;
VAL_ 870 BM_Crash 0 "inaktiv" 1 "aktiv" ;
VAL_ 870 BM_Panik 0 "inaktiv" 1 "aktiv" ;
VAL_ 870 BM_Not_Bremsung 0 "inaktiv" 1 "aktiv" ;
VAL_ 870 BM_GDO 0 "inaktiv" 1 "aktiv" ;
VAL_ 870 BM_Warnblinken 0 "inaktiv" 1 "aktiv" ;
VAL_ 870 BM_Taxi_Notalarm 0 "inaktiv" 1 "aktiv" ;
VAL_ 870 BM_Telematik 0 "inaktiv" 1 "aktiv" ;
VAL_ 870 BM_links 0 "inaktiv" 1 "aktiv" ;
VAL_ 870 BM_rechts 0 "inaktiv" 1 "aktiv" ;
VAL_ 870 Blinken_li_Fzg_Takt 0 "Blinker_links_ausgeschaltet" 1 "Blinker_links_eingeschaltet" ;
VAL_ 870 Blinken_re_Fzg_Takt 0 "Blinker_rechts_ausgeschaltet" 1 "Blinker_rechts_eingeschaltet" ;
VAL_ 870 Blinken_li_Kombi_Takt 0 "Blinkerkontrolllampe_links_ausgeschaltet" 1 "Blinkerkontrolllampe_links_eingeschaltet" ;
VAL_ 870 Blinken_re_Kombi_Takt 0 "Blinkerkontrolllampe_rechts_ausgeschaltet" 1 "Blinkerkontrolllampe_rechts_eingeschaltet" ;
VAL_ 870 BM_NBA_n_codiert_n_aktiv 0 "codiert_AND_kein_Fehler" 1 "nicht_codiert_OR_Fehler_erkannt" ;
VAL_ 870 BM_NBA_Status 0 "NBA_nicht_aktiv" 1 "BRL_Dunkelphase" 3 "BRL_Hellphase" ;
VAL_ 870 BM_WBT_Beleuchtung 0 "inaktiv" 1 "aktiv" ;
VAL_ 870 BM_HD_Oeffnung_angelernt 0 "keine_Quittierung" 1 "Quittierung" ;
VAL_ 870 BM_Autobahn 0 "inaktiv" 1 "aktiv" ;
VAL_ 870 BM_Rollenmodus_Blinken 0 "inaktiv" 1 "aktiv" ;
VAL_ 870 BM_Recas 0 "inaktiv" 1 "aktiv" ;
VAL_ 870 BM_Wischblinken 0 "inaktiv" 1 "aktiv" ;
VAL_ 870 BM_Telematik_Abbruchgrund 0 "Init" 1 "speed_out_of_range" 2 "defect" 3 "clamp_s_on" 4 "clamp_15_on" 5 "door_open" 6 "engine_hood_open" 7 "trunk_open" 8 "convertible_top_not_locked" 9 "horn_activated_by_user" 10 "Higher_Prioritiy_Function_active" 11 "Central_Lock_status_changed" 12 "Request_Dropped_by_Requester" 13 "Service_Duration_Expired" 14 "not_possible_due_to_coding" 15 "no_reason_or_unknown_timeout" ;
VAL_ 870 BM_PiloPa 0 "PiloPa_Blinkerquittierung_inaktiv" 1 "PiloPa_Blinkerquittierung_aktiv" ;
VAL_ 901 CHA_Ziel_FahrPr_AGA 0 "keine_Funktion" 1 "Programm_1" 2 "Programm_2" 3 "Programm_3" 4 "Programm_4" 5 "Programm_5" 6 "Programm_6" 7 "Programm_7" 8 "Programm_8" 9 "Programm_9" 10 "Programm_10" 11 "Programm_11" 12 "Programm_12" 13 "Programm_13" 14 "Programm_14" 15 "Programm_15" ;
VAL_ 901 CHA_Ziel_FahrPr_ESP 0 "keine_Funktion" 1 "Programm_1" 2 "Programm_2" 3 "Programm_3" 4 "Programm_4" 5 "Programm_5" 6 "Programm_6" 7 "Programm_7" 8 "Programm_8" 9 "Programm_9" 10 "Programm_10" 11 "Programm_11" 12 "Programm_12" 13 "Programm_13" 14 "Programm_14" 15 "Programm_15" ;
VAL_ 901 CHA_Ziel_FahrPr_Freilauf 0 "keine_Funktion" 1 "Programm_1" 2 "Programm_2" 3 "Programm_3" 4 "Programm_4" 5 "Programm_5" 6 "Programm_6" 7 "Programm_7" 8 "Programm_8" 9 "Programm_9" 10 "Programm_10" 11 "Programm_11" 12 "Programm_12" 13 "Programm_13" 14 "Programm_14" 15 "Programm_15" ;
VAL_ 901 CHA_Fahrer_Umschaltung 0 "keine_oder_automatische_Umschaltung" 1 "manuelle_Umschaltung" ;
VAL_ 901 CHA_Fahrer_Umschaltung_BMA 0 "keine_oder_autom_Umschaltung" 1 "manuelle_Umschaltung" ;
VAL_ 901 CHA_Ziel_FahrPr_MO 0 "keine_Funktion" 1 "Programm_1" 2 "Programm_2" 3 "Programm_3" 4 "Programm_4" 5 "Programm_5" 6 "Programm_6" 7 "Programm_7" 8 "Programm_8" 9 "Programm_9" 10 "Programm_10" 11 "Programm_11" 12 "Programm_12" 13 "Programm_13" 14 "Programm_14" 15 "Programm_15" ;
VAL_ 901 CHA_Ziel_FahrPr_GE 0 "keine_Funktion" 1 "Programm_1" 2 "Programm_2" 3 "Programm_3" 4 "Programm_4" 5 "Programm_5" 6 "Programm_6" 7 "Programm_7" 8 "Programm_8" 9 "Programm_9" 10 "Programm_10" 11 "Programm_11" 12 "Programm_12" 13 "Programm_13" 14 "Programm_14" 15 "Programm_15" ;
VAL_ 901 CHA_Ziel_FahrPr_ALR 0 "keine_Funktion" 1 "Programm_1" 2 "Programm_2" 3 "Programm_3" 4 "Programm_4" 5 "Programm_5" 6 "Programm_6" 7 "Programm_7" 8 "Programm_8" 9 "Programm_9" 10 "Programm_10" 11 "Programm_11" 12 "Programm_12" 13 "Programm_13" 14 "Programm_14" 15 "Programm_15" ;
VAL_ 901 CHA_Ziel_FahrPr_MO_BZS 0 "keine_Funktion" 1 "Programm_1" 2 "Programm_2" 3 "Programm_3" 4 "Programm_4" 5 "Programm_5" 6 "Programm_6" 7 "Programm_7" 8 "Programm_8" 9 "Programm_9" 10 "Programm_10" 11 "Programm_11" 12 "Programm_12" 13 "Programm_13" 14 "Programm_14" 15 "Programm_15" ;
VAL_ 901 CHA_Ziel_FahrPr_DR 0 "keine_Funktion" 1 "Programm_1" 2 "Programm_2" 3 "Programm_3" 4 "Programm_4" 5 "Programm_5" 6 "Programm_6" 7 "Programm_7" 8 "Programm_8" 9 "Programm_9" 10 "Programm_10" 11 "Programm_11" 12 "Programm_12" 13 "Programm_13" 14 "Programm_14" 15 "Programm_15" ;
VAL_ 901 CHA_Ziel_FahrPr_VAQ 0 "keine_Funktion" 1 "Programm_1" 2 "Programm_2" 3 "Programm_3" 4 "Programm_4" 5 "Programm_5" 6 "Programm_6" 7 "Programm_7" 8 "Programm_8" 9 "Programm_9" 10 "Programm_10" 11 "Programm_11" 12 "Programm_12" 13 "Programm_13" 14 "Programm_14" 15 "Programm_15" ;
VAL_ 901 CHA_Ziel_FahrPr_AFS 0 "keine_Funktion" 1 "Programm_1" 2 "Programm_2" 3 "Programm_3" 4 "Programm_4" 5 "Programm_5" 6 "Programm_6" 7 "Programm_7" 8 "Programm_8" 9 "Programm_9" 10 "Programm_10" 11 "Programm_11" 12 "Programm_12" 13 "Programm_13" 14 "Programm_14" 15 "Programm_15" ;
VAL_ 901 CHA_Ziel_FahrPr_RGS 0 "keine_Funktion" 1 "Programm_1" 2 "Programm_2" 3 "Programm_3" 4 "Programm_4" 5 "Programm_5" 6 "Programm_6" 7 "Programm_7" 8 "Programm_8" 9 "Programm_9" 10 "Programm_10" 11 "Programm_11" 12 "Programm_12" 13 "Programm_13" 14 "Programm_14" 15 "Programm_15" ;
VAL_ 901 CHA_Ziel_FahrPr_EPS 0 "keine_Funktion" 1 "Programm_1" 2 "Programm_2" 3 "Programm_3" 4 "Programm_4" 5 "Programm_5" 6 "Programm_6" 7 "Programm_7" 8 "Programm_8" 9 "Programm_9" 10 "Programm_10" 11 "Programm_11" 12 "Programm_12" 13 "Programm_13" 14 "Programm_14" 15 "Programm_15" ;
VAL_ 901 CHA_Ziel_FahrPr_ACC 0 "keine_Funktion" 1 "Programm_1" 2 "Programm_2" 3 "Programm_3" 4 "Programm_4" 5 "Programm_5" 6 "Programm_6" 7 "Programm_7" 8 "Programm_8" 9 "Programm_9" 10 "Programm_10" 11 "Programm_11" 12 "Programm_12" 13 "Programm_13" 14 "Programm_14" 15 "Programm_15" ;
VAL_ 901 CHA_Ziel_FahrPr_SAK 0 "keine_Funktion" 1 "Programm_1" 2 "Programm_2" 3 "Programm_3" 4 "Programm_4" 5 "Programm_5" 6 "Programm_6" 7 "Programm_7" 8 "Programm_8" 9 "Programm_9" 10 "Programm_10" 11 "Programm_11" 12 "Programm_12" 13 "Programm_13" 14 "Programm_14" 15 "Programm_15" ;
VAL_ 901 CHA_Ziel_FahrPr_MO_StSt 0 "keine_Funktion" 1 "Programm_1" 2 "Programm_2" 3 "Programm_3" 4 "Programm_4" 5 "Programm_5" 6 "Programm_6" 7 "Programm_7" 8 "Programm_8" 9 "Programm_9" 10 "Programm_10" 11 "Programm_11" 12 "Programm_12" 13 "Programm_13" 14 "Programm_14" 15 "Programm_15" ;
VAL_ 1000 CHA_Ziel_FahrPr_EBKV 0 "keine_Funktion" 1 "Programm_1" 2 "Programm_2" 3 "Programm_3" 4 "Programm_4" 5 "Programm_5" 6 "Programm_6" 7 "Programm_7" 8 "Programm_8" 9 "Programm_9" 10 "Programm_10" 11 "Programm_11" 12 "Programm_12" 13 "Programm_13" 14 "Programm_14" 15 "Programm_15" ;
VAL_ 1000 CHA_Ziel_FahrPr_IL 0 "keine_Funktion" 1 "Programm_1" 2 "Programm_2" 3 "Programm_3" 4 "Programm_4" 5 "Programm_5" 6 "Programm_6" 7 "Programm_7" 8 "Programm_8" 9 "Programm_9" 10 "Programm_10" 11 "Programm_11" 12 "Programm_12" 13 "Programm_13" 14 "Programm_14" 15 "Programm_15" ;
VAL_ 1000 CHA_Current_Mode 0 "keine_Funktion" 1 "Programm_1" 2 "Programm_2" 3 "Programm_3" 4 "Programm_4" 5 "Programm_5" 6 "Programm_6" 7 "Programm_7" 8 "Programm_8" 9 "Programm_9" 10 "Programm_10" 11 "Programm_11" 12 "Programm_12" 13 "Programm_13" 14 "Programm_14" 15 "Programm_15" ;
VAL_ 1000 CHA_Fahrer_Umschaltung 0 "keine_oder_automatische_Umschaltung" 1 "manuelle_Umschaltung" ;
VAL_ 1000 CHA_Ziel_FahrPr_QS 0 "keine_Funktion" 1 "Programm_1" 2 "Programm_2" 3 "Programm_3" 4 "Programm_4" 5 "Programm_5" 6 "Programm_6" 7 "Programm_7" 8 "Programm_8" 9 "Programm_9" 10 "Programm_10" 11 "Programm_11" 12 "Programm_12" 13 "Programm_13" 14 "Programm_14" 15 "Programm_15" ;
VAL_ 1000 CHA_Ziel_FahrPr_SCU 0 "keine_Funktion" 1 "Programm_1" 2 "Programm_2" 3 "Programm_3" 4 "Programm_4" 5 "Programm_5" 6 "Programm_6" 7 "Programm_7" 8 "Programm_8" 9 "Programm_9" 10 "Programm_10" 11 "Programm_11" 12 "Programm_12" 13 "Programm_13" 14 "Programm_14" 15 "Programm_15" ;
VAL_ 1000 CHA_Ziel_FahrPr_HAL 0 "keine_Funktion" 1 "Programm_1" 2 "Programm_2" 3 "Programm_3" 4 "Programm_4" 5 "Programm_5" 6 "Programm_6" 7 "Programm_7" 8 "Programm_8" 9 "Programm_9" 10 "Programm_10" 11 "Programm_11" 12 "Programm_12" 13 "Programm_13" 14 "Programm_14" 15 "Programm_15" ;
VAL_ 1000 CHA_Ziel_FahrPr_NR 0 "keine_Funktion" 1 "Programm_1" 2 "Programm_2" 3 "Programm_3" 4 "Programm_4" 5 "Programm_5" 6 "Programm_6" 7 "Programm_7" 8 "Programm_8" 9 "Programm_9" 10 "Programm_10" 11 "Programm_11" 12 "Programm_12" 13 "Programm_13" 14 "Programm_14" 15 "Programm_15" ;
VAL_ 1000 CHA_Ziel_FahrPr_AV 0 "keine_Funktion" 1 "Programm_1" 2 "Programm_2" 3 "Programm_3" 4 "Programm_4" 5 "Programm_5" 6 "Programm_6" 7 "Programm_7" 8 "Programm_8" 9 "Programm_9" 10 "Programm_10" 11 "Programm_11" 12 "Programm_12" 13 "Programm_13" 14 "Programm_14" 15 "Programm_15" ;
VAL_ 1000 CHA_Ziel_FahrPr_MXB 0 "keine_Funktion" 1 "Programm_1" 2 "Programm_2" 3 "Programm_3" 4 "Programm_4" 5 "Programm_5" 6 "Programm_6" 7 "Programm_7" 8 "Programm_8" 9 "Programm_9" 10 "Programm_10" 11 "Programm_11" 12 "Programm_12" 13 "Programm_13" 14 "Programm_14" 15 "Programm_15" ;
VAL_ 1000 CHA_Ziel_FahrPr_AFR 0 "keine_Funktion" 1 "Programm_1" 2 "Programm_2" 3 "Programm_3" 4 "Programm_4" 5 "Programm_5" 6 "Programm_6" 7 "Programm_7" 8 "Programm_8" 9 "Programm_9" 10 "Programm_10" 11 "Programm_11" 12 "Programm_12" 13 "Programm_13" 14 "Programm_14" 15 "Programm_15" ;
VAL_ 1000 CHA_Ziel_FahrPr_HDC 0 "keine_Funktion" 1 "Programm_1" 2 "Programm_2" 3 "Programm_3" 4 "Programm_4" 5 "Programm_5" 6 "Programm_6" 7 "Programm_7" 8 "Programm_8" 9 "Programm_9" 10 "Programm_10" 11 "Programm_11" 12 "Programm_12" 13 "Programm_13" 14 "Programm_14" 15 "Programm_15" ;
VAL_ 1000 CHA_Ziel_FahrPr_EAR 0 "keine_Funktion" 1 "Programm_1" 2 "Programm_2" 3 "Programm_3" 4 "Programm_4" 5 "Programm_5" 6 "Programm_6" 7 "Programm_7" 8 "Programm_8" 9 "Programm_9" 10 "Programm_10" 11 "Programm_11" 12 "Programm_12" 13 "Programm_13" 14 "Programm_14" 15 "Programm_15" ;
VAL_ 1000 CHA_Ziel_FahrPr_AEB 0 "keine_Funktion" 1 "Programm_1" 2 "Programm_2" 3 "Programm_3" 4 "Programm_4" 5 "Programm_5" 6 "Programm_6" 7 "Programm_7" 8 "Programm_8" 9 "Programm_9" 10 "Programm_10" 11 "Programm_11" 12 "Programm_12" 13 "Programm_13" 14 "Programm_14" 15 "Programm_15" ;
VAL_ 1000 CHA_Ziel_FahrPr_FCWO 0 "keine_Funktion" 1 "Programm_1" 2 "Programm_2" 3 "Programm_3" 4 "Programm_4" 5 "Programm_5" 6 "Programm_6" 7 "Programm_7" 8 "Programm_8" 9 "Programm_9" 10 "Programm_10" 11 "Programm_11" 12 "Programm_12" 13 "Programm_13" 14 "Programm_14" 15 "Programm_15" ;
VAL_ 1000 CHA_Ziel_FahrPr_FCWP 0 "keine_Funktion" 1 "Programm_1" 2 "Programm_2" 3 "Programm_3" 4 "Programm_4" 5 "Programm_5" 6 "Programm_6" 7 "Programm_7" 8 "Programm_8" 9 "Programm_9" 10 "Programm_10" 11 "Programm_11" 12 "Programm_12" 13 "Programm_13" 14 "Programm_14" 15 "Programm_15" ;
VAL_ 1022 CHA_Fahrer_Umschaltung 0 "keine_oder_automatische_Umschaltung" 1 "manuelle_Umschaltung" ;
VAL_ 1022 CHA_Fahrer_Umschaltung_BMA 0 "keine_oder_autom_Umschaltung" 1 "manuelle_Umschaltung" ;
VAL_ 1022 CHA_Ziel_FahrPr_MO_Freilauf 0 "keine_Funktion" 1 "Programm_1" 2 "Programm_2" 3 "Programm_3" 4 "Programm_4" 5 "Programm_5" 6 "Programm_6" 7 "Programm_7" 8 "Programm_8" 9 "Programm_9" 10 "Programm_10" 11 "Programm_11" 12 "Programm_12" 13 "Programm_13" 14 "Programm_14" 15 "Programm_15" ;
VAL_ 1022 CHA_Ziel_FahrPr_BMS 0 "keine_Funktion" 1 "Programm_1" 2 "Programm_2" 3 "Programm_3" 4 "Programm_4" 5 "Programm_5" 6 "Programm_6" 7 "Programm_7" 8 "Programm_8" 9 "Programm_9" 10 "Programm_10" 11 "Programm_11" 12 "Programm_12" 13 "Programm_13" 14 "Programm_14" 15 "Programm_15" ;
VAL_ 1022 CHA_Current_Mode_BMA 0 "keine_Funktion" 1 "Programm_1" 2 "Programm_2" 3 "Programm_3" 4 "Programm_4" 5 "Programm_5" 6 "Programm_6" 7 "Programm_7" 8 "Programm_8" 9 "Programm_9" 10 "Programm_10" 11 "Programm_11" 12 "Programm_12" 13 "Programm_13" 14 "Programm_14" 15 "Programm_15" ;
VAL_ 1022 CHA_Ziel_FahrPr_PDC 0 "keine_Funktion" 1 "Programm_1" 2 "Programm_2" 3 "Programm_3" 4 "Programm_4" 5 "Programm_5" 6 "Programm_6" 7 "Programm_7" 8 "Programm_8" 9 "Programm_9" 10 "Programm_10" 11 "Programm_11" 12 "Programm_12" 13 "Programm_13" 14 "Programm_14" 15 "Programm_15" ;
VAL_ 1022 CHA_Ziel_FahrPr_HHC 0 "keine_Funktion" 1 "Programm_1" 2 "Programm_2" 3 "Programm_3" 4 "Programm_4" 5 "Programm_5" 6 "Programm_6" 7 "Programm_7" 8 "Programm_8" 9 "Programm_9" 10 "Programm_10" 11 "Programm_11" 12 "Programm_12" 13 "Programm_13" 14 "Programm_14" 15 "Programm_15" ;
VAL_ 1022 CHA_Ziel_FahrPr_EDS 0 "keine_Funktion" 1 "Programm_1" 2 "Programm_2" 3 "Programm_3" 4 "Programm_4" 5 "Programm_5" 6 "Programm_6" 7 "Programm_7" 8 "Programm_8" 9 "Programm_9" 10 "Programm_10" 11 "Programm_11" 12 "Programm_12" 13 "Programm_13" 14 "Programm_14" 15 "Programm_15" ;
VAL_ 1022 CHA_Ziel_FahrPr_PACC 0 "keine_Funktion" 1 "Programm_1" 2 "Programm_2" 3 "Programm_3" 4 "Programm_4" 5 "Programm_5" 6 "Programm_6" 7 "Programm_7" 8 "Programm_8" 9 "Programm_9" 10 "Programm_10" 11 "Programm_11" 12 "Programm_12" 13 "Programm_13" 14 "Programm_14" 15 "Programm_15" ;
VAL_ 1022 CHA_Ziel_FahrPr_AGK 0 "keine_Funktion" 1 "Programm_1" 2 "Programm_2" 3 "Programm_3" 4 "Programm_4" 5 "Programm_5" 6 "Programm_6" 7 "Programm_7" 8 "Programm_8" 9 "Programm_9" 10 "Programm_10" 11 "Programm_11" 12 "Programm_12" 13 "Programm_13" 14 "Programm_14" 15 "Programm_15" ;
VAL_ 918 DR_Systemstatus 0 "Init oder kein Wert verfuegbar" 1 "Komfortabel" 2 "Normal" 3 "Sport 1" 4 "Sport 2" 5 "nicht funktionsfähig" 6 "Funktionseinschränkung aktiv" 7 "Notfahrfunktion" ;
VAL_ 918 LF_Texte 0 "keine_Anzeige" 1 "Text_Fahrzeug_momentan_zu_tief_Regelung_laeuft" 2 "Text_Fahrzeug_momentan_zu_hoch_Regelung_laeuft" 3 "Text_Niveauregelung_abgeschaltet" ;
VAL_ 918 DR_Taster 0 "Taster nicht gedrückt" 1 "Taster gedrückt" ;
VAL_ 918 DR_Gelbe_Warnlampe 0 "Warnlampe aus" 1 "Warnlampe ein (Aufprüfen)" 2 "Warnlampe an (Warnung)" 3 "reserviert" ;
VAL_ 918 DR_Daempferreg_Texte 0 "kein Text" 1 "Daempfer_Sport" 2 "Daempfer_Basis" 3 "Daempfer_Comfort" 15 "Verlademodus" ;
VAL_ 918 DR_Charisma_FahrPr 0 "keine_Funktion" 1 "Programm_1" 2 "Programm_2" 3 "Programm_3" 4 "Programm_4" 5 "Programm_5" 6 "Programm_6" 7 "Programm_7" 8 "Programm_8" 9 "Programm_9" 10 "Programm_10" 11 "Programm_11" 12 "Programm_12" 13 "Programm_13" 14 "Programm_14" 15 "Programm_15" ;
VAL_ 918 DR_Charisma_Status 0 "Init" 1 "verfuegbar" 2 "nicht_verfuegbar" 3 "asynchron_durch_Fahrerwunsch" ;
VAL_ 918 DR_Fahrzeugart 0 "Stahl + PASM" 1 "Luftfederung + PASM" 2 "Stahl + PASM + PADM  " 3 "Stahl + PADM " ;
VAL_ 918 LF_Warnung_Prio1 0 "keine_Anzeige" 1 "Text_Servicemodus" 2 "Text_Fehler_Luftfeder_Geschwindigkeit_1" 3 "Text_Fehler_Luftfeder_Geschwindigkeit_2" ;
VAL_ 918 LF_Warnung_Prio2 0 "keine_Anzeige" 1 "Text_Fahrzeug_zu_tief_Bodenfreiheit_eingeschraenkt" 2 "Text_Fehler_Luftfeder" 3 "tbd" ;
VAL_ 918 DR_DynAGL_Warnlampe 0 "Warnlampe aus" 1 "Warnlampe ein" ;
VAL_ 918 DR_Rote_Warnlampe 0 "Warnlampe aus" 1 "Warnlampe ein (Aufprüfen)" 2 "Warnlampe an (Warnung)" 3 "reserviert" ;
VAL_ 918 NI_Status 0 "Eingefahren" 1 "Ausgefahren" 2 "heben" 3 "senken" 4 "blockiert" 5 "gesperrt" 7 "Fehler" ;
VAL_ 918 NR_Niveaufunktion_aktiv 0 "keine_Umschaltung_erfolgt" 3 "lift_aktiv" ;
VAL_ 918 DR_DynAGL_Anf_im_Leerlauf 0 "inaktiv" 1 "aktiv" ;
VAL_ 918 DR_DynAGL_Anf_Entkopplung 0 "inaktiv" 1 "aktiv" ;
